AUTOSAR XML (schema 4-2-2)
package /STELLANTIS/EPT/ASWCs
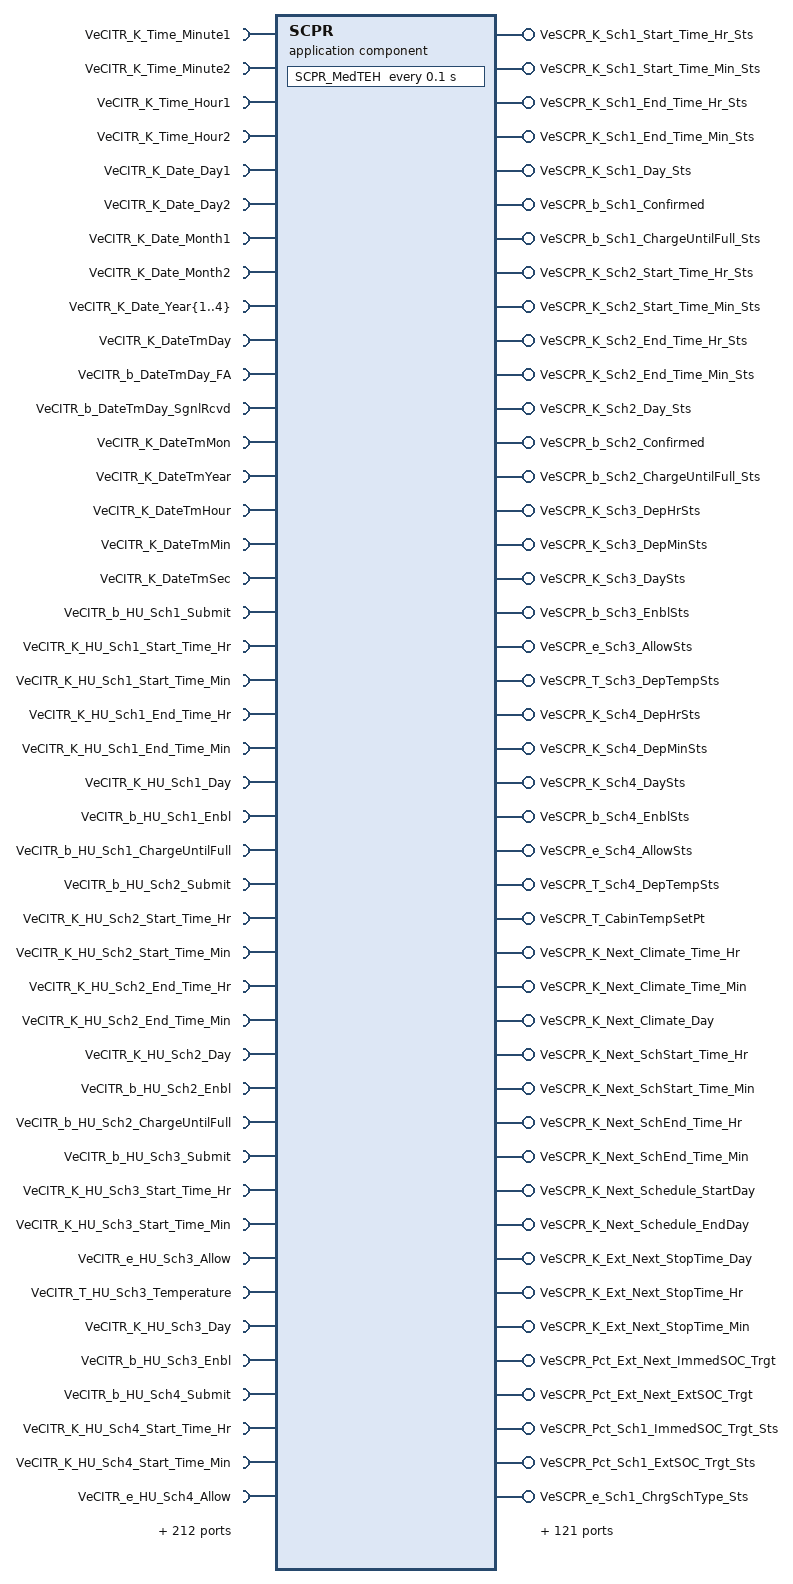
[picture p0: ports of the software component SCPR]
  application sw component type SCPR
    172 x require port:
      VeCITR_K_Time_Minute1: variation-point={short-label=vpVeCITR_K_Time_Minute1, sw-syscond=1}, nonqueued-receiver-com-spec{data-element=Value, init-value=0}, required-interface=VeCITR_K_Time_Minute1
      VeCITR_K_Time_Minute2: variation-point={short-label=vpVeCITR_K_Time_Minute2, sw-syscond=1}, nonqueued-receiver-com-spec{data-element=Value, init-value=0}, required-interface=VeCITR_K_Time_Minute2
      VeCITR_K_Time_Hour1: variation-point={short-label=vpVeCITR_K_Time_Hour1, sw-syscond=1}, nonqueued-receiver-com-spec{data-element=Value, init-value=0}, required-interface=VeCITR_K_Time_Hour1
      VeCITR_K_Time_Hour2: variation-point={short-label=vpVeCITR_K_Time_Hour2, sw-syscond=1}, nonqueued-receiver-com-spec{data-element=Value, init-value=0}, required-interface=VeCITR_K_Time_Hour2
      VeCITR_K_Date_Day1: variation-point={short-label=vpVeCITR_K_Date_Day1, sw-syscond=1}, nonqueued-receiver-com-spec{data-element=Value, init-value=0}, required-interface=VeCITR_K_Date_Day1
      VeCITR_K_Date_Day2: variation-point={short-label=vpVeCITR_K_Date_Day2, sw-syscond=1}, nonqueued-receiver-com-spec{data-element=Value, init-value=0}, required-interface=VeCITR_K_Date_Day2
      VeCITR_K_Date_Month1: variation-point={short-label=vpVeCITR_K_Date_Month1, sw-syscond=1}, nonqueued-receiver-com-spec{data-element=Value, init-value=0}, required-interface=VeCITR_K_Date_Month1
      VeCITR_K_Date_Month2: variation-point={short-label=vpVeCITR_K_Date_Month2, sw-syscond=1}, nonqueued-receiver-com-spec{data-element=Value, init-value=0}, required-interface=VeCITR_K_Date_Month2
      VeCITR_K_Date_Year{1..4}: variation-point={short-label=vpVeCITR_K_Date_Year{1..4}, sw-syscond=1}, nonqueued-receiver-com-spec{data-element=Value, init-value=0}, required-interface=VeCITR_K_Date_Year{1..4}
      VeCITR_K_DateTmDay: variation-point={short-label=vpVeCITR_K_DateTmDay, sw-syscond=1}, nonqueued-receiver-com-spec{data-element=Value, init-value=0}, required-interface=VeCITR_K_DateTmDay
      VeCITR_b_DateTmDay_FA: variation-point={short-label=vpVeCITR_b_DateTmDay_FA, sw-syscond=1}, nonqueued-receiver-com-spec{data-element=Value, init-value=0}, required-interface=VeCITR_b_DateTmDay_FA
      VeCITR_b_DateTmDay_SgnlRcvd: variation-point={short-label=vpVeCITR_b_DateTmDay_SgnlRcvd, sw-syscond=1}, nonqueued-receiver-com-spec{data-element=Value, init-value=0}, required-interface=VeCITR_b_DateTmDay_SgnlRcvd
      VeCITR_K_DateTmMon: variation-point={short-label=vpVeCITR_K_DateTmMon, sw-syscond=1}, nonqueued-receiver-com-spec{data-element=Value, init-value=0}, required-interface=VeCITR_K_DateTmMon
      VeCITR_K_DateTmYear: variation-point={short-label=vpVeCITR_K_DateTmYear, sw-syscond=1}, nonqueued-receiver-com-spec{data-element=Value, init-value=0}, required-interface=VeCITR_K_DateTmYear
      VeCITR_K_DateTmHour: variation-point={short-label=vpVeCITR_K_DateTmHour, sw-syscond=1}, nonqueued-receiver-com-spec{data-element=Value, init-value=0}, required-interface=VeCITR_K_DateTmHour
      VeCITR_K_DateTmMin: variation-point={short-label=vpVeCITR_K_DateTmMin, sw-syscond=1}, nonqueued-receiver-com-spec{data-element=Value, init-value=0}, required-interface=VeCITR_K_DateTmMin
      VeCITR_K_DateTmSec: variation-point={short-label=vpVeCITR_K_DateTmSec, sw-syscond=1}, nonqueued-receiver-com-spec{data-element=Value, init-value=0}, required-interface=VeCITR_K_DateTmSec
      VeCITR_b_HU_Sch1_Submit: variation-point={short-label=vpVeCITR_b_HU_Sch1_Submit, sw-syscond=1}, nonqueued-receiver-com-spec{data-element=Value, init-value=0}, required-interface=VeCITR_b_HU_Sch1_Submit
      VeCITR_K_HU_Sch1_Start_Time_Hr: variation-point={short-label=vpVeCITR_K_HU_Sch1_Start_Time_Hr, sw-syscond=1}, nonqueued-receiver-com-spec{data-element=Value, init-value=0}, required-interface=VeCITR_K_HU_Sch1_Start_Time_Hr
      VeCITR_K_HU_Sch1_Start_Time_Min: variation-point={short-label=vpVeCITR_K_HU_Sch1_Start_Time_Min, sw-syscond=1}, nonqueued-receiver-com-spec{data-element=Value, init-value=0}, required-interface=VeCITR_K_HU_Sch1_Start_Time_Min
      VeCITR_K_HU_Sch1_End_Time_Hr: variation-point={short-label=vpVeCITR_K_HU_Sch1_End_Time_Hr, sw-syscond=1}, nonqueued-receiver-com-spec{data-element=Value, init-value=0}, required-interface=VeCITR_K_HU_Sch1_End_Time_Hr
      VeCITR_K_HU_Sch1_End_Time_Min: variation-point={short-label=vpVeCITR_K_HU_Sch1_End_Time_Min, sw-syscond=1}, nonqueued-receiver-com-spec{data-element=Value, init-value=0}, required-interface=VeCITR_K_HU_Sch1_End_Time_Min
      VeCITR_K_HU_Sch1_Day: variation-point={short-label=vpVeCITR_K_HU_Sch1_Day, sw-syscond=1}, nonqueued-receiver-com-spec{data-element=Value, init-value=0}, required-interface=VeCITR_K_HU_Sch1_Day
      VeCITR_b_HU_Sch1_Enbl: variation-point={short-label=vpVeCITR_b_HU_Sch1_Enbl, sw-syscond=1}, nonqueued-receiver-com-spec{data-element=Value, init-value=0}, required-interface=VeCITR_b_HU_Sch1_Enbl
      VeCITR_b_HU_Sch1_ChargeUntilFull: variation-point={short-label=vpVeCITR_b_HU_Sch1_ChargeUntilFull, sw-syscond=1}, nonqueued-receiver-com-spec{data-element=Value, init-value=0}, required-interface=VeCITR_b_HU_Sch1_ChargeUntilFull
      VeCITR_b_HU_Sch2_Submit: variation-point={short-label=vpVeCITR_b_HU_Sch2_Submit, sw-syscond=1}, nonqueued-receiver-com-spec{data-element=Value, init-value=0}, required-interface=VeCITR_b_HU_Sch2_Submit
      VeCITR_K_HU_Sch2_Start_Time_Hr: variation-point={short-label=vpVeCITR_K_HU_Sch2_Start_Time_Hr, sw-syscond=1}, nonqueued-receiver-com-spec{data-element=Value, init-value=0}, required-interface=VeCITR_K_HU_Sch2_Start_Time_Hr
      VeCITR_K_HU_Sch2_Start_Time_Min: variation-point={short-label=vpVeCITR_K_HU_Sch2_Start_Time_Min, sw-syscond=1}, nonqueued-receiver-com-spec{data-element=Value, init-value=0}, required-interface=VeCITR_K_HU_Sch2_Start_Time_Min
      VeCITR_K_HU_Sch2_End_Time_Hr: variation-point={short-label=vpVeCITR_K_HU_Sch2_End_Time_Hr, sw-syscond=1}, nonqueued-receiver-com-spec{data-element=Value, init-value=0}, required-interface=VeCITR_K_HU_Sch2_End_Time_Hr
      VeCITR_K_HU_Sch2_End_Time_Min: variation-point={short-label=vpVeCITR_K_HU_Sch2_End_Time_Min, sw-syscond=1}, nonqueued-receiver-com-spec{data-element=Value, init-value=0}, required-interface=VeCITR_K_HU_Sch2_End_Time_Min
      VeCITR_K_HU_Sch2_Day: variation-point={short-label=vpVeCITR_K_HU_Sch2_Day, sw-syscond=1}, nonqueued-receiver-com-spec{data-element=Value, init-value=0}, required-interface=VeCITR_K_HU_Sch2_Day
      VeCITR_b_HU_Sch2_Enbl: variation-point={short-label=vpVeCITR_b_HU_Sch2_Enbl, sw-syscond=1}, nonqueued-receiver-com-spec{data-element=Value, init-value=0}, required-interface=VeCITR_b_HU_Sch2_Enbl
      VeCITR_b_HU_Sch2_ChargeUntilFull: variation-point={short-label=vpVeCITR_b_HU_Sch2_ChargeUntilFull, sw-syscond=1}, nonqueued-receiver-com-spec{data-element=Value, init-value=0}, required-interface=VeCITR_b_HU_Sch2_ChargeUntilFull
      VeCITR_b_HU_Sch3_Submit: variation-point={short-label=vpVeCITR_b_HU_Sch3_Submit, sw-syscond=1}, nonqueued-receiver-com-spec{data-element=Value, init-value=0}, required-interface=VeCITR_b_HU_Sch3_Submit
      VeCITR_K_HU_Sch3_Start_Time_Hr: variation-point={short-label=vpVeCITR_K_HU_Sch3_Start_Time_Hr, sw-syscond=1}, nonqueued-receiver-com-spec{data-element=Value, init-value=0}, required-interface=VeCITR_K_HU_Sch3_Start_Time_Hr
      VeCITR_K_HU_Sch3_Start_Time_Min: variation-point={short-label=vpVeCITR_K_HU_Sch3_Start_Time_Min, sw-syscond=1}, nonqueued-receiver-com-spec{data-element=Value, init-value=0}, required-interface=VeCITR_K_HU_Sch3_Start_Time_Min
      VeCITR_e_HU_Sch3_Allow: variation-point={short-label=vpVeCITR_e_HU_Sch3_Allow, sw-syscond=1}, nonqueued-receiver-com-spec{data-element=Value, init-value=CeCITR_e_AnyTime}, required-interface=VeCITR_e_HU_Sch3_Allow
      VeCITR_T_HU_Sch3_Temperature: variation-point={short-label=vpVeCITR_T_HU_Sch3_Temperature, sw-syscond=1}, nonqueued-receiver-com-spec{data-element=Value, init-value=0}, required-interface=VeCITR_T_HU_Sch3_Temperature
      VeCITR_K_HU_Sch3_Day: variation-point={short-label=vpVeCITR_K_HU_Sch3_Day, sw-syscond=1}, nonqueued-receiver-com-spec{data-element=Value, init-value=0}, required-interface=VeCITR_K_HU_Sch3_Day
      VeCITR_b_HU_Sch3_Enbl: variation-point={short-label=vpVeCITR_b_HU_Sch3_Enbl, sw-syscond=1}, nonqueued-receiver-com-spec{data-element=Value, init-value=0}, required-interface=VeCITR_b_HU_Sch3_Enbl
      VeCITR_b_HU_Sch4_Submit: variation-point={short-label=vpVeCITR_b_HU_Sch4_Submit, sw-syscond=1}, nonqueued-receiver-com-spec{data-element=Value, init-value=0}, required-interface=VeCITR_b_HU_Sch4_Submit
      VeCITR_K_HU_Sch4_Start_Time_Hr: variation-point={short-label=vpVeCITR_K_HU_Sch4_Start_Time_Hr, sw-syscond=1}, nonqueued-receiver-com-spec{data-element=Value, init-value=0}, required-interface=VeCITR_K_HU_Sch4_Start_Time_Hr
      VeCITR_K_HU_Sch4_Start_Time_Min: variation-point={short-label=vpVeCITR_K_HU_Sch4_Start_Time_Min, sw-syscond=1}, nonqueued-receiver-com-spec{data-element=Value, init-value=0}, required-interface=VeCITR_K_HU_Sch4_Start_Time_Min
      VeCITR_e_HU_Sch4_Allow: variation-point={short-label=vpVeCITR_e_HU_Sch4_Allow, sw-syscond=1}, nonqueued-receiver-com-spec{data-element=Value, init-value=CeCITR_e_AnyTime}, required-interface=VeCITR_e_HU_Sch4_Allow
      VeCITR_T_HU_Sch4_Temperature: variation-point={short-label=vpVeCITR_T_HU_Sch4_Temperature, sw-syscond=1}, nonqueued-receiver-com-spec{data-element=Value, init-value=0}, required-interface=VeCITR_T_HU_Sch4_Temperature
      VeCITR_K_HU_Sch4_Day: variation-point={short-label=vpVeCITR_K_HU_Sch4_Day, sw-syscond=1}, nonqueued-receiver-com-spec{data-element=Value, init-value=0}, required-interface=VeCITR_K_HU_Sch4_Day
      VeCITR_b_HU_Sch4_Enbl: variation-point={short-label=vpVeCITR_b_HU_Sch4_Enbl, sw-syscond=1}, nonqueued-receiver-com-spec{data-element=Value, init-value=0}, required-interface=VeCITR_b_HU_Sch4_Enbl
      VeCITR_b_Date_Day1_FA: variation-point={short-label=vpVeCITR_b_Date_Day1_FA, sw-syscond=1}, nonqueued-receiver-com-spec{data-element=Value, init-value=0}, required-interface=VeCITR_b_Date_Day1_FA
      VeCITR_b_Date_Day1_SgnlRcvd: variation-point={short-label=vpVeCITR_b_Date_Day1_SgnlRcvd, sw-syscond=1}, nonqueued-receiver-com-spec{data-element=Value, init-value=0}, required-interface=VeCITR_b_Date_Day1_SgnlRcvd
      VeCITR_b_HU_Sch1_Day_FA: variation-point={short-label=vpVeCITR_b_HU_Sch1_Day_FA, sw-syscond=1}, nonqueued-receiver-com-spec{data-element=Value, init-value=0}, required-interface=VeCITR_b_HU_Sch1_Day_FA
      VeCITR_b_HU_Sch1_Day_SgnlRcvd: variation-point={short-label=vpVeCITR_b_HU_Sch1_Day_SgnlRcvd, sw-syscond=1}, nonqueued-receiver-com-spec{data-element=Value, init-value=0}, required-interface=VeCITR_b_HU_Sch1_Day_SgnlRcvd
      VeCITR_b_TBM_Sch1_Day_FA: variation-point={short-label=vpVeCITR_b_TBM_Sch1_Day_FA, sw-syscond=1}, nonqueued-receiver-com-spec{data-element=Value, init-value=0}, required-interface=VeCITR_b_TBM_Sch1_Day_FA
      VeCITR_b_TBM_Sch1_Day_SgnlRcvd: variation-point={short-label=vpVeCITR_b_TBM_Sch1_Day_SgnlRcvd, sw-syscond=1}, nonqueued-receiver-com-spec{data-element=Value, init-value=0}, required-interface=VeCITR_b_TBM_Sch1_Day_SgnlRcvd
      VeCITR_b_HU_Sch2_Day_FA: variation-point={short-label=vpVeCITR_b_HU_Sch2_Day_FA, sw-syscond=1}, nonqueued-receiver-com-spec{data-element=Value, init-value=0}, required-interface=VeCITR_b_HU_Sch2_Day_FA
      VeCITR_b_HU_Sch2_Day_SgnlRcvd: variation-point={short-label=vpVeCITR_b_HU_Sch2_Day_SgnlRcvd, sw-syscond=1}, nonqueued-receiver-com-spec{data-element=Value, init-value=0}, required-interface=VeCITR_b_HU_Sch2_Day_SgnlRcvd
      VeCITR_b_TBM_Sch2_Day_FA: variation-point={short-label=vpVeCITR_b_TBM_Sch2_Day_FA, sw-syscond=1}, nonqueued-receiver-com-spec{data-element=Value, init-value=0}, required-interface=VeCITR_b_TBM_Sch2_Day_FA
      VeCITR_b_TBM_Sch2_Day_SgnlRcvd: variation-point={short-label=vpVeCITR_b_TBM_Sch2_Day_SgnlRcvd, sw-syscond=1}, nonqueued-receiver-com-spec{data-element=Value, init-value=0}, required-interface=VeCITR_b_TBM_Sch2_Day_SgnlRcvd
      VeCITR_b_HU_Sch3_Day_FA: variation-point={short-label=vpVeCITR_b_HU_Sch3_Day_FA, sw-syscond=1}, nonqueued-receiver-com-spec{data-element=Value, init-value=0}, required-interface=VeCITR_b_HU_Sch3_Day_FA
      VeCITR_b_HU_Sch3_Day_SgnlRcvd: variation-point={short-label=vpVeCITR_b_HU_Sch3_Day_SgnlRcvd, sw-syscond=1}, nonqueued-receiver-com-spec{data-element=Value, init-value=0}, required-interface=VeCITR_b_HU_Sch3_Day_SgnlRcvd
      VeCITR_b_TBM_Sch3_Day_FA: variation-point={short-label=vpVeCITR_b_TBM_Sch3_Day_FA, sw-syscond=1}, nonqueued-receiver-com-spec{data-element=Value, init-value=0}, required-interface=VeCITR_b_TBM_Sch3_Day_FA
      VeCITR_b_TBM_Sch3_Day_SgnlRcvd: variation-point={short-label=vpVeCITR_b_TBM_Sch3_Day_SgnlRcvd, sw-syscond=1}, nonqueued-receiver-com-spec{data-element=Value, init-value=0}, required-interface=VeCITR_b_TBM_Sch3_Day_SgnlRcvd
      VeCITR_b_HU_Sch4_Day_FA: variation-point={short-label=vpVeCITR_b_HU_Sch4_Day_FA, sw-syscond=1}, nonqueued-receiver-com-spec{data-element=Value, init-value=0}, required-interface=VeCITR_b_HU_Sch4_Day_FA
      VeCITR_b_HU_Sch4_Day_SgnlRcvd: variation-point={short-label=vpVeCITR_b_HU_Sch4_Day_SgnlRcvd, sw-syscond=1}, nonqueued-receiver-com-spec{data-element=Value, init-value=0}, required-interface=VeCITR_b_HU_Sch4_Day_SgnlRcvd
      VeCITR_b_TBM_Sch4_Day_FA: variation-point={short-label=vpVeCITR_b_TBM_Sch4_Day_FA, sw-syscond=1}, nonqueued-receiver-com-spec{data-element=Value, init-value=0}, required-interface=VeCITR_b_TBM_Sch4_Day_FA
      VeCITR_b_TBM_Sch4_Day_SgnlRcvd: variation-point={short-label=vpVeCITR_b_TBM_Sch4_Day_SgnlRcvd, sw-syscond=1}, nonqueued-receiver-com-spec{data-element=Value, init-value=0}, required-interface=VeCITR_b_TBM_Sch4_Day_SgnlRcvd
      VeCITR_b_HU_Sch1_Start_Time_HrFA: variation-point={short-label=vpVeCITR_b_HU_Sch1_Start_Time_HrFA, sw-syscond=1}, nonqueued-receiver-com-spec{data-element=Value, init-value=0}, required-interface=VeCITR_b_HU_Sch1_Start_Time_HrFA
      VeCITR_b_HU_Sch1_Start_Time_MinFA: variation-point={short-label=vpVeCITR_b_HU_Sch1_Start_Time_MinFA, sw-syscond=1}, nonqueued-receiver-com-spec{data-element=Value, init-value=0}, required-interface=VeCITR_b_HU_Sch1_Start_Time_MinFA
      VeCITR_b_HU_Sch1_End_Time_HrFA: variation-point={short-label=vpVeCITR_b_HU_Sch1_End_Time_HrFA, sw-syscond=1}, nonqueued-receiver-com-spec{data-element=Value, init-value=0}, required-interface=VeCITR_b_HU_Sch1_End_Time_HrFA
      VeCITR_b_HU_Sch1_End_Time_MinFA: variation-point={short-label=vpVeCITR_b_HU_Sch1_End_Time_MinFA, sw-syscond=1}, nonqueued-receiver-com-spec{data-element=Value, init-value=0}, required-interface=VeCITR_b_HU_Sch1_End_Time_MinFA
      VeCITR_b_HU_Sch2_Start_Time_HrFA: variation-point={short-label=vpVeCITR_b_HU_Sch2_Start_Time_HrFA, sw-syscond=1}, nonqueued-receiver-com-spec{data-element=Value, init-value=0}, required-interface=VeCITR_b_HU_Sch2_Start_Time_HrFA
      VeCITR_b_HU_Sch2_Start_Time_MinFA: variation-point={short-label=vpVeCITR_b_HU_Sch2_Start_Time_MinFA, sw-syscond=1}, nonqueued-receiver-com-spec{data-element=Value, init-value=0}, required-interface=VeCITR_b_HU_Sch2_Start_Time_MinFA
      VeCITR_b_HU_Sch2_End_Time_HrFA: variation-point={short-label=vpVeCITR_b_HU_Sch2_End_Time_HrFA, sw-syscond=1}, nonqueued-receiver-com-spec{data-element=Value, init-value=0}, required-interface=VeCITR_b_HU_Sch2_End_Time_HrFA
      VeCITR_b_HU_Sch2_End_Time_MinFA: variation-point={short-label=vpVeCITR_b_HU_Sch2_End_Time_MinFA, sw-syscond=1}, nonqueued-receiver-com-spec{data-element=Value, init-value=0}, required-interface=VeCITR_b_HU_Sch2_End_Time_MinFA
      VeCITR_b_HU_Sch3_Start_Time_HrFA: variation-point={short-label=vpVeCITR_b_HU_Sch3_Start_Time_HrFA, sw-syscond=1}, nonqueued-receiver-com-spec{data-element=Value, init-value=0}, required-interface=VeCITR_b_HU_Sch3_Start_Time_HrFA
      VeCITR_b_HU_Sch3_Start_Time_MinFA: variation-point={short-label=vpVeCITR_b_HU_Sch3_Start_Time_MinFA, sw-syscond=1}, nonqueued-receiver-com-spec{data-element=Value, init-value=0}, required-interface=VeCITR_b_HU_Sch3_Start_Time_MinFA
      VeCITR_b_HU_Sch4_Start_Time_HrFA: variation-point={short-label=vpVeCITR_b_HU_Sch4_Start_Time_HrFA, sw-syscond=1}, nonqueued-receiver-com-spec{data-element=Value, init-value=0}, required-interface=VeCITR_b_HU_Sch4_Start_Time_HrFA
      VeCITR_b_HU_Sch4_Start_Time_MinFA: variation-point={short-label=vpVeCITR_b_HU_Sch4_Start_Time_MinFA, sw-syscond=1}, nonqueued-receiver-com-spec{data-element=Value, init-value=0}, required-interface=VeCITR_b_HU_Sch4_Start_Time_MinFA
      VeOBCR_e_ChargingSystemSts: variation-point={short-label=vpVeOBCR_e_ChargingSystemSts, sw-syscond=1}, nonqueued-receiver-com-spec{data-element=Value, init-value=CeOBCR_e_NotCharging}, required-interface=VeOBCR_e_ChargingSystemSts
      VeOBCR_b_PluggedIn: variation-point={short-label=vpVeOBCR_b_PluggedIn, sw-syscond=1}, nonqueued-receiver-com-spec{data-element=Value, init-value=0}, required-interface=VeOBCR_b_PluggedIn
      VePMDR_e_PMM_PowerMode: variation-point={short-label=vpVePMDR_e_PMM_PowerMode, sw-syscond=1}, nonqueued-receiver-com-spec{data-element=Value, init-value=CePMDR_e_PowerMode_Off}, required-interface=VePMDR_e_PMM_PowerMode
      VeOBCR_b_SmartEvse_Dtctd: variation-point={short-label=vpVeOBCR_b_SmartEvse_Dtctd, sw-syscond=1}, nonqueued-receiver-com-spec{data-element=Value, init-value=0}, required-interface=VeOBCR_b_SmartEvse_Dtctd
      VeBPCR_Pct_HV_BatPackSOC_Arb: variation-point={short-label=vpVeBPCR_Pct_HV_BatPackSOC_Arb, sw-syscond=1}, nonqueued-receiver-com-spec{data-element=Value, init-value=0}, required-interface=VeBPCR_Pct_HV_BatPackSOC_Arb
      VeSSDR_b_HVBatPerWUThermal: variation-point={short-label=vpVeSSDR_b_HVBatPerWUThermal, sw-syscond=1}, nonqueued-receiver-com-spec{data-element=Value, init-value=0}, required-interface=VeSSDR_b_HVBatPerWUThermal
      VeTHMR_b_RdyForShtDwn: variation-point={short-label=vpVeTHMR_b_RdyForShtDwn, sw-syscond=1}, nonqueued-receiver-com-spec{data-element=Value, init-value=0}, required-interface=VeTHMR_b_RdyForShtDwn
      VeOBCR_e_ChargingLevel: variation-point={short-label=vpVeOBCR_e_ChargingLevel, sw-syscond=1}, nonqueued-receiver-com-spec{data-element=Value, init-value=CeOBCR_e_ChargingLvlDefault}, required-interface=VeOBCR_e_ChargingLevel
      VePLTR_b_ChargeReqSgnlRcvd: variation-point={short-label=vpVePLTR_b_ChargeReqSgnlRcvd, sw-syscond=1}, nonqueued-receiver-com-spec{data-element=Value, init-value=0}, required-interface=VePLTR_b_ChargeReqSgnlRcvd
      VePLTR_b_ChargeReq: variation-point={short-label=vpVePLTR_b_ChargeReq, sw-syscond=1}, nonqueued-receiver-com-spec{data-element=Value, init-value=0}, required-interface=VePLTR_b_ChargeReq
      VeCITR_b_ChargeNow: variation-point={short-label=vpVeCITR_b_ChargeNow, sw-syscond=1}, nonqueued-receiver-com-spec{data-element=Value, init-value=0}, required-interface=VeCITR_b_ChargeNow
      VeCITR_b_ChrgPortButton_Sts: variation-point={short-label=vpVeCITR_b_ChrgPortButton_Sts, sw-syscond=1}, nonqueued-receiver-com-spec{data-element=Value, init-value=0}, required-interface=VeCITR_b_ChrgPortButton_Sts
      VeCITR_e_DoorLockLastElSts: variation-point={short-label=vpVeCITR_e_DoorLockLastElSts, sw-syscond=1}, nonqueued-receiver-com-spec{data-element=Value, init-value=CeOBCR_e_LKD}, required-interface=VeCITR_e_DoorLockLastElSts
      VePLTR_t_RTC_CurrentTime: variation-point={short-label=vpVePLTR_t_RTC_CurrentTime, sw-syscond=1}, nonqueued-receiver-com-spec{data-element=Value, init-value=0}, required-interface=VePLTR_t_RTC_CurrentTime
      VeIDCR_I_ChrgCrntAvail: variation-point={short-label=vpVeIDCR_I_ChrgCrntAvail, sw-syscond=1}, nonqueued-receiver-com-spec{data-element=Value, init-value=0}, required-interface=VeIDCR_I_ChrgCrntAvail
      VeBPCR_q_FullAmpHrCap: variation-point={short-label=vpVeBPCR_q_FullAmpHrCap, sw-syscond=1}, nonqueued-receiver-com-spec{data-element=Value, init-value=0}, required-interface=VeBPCR_q_FullAmpHrCap
      VeCITR_e_RRM_VP_Level: variation-point={short-label=vpVeCITR_e_RRM_VP_Level, sw-syscond=1}, nonqueued-receiver-com-spec{data-element=Value, init-value=CeCITR_e_RRM_VP_Absent}, required-interface=VeCITR_e_RRM_VP_Level
      VeSSDR_b_HV_PerWU_CabinPre: variation-point={short-label=vpVeSSDR_b_HV_PerWU_CabinPre, sw-syscond=1}, nonqueued-receiver-com-spec{data-element=Value, init-value=0}, required-interface=VeSSDR_b_HV_PerWU_CabinPre
      VeOBCR_b_ChrgSysFault: variation-point={short-label=vpVeOBCR_b_ChrgSysFault, sw-syscond=1}, nonqueued-receiver-com-spec{data-element=Value, init-value=0}, required-interface=VeOBCR_b_ChrgSysFault
      VeOBCR_e_ChargeType: variation-point={short-label=vpVeOBCR_e_ChargeType, sw-syscond=1}, nonqueued-receiver-com-spec{data-element=Value, init-value=CeOBCR_e_AC}, required-interface=VeOBCR_e_ChargeType
      VeSSDR_b_CabPrecDny_BattCond: variation-point={short-label=vpVeSSDR_b_CabPrecDny_BattCond, sw-syscond=1}, nonqueued-receiver-com-spec{data-element=Value, init-value=0}, required-interface=VeSSDR_b_CabPrecDny_BattCond
      VeOBCR_I_MaxAllowedCurr: variation-point={short-label=vpVeOBCR_I_MaxAllowedCurr, sw-syscond=1}, nonqueued-receiver-com-spec{data-element=Value, init-value=0}, required-interface=VeOBCR_I_MaxAllowedCurr
      VeCITR_b_TBM_ChargeNow: variation-point={short-label=vpVeCITR_b_TBM_ChargeNow, sw-syscond=1}, nonqueued-receiver-com-spec{data-element=Value, init-value=0}, required-interface=VeCITR_b_TBM_ChargeNow
      VeCITR_b_TBM_Sch1_Submit: variation-point={short-label=vpVeCITR_b_TBM_Sch1_Submit, sw-syscond=1}, nonqueued-receiver-com-spec{data-element=Value, init-value=0}, required-interface=VeCITR_b_TBM_Sch1_Submit
      VeCITR_K_TBM_Sch1_Start_Time_Hr: variation-point={short-label=vpVeCITR_K_TBM_Sch1_Start_Time_Hr, sw-syscond=1}, nonqueued-receiver-com-spec{data-element=Value, init-value=0}, required-interface=VeCITR_K_TBM_Sch1_Start_Time_Hr
      VeCITR_K_TBM_Sch1_Start_Time_Min: variation-point={short-label=vpVeCITR_K_TBM_Sch1_Start_Time_Min, sw-syscond=1}, nonqueued-receiver-com-spec{data-element=Value, init-value=0}, required-interface=VeCITR_K_TBM_Sch1_Start_Time_Min
      VeCITR_K_TBM_Sch1_End_Time_Hr: variation-point={short-label=vpVeCITR_K_TBM_Sch1_End_Time_Hr, sw-syscond=1}, nonqueued-receiver-com-spec{data-element=Value, init-value=0}, required-interface=VeCITR_K_TBM_Sch1_End_Time_Hr
      VeCITR_K_TBM_Sch1_End_Time_Min: variation-point={short-label=vpVeCITR_K_TBM_Sch1_End_Time_Min, sw-syscond=1}, nonqueued-receiver-com-spec{data-element=Value, init-value=0}, required-interface=VeCITR_K_TBM_Sch1_End_Time_Min
      VeCITR_K_TBM_Sch1_Day: variation-point={short-label=vpVeCITR_K_TBM_Sch1_Day, sw-syscond=1}, nonqueued-receiver-com-spec{data-element=Value, init-value=0}, required-interface=VeCITR_K_TBM_Sch1_Day
      VeCITR_b_TBM_Sch1_Enbl: variation-point={short-label=vpVeCITR_b_TBM_Sch1_Enbl, sw-syscond=1}, nonqueued-receiver-com-spec{data-element=Value, init-value=0}, required-interface=VeCITR_b_TBM_Sch1_Enbl
      VeCITR_b_TBM_Sch1_ChargeUntilFull: variation-point={short-label=vpVeCITR_b_TBM_Sch1_ChargeUntilFull, sw-syscond=1}, nonqueued-receiver-com-spec{data-element=Value, init-value=0}, required-interface=VeCITR_b_TBM_Sch1_ChargeUntilFull
      VeCITR_b_TBM_Sch2_Submit: variation-point={short-label=vpVeCITR_b_TBM_Sch2_Submit, sw-syscond=1}, nonqueued-receiver-com-spec{data-element=Value, init-value=0}, required-interface=VeCITR_b_TBM_Sch2_Submit
      VeCITR_K_TBM_Sch2_Start_Time_Hr: variation-point={short-label=vpVeCITR_K_TBM_Sch2_Start_Time_Hr, sw-syscond=1}, nonqueued-receiver-com-spec{data-element=Value, init-value=0}, required-interface=VeCITR_K_TBM_Sch2_Start_Time_Hr
      VeCITR_K_TBM_Sch2_Start_Time_Min: variation-point={short-label=vpVeCITR_K_TBM_Sch2_Start_Time_Min, sw-syscond=1}, nonqueued-receiver-com-spec{data-element=Value, init-value=0}, required-interface=VeCITR_K_TBM_Sch2_Start_Time_Min
      VeCITR_K_TBM_Sch2_End_Time_Hr: variation-point={short-label=vpVeCITR_K_TBM_Sch2_End_Time_Hr, sw-syscond=1}, nonqueued-receiver-com-spec{data-element=Value, init-value=0}, required-interface=VeCITR_K_TBM_Sch2_End_Time_Hr
      VeCITR_K_TBM_Sch2_End_Time_Min: variation-point={short-label=vpVeCITR_K_TBM_Sch2_End_Time_Min, sw-syscond=1}, nonqueued-receiver-com-spec{data-element=Value, init-value=0}, required-interface=VeCITR_K_TBM_Sch2_End_Time_Min
      VeCITR_K_TBM_Sch2_Day: variation-point={short-label=vpVeCITR_K_TBM_Sch2_Day, sw-syscond=1}, nonqueued-receiver-com-spec{data-element=Value, init-value=0}, required-interface=VeCITR_K_TBM_Sch2_Day
      VeCITR_b_TBM_Sch2_Enbl: variation-point={short-label=vpVeCITR_b_TBM_Sch2_Enbl, sw-syscond=1}, nonqueued-receiver-com-spec{data-element=Value, init-value=0}, required-interface=VeCITR_b_TBM_Sch2_Enbl
      VeCITR_b_TBM_Sch2_ChargeUntilFull: variation-point={short-label=vpVeCITR_b_TBM_Sch2_ChargeUntilFull, sw-syscond=1}, nonqueued-receiver-com-spec{data-element=Value, init-value=0}, required-interface=VeCITR_b_TBM_Sch2_ChargeUntilFull
      VeCITR_b_TBM_Sch3_Submit: variation-point={short-label=vpVeCITR_b_TBM_Sch3_Submit, sw-syscond=1}, nonqueued-receiver-com-spec{data-element=Value, init-value=0}, required-interface=VeCITR_b_TBM_Sch3_Submit
      VeCITR_K_TBM_Sch3_Start_Time_Hr: variation-point={short-label=vpVeCITR_K_TBM_Sch3_Start_Time_Hr, sw-syscond=1}, nonqueued-receiver-com-spec{data-element=Value, init-value=0}, required-interface=VeCITR_K_TBM_Sch3_Start_Time_Hr
      VeCITR_K_TBM_Sch3_Start_Time_Min: variation-point={short-label=vpVeCITR_K_TBM_Sch3_Start_Time_Min, sw-syscond=1}, nonqueued-receiver-com-spec{data-element=Value, init-value=0}, required-interface=VeCITR_K_TBM_Sch3_Start_Time_Min
      VeCITR_K_TBM_Sch3_Day: variation-point={short-label=vpVeCITR_K_TBM_Sch3_Day, sw-syscond=1}, nonqueued-receiver-com-spec{data-element=Value, init-value=0}, required-interface=VeCITR_K_TBM_Sch3_Day
      VeCITR_b_TBM_Sch3_Enbl: variation-point={short-label=vpVeCITR_b_TBM_Sch3_Enbl, sw-syscond=1}, nonqueued-receiver-com-spec{data-element=Value, init-value=0}, required-interface=VeCITR_b_TBM_Sch3_Enbl
      VeCITR_e_TBM_Sch3_Allow: variation-point={short-label=vpVeCITR_e_TBM_Sch3_Allow, sw-syscond=1}, nonqueued-receiver-com-spec{data-element=Value, init-value=CeCITR_e_AnyTime}, required-interface=VeCITR_e_TBM_Sch3_Allow
      VeCITR_b_TBM_Sch3_AllowFA: variation-point={short-label=vpVeCITR_b_TBM_Sch3_AllowFA, sw-syscond=1}, nonqueued-receiver-com-spec{data-element=Value, init-value=0}, required-interface=VeCITR_b_TBM_Sch3_AllowFA
      VeCITR_T_TBM_Sch3_Temperature: variation-point={short-label=vpVeCITR_T_TBM_Sch3_Temperature, sw-syscond=1}, nonqueued-receiver-com-spec{data-element=Value, init-value=0}, required-interface=VeCITR_T_TBM_Sch3_Temperature
      VeCITR_b_TBM_Sch3_TemperatureFA: variation-point={short-label=vpVeCITR_b_TBM_Sch3_TemperatureFA, sw-syscond=1}, nonqueued-receiver-com-spec{data-element=Value, init-value=0}, required-interface=VeCITR_b_TBM_Sch3_TemperatureFA
      VeCITR_b_TBM_Sch4_Submit: variation-point={short-label=vpVeCITR_b_TBM_Sch4_Submit, sw-syscond=1}, nonqueued-receiver-com-spec{data-element=Value, init-value=0}, required-interface=VeCITR_b_TBM_Sch4_Submit
      VeCITR_K_TBM_Sch4_Start_Time_Min: variation-point={short-label=vpVeCITR_K_TBM_Sch4_Start_Time_Min, sw-syscond=1}, nonqueued-receiver-com-spec{data-element=Value, init-value=0}, required-interface=VeCITR_K_TBM_Sch4_Start_Time_Min
      VeCITR_K_TBM_Sch4_Start_Time_Hr: variation-point={short-label=vpVeCITR_K_TBM_Sch4_Start_Time_Hr, sw-syscond=1}, nonqueued-receiver-com-spec{data-element=Value, init-value=0}, required-interface=VeCITR_K_TBM_Sch4_Start_Time_Hr
      VeCITR_K_TBM_Sch4_Day: variation-point={short-label=vpVeCITR_K_TBM_Sch4_Day, sw-syscond=1}, nonqueued-receiver-com-spec{data-element=Value, init-value=0}, required-interface=VeCITR_K_TBM_Sch4_Day
      VeCITR_b_TBM_Sch4_Enbl: variation-point={short-label=vpVeCITR_b_TBM_Sch4_Enbl, sw-syscond=1}, nonqueued-receiver-com-spec{data-element=Value, init-value=0}, required-interface=VeCITR_b_TBM_Sch4_Enbl
      VeCITR_e_TBM_Sch4_Allow: variation-point={short-label=vpVeCITR_e_TBM_Sch4_Allow, sw-syscond=1}, nonqueued-receiver-com-spec{data-element=Value, init-value=CeCITR_e_AnyTime}, required-interface=VeCITR_e_TBM_Sch4_Allow
      VeCITR_b_TBM_Sch4_AllowFA: variation-point={short-label=vpVeCITR_b_TBM_Sch4_AllowFA, sw-syscond=1}, nonqueued-receiver-com-spec{data-element=Value, init-value=0}, required-interface=VeCITR_b_TBM_Sch4_AllowFA
      VeCITR_T_TBM_Sch4_Temperature: variation-point={short-label=vpVeCITR_T_TBM_Sch4_Temperature, sw-syscond=1}, nonqueued-receiver-com-spec{data-element=Value, init-value=0}, required-interface=VeCITR_T_TBM_Sch4_Temperature
      VeCITR_b_TBM_Sch4_TemperatureFA: variation-point={short-label=vpVeCITR_b_TBM_Sch4_TemperatureFA, sw-syscond=1}, nonqueued-receiver-com-spec{data-element=Value, init-value=0}, required-interface=VeCITR_b_TBM_Sch4_TemperatureFA
      VeCITR_b_HU_Sch3_TemperatureFA: variation-point={short-label=vpVeCITR_b_HU_Sch3_TemperatureFA, sw-syscond=1}, nonqueued-receiver-com-spec{data-element=Value, init-value=0}, required-interface=VeCITR_b_HU_Sch3_TemperatureFA
      VeCITR_b_HU_Sch3_AllowFA: variation-point={short-label=vpVeCITR_b_HU_Sch3_AllowFA, sw-syscond=1}, nonqueued-receiver-com-spec{data-element=Value, init-value=0}, required-interface=VeCITR_b_HU_Sch3_AllowFA
      VeCITR_b_HU_Sch4_TemperatureFA: variation-point={short-label=vpVeCITR_b_HU_Sch4_TemperatureFA, sw-syscond=1}, nonqueued-receiver-com-spec{data-element=Value, init-value=0}, required-interface=VeCITR_b_HU_Sch4_TemperatureFA
      VeCITR_b_HU_Sch4_AllowFA: variation-point={short-label=vpVeCITR_b_HU_Sch4_AllowFA, sw-syscond=1}, nonqueued-receiver-com-spec{data-element=Value, init-value=0}, required-interface=VeCITR_b_HU_Sch4_AllowFA
      VeOBCR_I_ChrgCurrEstSOC: variation-point={short-label=vpVeOBCR_I_ChrgCurrEstSOC, sw-syscond=1}, nonqueued-receiver-com-spec{data-element=Value, init-value=0}, required-interface=VeOBCR_I_ChrgCurrEstSOC
      VePLTR_e_ProxyHybridType: variation-point={short-label=vpVePLTR_e_ProxyHybridType, sw-syscond=1}, nonqueued-receiver-com-spec{data-element=Value, init-value=CePLTR_e_NotApplicable}, required-interface=VePLTR_e_ProxyHybridType
      VeOBCR_e_ChrgSysStat_SF: variation-point={short-label=vpVeOBCR_e_ChrgSysStat_SF, sw-syscond=1}, nonqueued-receiver-com-spec{data-element=Value, init-value=CeOBCR_e_PowerUp}, required-interface=VeOBCR_e_ChrgSysStat_SF
      VeCITR_e_FOTA_Install_Type: variation-point={short-label=vpVeCITR_e_FOTA_Install_Type, sw-syscond=1}, nonqueued-receiver-com-spec{data-element=Value, init-value=CeCITR_e_NoFOTA}, required-interface=VeCITR_e_FOTA_Install_Type
      VeCITR_e_FOTA_Install_Status: variation-point={short-label=vpVeCITR_e_FOTA_Install_Status, sw-syscond=1}, nonqueued-receiver-com-spec{data-element=Value, init-value=CeCITR_e_Installation_Default}, required-interface=VeCITR_e_FOTA_Install_Status
      VeCITR_b_FOTA_Install_Type_FA: variation-point={short-label=vpVeCITR_b_FOTA_Install_Type_FA, sw-syscond=1}, nonqueued-receiver-com-spec{data-element=Value, init-value=0}, required-interface=VeCITR_b_FOTA_Install_Type_FA
      VeHPMR_e_HybSysSt: variation-point={short-label=vpVeHPMR_e_HybSysSt, sw-syscond=1}, nonqueued-receiver-com-spec{data-element=Value, init-value=CeHPMR_e_POWERUP}, required-interface=VeHPMR_e_HybSysSt
      VeCITR_Pct_TBM_ImmChrgTarget1: variation-point={short-label=vpVeCITR_Pct_TBM_ImmChrgTarget1, sw-syscond=1}, nonqueued-receiver-com-spec{data-element=Value, init-value=0}, required-interface=VeCITR_Pct_TBM_ImmChrgTarget1
      VeCITR_Pct_TBM_ExtChrgTarget1: variation-point={short-label=vpVeCITR_Pct_TBM_ExtChrgTarget1, sw-syscond=1}, nonqueued-receiver-com-spec{data-element=Value, init-value=0}, required-interface=VeCITR_Pct_TBM_ExtChrgTarget1
      VeCITR_Pct_HU_ImmChrgTarget1: variation-point={short-label=vpVeCITR_Pct_HU_ImmChrgTarget1, sw-syscond=1}, nonqueued-receiver-com-spec{data-element=Value, init-value=0}, required-interface=VeCITR_Pct_HU_ImmChrgTarget1
      VeCITR_Pct_HU_ExtChrgTarget1: variation-point={short-label=vpVeCITR_Pct_HU_ExtChrgTarget1, sw-syscond=1}, nonqueued-receiver-com-spec{data-element=Value, init-value=0}, required-interface=VeCITR_Pct_HU_ExtChrgTarget1
      VeCITR_e_TBM_ChrgSchedType1: variation-point={short-label=vpVeCITR_e_TBM_ChrgSchedType1, sw-syscond=1}, nonqueued-receiver-com-spec{data-element=Value, init-value=CeCITR_e_No_Selection}, required-interface=VeCITR_e_TBM_ChrgSchedType1
      VeCITR_e_HU_ChrgSchedType1: variation-point={short-label=vpVeCITR_e_HU_ChrgSchedType1, sw-syscond=1}, nonqueued-receiver-com-spec{data-element=Value, init-value=CeCITR_e_No_Selection}, required-interface=VeCITR_e_HU_ChrgSchedType1
      VeCITR_Pct_TBM_ImmChrgTarget2: variation-point={short-label=vpVeCITR_Pct_TBM_ImmChrgTarget2, sw-syscond=1}, nonqueued-receiver-com-spec{data-element=Value, init-value=0}, required-interface=VeCITR_Pct_TBM_ImmChrgTarget2
      VeCITR_Pct_TBM_ExtChrgTarget2: variation-point={short-label=vpVeCITR_Pct_TBM_ExtChrgTarget2, sw-syscond=1}, nonqueued-receiver-com-spec{data-element=Value, init-value=0}, required-interface=VeCITR_Pct_TBM_ExtChrgTarget2
      VeCITR_Pct_HU_ImmChrgTarget2: variation-point={short-label=vpVeCITR_Pct_HU_ImmChrgTarget2, sw-syscond=1}, nonqueued-receiver-com-spec{data-element=Value, init-value=0}, required-interface=VeCITR_Pct_HU_ImmChrgTarget2
      VeCITR_Pct_HU_ExtChrgTarget2: variation-point={short-label=vpVeCITR_Pct_HU_ExtChrgTarget2, sw-syscond=1}, nonqueued-receiver-com-spec{data-element=Value, init-value=0}, required-interface=VeCITR_Pct_HU_ExtChrgTarget2
      VeCITR_e_TBM_ChrgSchedType2: variation-point={short-label=vpVeCITR_e_TBM_ChrgSchedType2, sw-syscond=1}, nonqueued-receiver-com-spec{data-element=Value, init-value=CeCITR_e_No_Selection}, required-interface=VeCITR_e_TBM_ChrgSchedType2
      VeCITR_e_HU_ChrgSchedType2: variation-point={short-label=vpVeCITR_e_HU_ChrgSchedType2, sw-syscond=1}, nonqueued-receiver-com-spec{data-element=Value, init-value=CeCITR_e_No_Selection}, required-interface=VeCITR_e_HU_ChrgSchedType2
      VeCITR_e_CoopCh_ChrgCmd: variation-point={short-label=vpVeCITR_e_CoopCh_ChrgCmd, sw-syscond=1}, nonqueued-receiver-com-spec{data-element=Value, init-value=CeCITR_e_DEFAULT}, required-interface=VeCITR_e_CoopCh_ChrgCmd
      VeCITR_b_CoopCh_VehLocation: variation-point={short-label=vpVeCITR_b_CoopCh_VehLocation, sw-syscond=1}, nonqueued-receiver-com-spec{data-element=Value, init-value=0}, required-interface=VeCITR_b_CoopCh_VehLocation
      VeHMIR_Pct_HVBatSOC_HCP: variation-point={short-label=vpVeHMIR_Pct_HVBatSOC_HCP, sw-syscond=1}, nonqueued-receiver-com-spec{data-element=Value, init-value=0}, required-interface=VeHMIR_Pct_HVBatSOC_HCP
      VeCITR_b_TBMStopChrg: variation-point={short-label=vpVeCITR_b_TBMStopChrg, sw-syscond=1}, nonqueued-receiver-com-spec{data-element=Value, init-value=0}, required-interface=VeCITR_b_TBMStopChrg
      VeTPCR_b_RacePrepAmbCheck: variation-point={short-label=vpVeTPCR_b_RacePrepAmbCheck, sw-syscond=1}, nonqueued-receiver-com-spec{data-element=Value, init-value=0}, required-interface=VeTPCR_b_RacePrepAmbCheck
      VeTPCR_b_RacePrepEVSysStatus: variation-point={short-label=vpVeTPCR_b_RacePrepEVSysStatus, sw-syscond=1}, nonqueued-receiver-com-spec{data-element=Value, init-value=0}, required-interface=VeTPCR_b_RacePrepEVSysStatus
      VeTIMR_e_RacePrep: variation-point={short-label=vpVeTIMR_e_RacePrep, sw-syscond=1}, nonqueued-receiver-com-spec{data-element=Value, init-value=CeTIMR_e_RacePrep_Off}, required-interface=VeTIMR_e_RacePrep
      VeDMAB_y_StatusByte_IgnKeyOffTmrPerfTooFast: variation-point={short-label=vpVeDMAB_y_StatusByte_IgnKeyOffTmrPerfTooFast, sw-syscond=1}, nonqueued-receiver-com-spec{data-element=Value, init-value=0}, required-interface=VeDMAB_y_StatusByte_IgnKeyOffTmrPerfTooFast
      VeDMAB_y_StatusByte_LosCommBECM_A: variation-point={short-label=vpVeDMAB_y_StatusByte_LosCommBECM_A, sw-syscond=1}, nonqueued-receiver-com-spec{data-element=Value, init-value=0}, required-interface=VeDMAB_y_StatusByte_LosCommBECM_A
      VeDMAB_y_StatusByte_LostCommBCM: variation-point={short-label=vpVeDMAB_y_StatusByte_LostCommBCM, sw-syscond=1}, nonqueued-receiver-com-spec{data-element=Value, init-value=0}, required-interface=VeDMAB_y_StatusByte_LostCommBCM
      VeDMAB_y_StatusByte_LostCommRadio: variation-point={short-label=vpVeDMAB_y_StatusByte_LostCommRadio, sw-syscond=1}, nonqueued-receiver-com-spec{data-element=Value, init-value=0}, required-interface=VeDMAB_y_StatusByte_LostCommRadio
      VeDMAB_y_StatusByte_LostCommTelematicCM: variation-point={short-label=vpVeDMAB_y_StatusByte_LostCommTelematicCM, sw-syscond=1}, nonqueued-receiver-com-spec{data-element=Value, init-value=0}, required-interface=VeDMAB_y_StatusByte_LostCommTelematicCM
    78 x provide port:
      VeSCPR_K_Sch1_Start_Time_Hr_Sts: nonqueued-sender-com-spec{data-element=Value, init-value=0}, provided-interface=VeSCPR_K_Sch1_Start_Time_Hr_Sts
      VeSCPR_K_Sch1_Start_Time_Min_Sts: nonqueued-sender-com-spec{data-element=Value, init-value=0}, provided-interface=VeSCPR_K_Sch1_Start_Time_Min_Sts
      VeSCPR_K_Sch1_End_Time_Hr_Sts: nonqueued-sender-com-spec{data-element=Value, init-value=0}, provided-interface=VeSCPR_K_Sch1_End_Time_Hr_Sts
      VeSCPR_K_Sch1_End_Time_Min_Sts: nonqueued-sender-com-spec{data-element=Value, init-value=0}, provided-interface=VeSCPR_K_Sch1_End_Time_Min_Sts
      VeSCPR_K_Sch1_Day_Sts: nonqueued-sender-com-spec{data-element=Value, init-value=0}, provided-interface=VeSCPR_K_Sch1_Day_Sts
      VeSCPR_b_Sch1_Confirmed: nonqueued-sender-com-spec{data-element=Value, init-value=0}, provided-interface=VeSCPR_b_Sch1_Confirmed
      VeSCPR_b_Sch1_ChargeUntilFull_Sts: nonqueued-sender-com-spec{data-element=Value, init-value=0}, provided-interface=VeSCPR_b_Sch1_ChargeUntilFull_Sts
      VeSCPR_K_Sch2_Start_Time_Hr_Sts: nonqueued-sender-com-spec{data-element=Value, init-value=0}, provided-interface=VeSCPR_K_Sch2_Start_Time_Hr_Sts
      VeSCPR_K_Sch2_Start_Time_Min_Sts: nonqueued-sender-com-spec{data-element=Value, init-value=0}, provided-interface=VeSCPR_K_Sch2_Start_Time_Min_Sts
      VeSCPR_K_Sch2_End_Time_Hr_Sts: nonqueued-sender-com-spec{data-element=Value, init-value=0}, provided-interface=VeSCPR_K_Sch2_End_Time_Hr_Sts
      VeSCPR_K_Sch2_End_Time_Min_Sts: nonqueued-sender-com-spec{data-element=Value, init-value=0}, provided-interface=VeSCPR_K_Sch2_End_Time_Min_Sts
      VeSCPR_K_Sch2_Day_Sts: nonqueued-sender-com-spec{data-element=Value, init-value=0}, provided-interface=VeSCPR_K_Sch2_Day_Sts
      VeSCPR_b_Sch2_Confirmed: nonqueued-sender-com-spec{data-element=Value, init-value=0}, provided-interface=VeSCPR_b_Sch2_Confirmed
      VeSCPR_b_Sch2_ChargeUntilFull_Sts: nonqueued-sender-com-spec{data-element=Value, init-value=0}, provided-interface=VeSCPR_b_Sch2_ChargeUntilFull_Sts
      VeSCPR_K_Sch3_DepHrSts: nonqueued-sender-com-spec{data-element=Value, init-value=0}, provided-interface=VeSCPR_K_Sch3_DepHrSts
      VeSCPR_K_Sch3_DepMinSts: nonqueued-sender-com-spec{data-element=Value, init-value=0}, provided-interface=VeSCPR_K_Sch3_DepMinSts
      VeSCPR_K_Sch3_DaySts: nonqueued-sender-com-spec{data-element=Value, init-value=0}, provided-interface=VeSCPR_K_Sch3_DaySts
      VeSCPR_b_Sch3_EnblSts: nonqueued-sender-com-spec{data-element=Value, init-value=0}, provided-interface=VeSCPR_b_Sch3_EnblSts
      VeSCPR_e_Sch3_AllowSts: nonqueued-sender-com-spec{data-element=Value, init-value=CeCITR_e_AnyTime}, provided-interface=VeSCPR_e_Sch3_AllowSts
      VeSCPR_T_Sch3_DepTempSts: nonqueued-sender-com-spec{data-element=Value, init-value=0}, provided-interface=VeSCPR_T_Sch3_DepTempSts
      VeSCPR_K_Sch4_DepHrSts: nonqueued-sender-com-spec{data-element=Value, init-value=0}, provided-interface=VeSCPR_K_Sch4_DepHrSts
      VeSCPR_K_Sch4_DepMinSts: nonqueued-sender-com-spec{data-element=Value, init-value=0}, provided-interface=VeSCPR_K_Sch4_DepMinSts
      VeSCPR_K_Sch4_DaySts: nonqueued-sender-com-spec{data-element=Value, init-value=0}, provided-interface=VeSCPR_K_Sch4_DaySts
      VeSCPR_b_Sch4_EnblSts: nonqueued-sender-com-spec{data-element=Value, init-value=0}, provided-interface=VeSCPR_b_Sch4_EnblSts
      VeSCPR_e_Sch4_AllowSts: nonqueued-sender-com-spec{data-element=Value, init-value=CeCITR_e_AnyTime}, provided-interface=VeSCPR_e_Sch4_AllowSts
      VeSCPR_T_Sch4_DepTempSts: nonqueued-sender-com-spec{data-element=Value, init-value=0}, provided-interface=VeSCPR_T_Sch4_DepTempSts
      VeSCPR_T_CabinTempSetPt: nonqueued-sender-com-spec{data-element=Value, init-value=0}, provided-interface=VeSCPR_T_CabinTempSetPt
      VeSCPR_K_Next_Climate_Time_Hr: nonqueued-sender-com-spec{data-element=Value, init-value=0}, provided-interface=VeSCPR_K_Next_Climate_Time_Hr
      VeSCPR_K_Next_Climate_Time_Min: nonqueued-sender-com-spec{data-element=Value, init-value=0}, provided-interface=VeSCPR_K_Next_Climate_Time_Min
      VeSCPR_K_Next_Climate_Day: nonqueued-sender-com-spec{data-element=Value, init-value=0}, provided-interface=VeSCPR_K_Next_Climate_Day
      VeSCPR_K_Next_SchStart_Time_Hr: nonqueued-sender-com-spec{data-element=Value, init-value=0}, provided-interface=VeSCPR_K_Next_SchStart_Time_Hr
      VeSCPR_K_Next_SchStart_Time_Min: nonqueued-sender-com-spec{data-element=Value, init-value=0}, provided-interface=VeSCPR_K_Next_SchStart_Time_Min
      VeSCPR_K_Next_SchEnd_Time_Hr: nonqueued-sender-com-spec{data-element=Value, init-value=0}, provided-interface=VeSCPR_K_Next_SchEnd_Time_Hr
      VeSCPR_K_Next_SchEnd_Time_Min: nonqueued-sender-com-spec{data-element=Value, init-value=0}, provided-interface=VeSCPR_K_Next_SchEnd_Time_Min
      VeSCPR_K_Next_Schedule_StartDay: nonqueued-sender-com-spec{data-element=Value, init-value=0}, provided-interface=VeSCPR_K_Next_Schedule_StartDay
      VeSCPR_K_Next_Schedule_EndDay: nonqueued-sender-com-spec{data-element=Value, init-value=0}, provided-interface=VeSCPR_K_Next_Schedule_EndDay
      VeSCPR_K_Ext_Next_StopTime_Day: nonqueued-sender-com-spec{data-element=Value, init-value=0}, provided-interface=VeSCPR_K_Ext_Next_StopTime_Day
      VeSCPR_K_Ext_Next_StopTime_Hr: nonqueued-sender-com-spec{data-element=Value, init-value=0}, provided-interface=VeSCPR_K_Ext_Next_StopTime_Hr
      VeSCPR_K_Ext_Next_StopTime_Min: nonqueued-sender-com-spec{data-element=Value, init-value=0}, provided-interface=VeSCPR_K_Ext_Next_StopTime_Min
      VeSCPR_Pct_Ext_Next_ImmedSOC_Trgt: nonqueued-sender-com-spec{data-element=Value, init-value=0}, provided-interface=VeSCPR_Pct_Ext_Next_ImmedSOC_Trgt
      VeSCPR_Pct_Ext_Next_ExtSOC_Trgt: nonqueued-sender-com-spec{data-element=Value, init-value=0}, provided-interface=VeSCPR_Pct_Ext_Next_ExtSOC_Trgt
      VeSCPR_Pct_Sch1_ImmedSOC_Trgt_Sts: nonqueued-sender-com-spec{data-element=Value, init-value=0}, provided-interface=VeSCPR_Pct_Sch1_ImmedSOC_Trgt_Sts
      VeSCPR_Pct_Sch1_ExtSOC_Trgt_Sts: nonqueued-sender-com-spec{data-element=Value, init-value=0}, provided-interface=VeSCPR_Pct_Sch1_ExtSOC_Trgt_Sts
      VeSCPR_e_Sch1_ChrgSchType_Sts: nonqueued-sender-com-spec{data-element=Value, init-value=CeCITR_e_No_Selection}, provided-interface=VeSCPR_e_Sch1_ChrgSchType_Sts
      VeSCPR_Pct_Sch2_ImmedSOC_Trgt_Sts: nonqueued-sender-com-spec{data-element=Value, init-value=0}, provided-interface=VeSCPR_Pct_Sch2_ImmedSOC_Trgt_Sts
      VeSCPR_Pct_Sch2_ExtSOC_Trgt_Sts: nonqueued-sender-com-spec{data-element=Value, init-value=0}, provided-interface=VeSCPR_Pct_Sch2_ExtSOC_Trgt_Sts
      VeSCPR_e_Sch2_ChrgSchType_Sts: nonqueued-sender-com-spec{data-element=Value, init-value=CeCITR_e_No_Selection}, provided-interface=VeSCPR_e_Sch2_ChrgSchType_Sts
      VeSCPR_e_CoopChrgStatus: nonqueued-sender-com-spec{data-element=Value, init-value=CeSCPR_e_DefaultSts}, provided-interface=VeSCPR_e_CoopChrgStatus
      VeSCPR_e_Next_ChrgSchType: nonqueued-sender-com-spec{data-element=Value, init-value=CeSCPR_e_No_Selection}, provided-interface=VeSCPR_e_Next_ChrgSchType
      VeSCPR_t_TimeToDeparture: nonqueued-sender-com-spec{data-element=Value, init-value=0}, provided-interface=VeSCPR_t_TimeToDeparture
      VeSCPR_e_SchCP_Allow: nonqueued-sender-com-spec{data-element=Value, init-value=CeCITR_e_AnyTime}, provided-interface=VeSCPR_e_SchCP_Allow
      VeSCPR_t_SchChrg_WUTime: nonqueued-sender-com-spec{data-element=Value, init-value=0}, provided-interface=VeSCPR_t_SchChrg_WUTime
      VeSCPR_b_ChargeReq: nonqueued-sender-com-spec{data-element=Value, init-value=0}, provided-interface=VeSCPR_b_ChargeReq
      VeSCPR_e_CPIM_Icon1_Cmd: nonqueued-sender-com-spec{data-element=Value, init-value=CeCITR_e_CPIM_Icon_OFF}, provided-interface=VeSCPR_e_CPIM_Icon1_Cmd
      VeSCPR_e_CPIM_Icon2_Cmd: nonqueued-sender-com-spec{data-element=Value, init-value=CeCITR_e_CPIM_Icon_OFF}, provided-interface=VeSCPR_e_CPIM_Icon2_Cmd
      VeSCPR_Pct_Est_SOC: nonqueued-sender-com-spec{data-element=Value, init-value=0}, provided-interface=VeSCPR_Pct_Est_SOC
      VeSCPR_b_NoChrgSchEnbl: nonqueued-sender-com-spec{data-element=Value, init-value=0}, provided-interface=VeSCPR_b_NoChrgSchEnbl
      VeSCPR_b_ButtonActive_Door: nonqueued-sender-com-spec{data-element=Value, init-value=0}, provided-interface=VeSCPR_b_ButtonActive_Door
      VeSCPR_b_Sch1_Batt_CabinPriority_Sts: nonqueued-sender-com-spec{data-element=Value, init-value=0}, provided-interface=VeSCPR_b_Sch1_Batt_CabinPriority_Sts
      VeSCPR_b_Sch1_Do_Not_Repeat_Sts: nonqueued-sender-com-spec{data-element=Value, init-value=0}, provided-interface=VeSCPR_b_Sch1_Do_Not_Repeat_Sts
      VeSCPR_e_Sch1_Type_Sts: nonqueued-sender-com-spec{data-element=Value, init-value=CeCITR_e_SchType_NoSelection}, provided-interface=VeSCPR_e_Sch1_Type_Sts
      VeSCPR_b_Sch2_Batt_CabinPriority_Sts: nonqueued-sender-com-spec{data-element=Value, init-value=0}, provided-interface=VeSCPR_b_Sch2_Batt_CabinPriority_Sts
      VeSCPR_b_Sch2_Do_Not_Repeat_Sts: nonqueued-sender-com-spec{data-element=Value, init-value=0}, provided-interface=VeSCPR_b_Sch2_Do_Not_Repeat_Sts
      VeSCPR_e_Sch2_Type_Sts: nonqueued-sender-com-spec{data-element=Value, init-value=CeCITR_e_SchType_NoSelection}, provided-interface=VeSCPR_e_Sch2_Type_Sts
      VeSCPR_b_Sch3_Batt_CabinPriority_Sts: nonqueued-sender-com-spec{data-element=Value, init-value=0}, provided-interface=VeSCPR_b_Sch3_Batt_CabinPriority_Sts
      VeSCPR_b_Sch3_ChargeUntilFull_Sts: nonqueued-sender-com-spec{data-element=Value, init-value=0}, provided-interface=VeSCPR_b_Sch3_ChargeUntilFull_Sts
      VeSCPR_b_Sch3_Do_Not_Repeat_Sts: nonqueued-sender-com-spec{data-element=Value, init-value=0}, provided-interface=VeSCPR_b_Sch3_Do_Not_Repeat_Sts
      VeSCPR_K_Sch3_End_Time_Hr_Sts: nonqueued-sender-com-spec{data-element=Value, init-value=0}, provided-interface=VeSCPR_K_Sch3_End_Time_Hr_Sts
      VeSCPR_K_Sch3_End_Time_Min_Sts: nonqueued-sender-com-spec{data-element=Value, init-value=0}, provided-interface=VeSCPR_K_Sch3_End_Time_Min_Sts
      VeSCPR_b_Sch3_Confirmed: nonqueued-sender-com-spec{data-element=Value, init-value=0}, provided-interface=VeSCPR_b_Sch3_Confirmed
      VeSCPR_K_Sch3_Day_Sts: nonqueued-sender-com-spec{data-element=Value, init-value=0}, provided-interface=VeSCPR_K_Sch3_Day_Sts
      VeSCPR_e_Sch3_Type_Sts: nonqueued-sender-com-spec{data-element=Value, init-value=CeCITR_e_SchType_NoSelection}, provided-interface=VeSCPR_e_Sch3_Type_Sts
      VeSCPR_K_Sch3_Start_Time_Hr_Sts: nonqueued-sender-com-spec{data-element=Value, init-value=0}, provided-interface=VeSCPR_K_Sch3_Start_Time_Hr_Sts
      VeSCPR_K_Sch3_Start_Time_Min_Sts: nonqueued-sender-com-spec{data-element=Value, init-value=0}, provided-interface=VeSCPR_K_Sch3_Start_Time_Min_Sts
      VeSCPR_b_BattCabinPriority: nonqueued-sender-com-spec{data-element=Value, init-value=0}, provided-interface=VeSCPR_b_BattCabinPriority
      VeSCPR_b_SchChrg_OktoCharge: nonqueued-sender-com-spec{data-element=Value, init-value=0}, provided-interface=VeSCPR_b_SchChrg_OktoCharge
      VeSCPR_e_InitStatus: nonqueued-sender-com-spec{data-element=Value, init-value=CeSCPR_e_InitDefault}, provided-interface=VeSCPR_e_InitStatus
      VeSCPR_b_FOTASchCnflct: nonqueued-sender-com-spec{data-element=Value, init-value=0}, provided-interface=VeSCPR_b_FOTASchCnflct
    87 x require port:
      FeSCPR_y_Sch1CH_Day_Rx: variation-point={short-label=vpFeSCPR_y_Sch1CH_Day_Rx, sw-syscond=1}, nv-require-com-spec{init-value=0, variable=FeSCPR_y_Sch1CH_Day}, required-interface=FeSCPR_y_Sch1CH_Day
      FeSCPR_b_Sch1CP_DNR_Rx: variation-point={short-label=vpFeSCPR_b_Sch1CP_DNR_Rx, sw-syscond=1}, nv-require-com-spec{init-value=0, variable=FeSCPR_b_Sch1CP_DNR}, required-interface=FeSCPR_b_Sch1CP_DNR
      FeSCPR_y_Sch1CP_Day_Rx: variation-point={short-label=vpFeSCPR_y_Sch1CP_Day_Rx, sw-syscond=1}, nv-require-com-spec{init-value=0, variable=FeSCPR_y_Sch1CP_Day}, required-interface=FeSCPR_y_Sch1CP_Day
      FeSCPR_y_Sch2CH_Day_Rx: variation-point={short-label=vpFeSCPR_y_Sch2CH_Day_Rx, sw-syscond=1}, nv-require-com-spec{init-value=0, variable=FeSCPR_y_Sch2CH_Day}, required-interface=FeSCPR_y_Sch2CH_Day
      FeSCPR_b_Sch2CH_Enbl_Rx: variation-point={short-label=vpFeSCPR_b_Sch2CH_Enbl_Rx, sw-syscond=1}, nv-require-com-spec{init-value=0, variable=FeSCPR_b_Sch2CH_Enbl}, required-interface=FeSCPR_b_Sch2CH_Enbl
      FeSCPR_b_Sch2CH_ChrgUntFl_Rx: variation-point={short-label=vpFeSCPR_b_Sch2CH_ChrgUntFl_Rx, sw-syscond=1}, nv-require-com-spec{init-value=0, variable=FeSCPR_b_Sch2CH_ChrgUntFl}, required-interface=FeSCPR_b_Sch2CH_ChrgUntFl
      FeSCPR_b_Sch2CH_DNR_Rx: variation-point={short-label=vpFeSCPR_b_Sch2CH_DNR_Rx, sw-syscond=1}, nv-require-com-spec{init-value=0, variable=FeSCPR_b_Sch2CH_DNR}, required-interface=FeSCPR_b_Sch2CH_DNR
      FeSCPR_e_Sch2CH_StrtHr_Rx: variation-point={short-label=vpFeSCPR_e_Sch2CH_StrtHr_Rx, sw-syscond=1}, nv-require-com-spec{init-value=0, variable=FeSCPR_e_Sch2CH_StrtHr}, required-interface=FeSCPR_e_Sch2CH_StrtHr
      FeSCPR_e_Sch2CH_StrtMin_Rx: variation-point={short-label=vpFeSCPR_e_Sch2CH_StrtMin_Rx, sw-syscond=1}, nv-require-com-spec{init-value=0, variable=FeSCPR_e_Sch2CH_StrtMin}, required-interface=FeSCPR_e_Sch2CH_StrtMin
      FeSCPR_e_Sch2CH_EndHr_Rx: variation-point={short-label=vpFeSCPR_e_Sch2CH_EndHr_Rx, sw-syscond=1}, nv-require-com-spec{init-value=0, variable=FeSCPR_e_Sch2CH_EndHr}, required-interface=FeSCPR_e_Sch2CH_EndHr
      FeSCPR_e_Sch2CH_EndMin_Rx: variation-point={short-label=vpFeSCPR_e_Sch2CH_EndMin_Rx, sw-syscond=1}, nv-require-com-spec{init-value=0, variable=FeSCPR_e_Sch2CH_EndMin}, required-interface=FeSCPR_e_Sch2CH_EndMin
      FeSCPR_b_Sch1CH_Enbl_Rx: variation-point={short-label=vpFeSCPR_b_Sch1CH_Enbl_Rx, sw-syscond=1}, nv-require-com-spec{init-value=0, variable=FeSCPR_b_Sch1CH_Enbl}, required-interface=FeSCPR_b_Sch1CH_Enbl
      FeSCPR_b_Sch2CP_Enbl_Rx: variation-point={short-label=vpFeSCPR_b_Sch2CP_Enbl_Rx, sw-syscond=1}, nv-require-com-spec{init-value=0, variable=FeSCPR_b_Sch2CP_Enbl}, required-interface=FeSCPR_b_Sch2CP_Enbl
      FeSCPR_T_Sch2CP_DepTemp_Rx: variation-point={short-label=vpFeSCPR_T_Sch2CP_DepTemp_Rx, sw-syscond=1}, nv-require-com-spec{init-value=-8888888, variable=FeSCPR_T_Sch2CP_DepTemp}, required-interface=FeSCPR_T_Sch2CP_DepTemp
      FeSCPR_e_Sch2CP_Allow_Rx: variation-point={short-label=vpFeSCPR_e_Sch2CP_Allow_Rx, sw-syscond=1}, nv-require-com-spec{init-value=CeCITR_e_AnyTime, variable=FeSCPR_e_Sch2CP_Allow}, required-interface=FeSCPR_e_Sch2CP_Allow
      FeSCPR_e_Sch2CP_DepHr_Rx: variation-point={short-label=vpFeSCPR_e_Sch2CP_DepHr_Rx, sw-syscond=1}, nv-require-com-spec{init-value=0, variable=FeSCPR_e_Sch2CP_DepHr}, required-interface=FeSCPR_e_Sch2CP_DepHr
      FeSCPR_e_Sch2CP_DepMin_Rx: variation-point={short-label=vpFeSCPR_e_Sch2CP_DepMin_Rx, sw-syscond=1}, nv-require-com-spec{init-value=0, variable=FeSCPR_e_Sch2CP_DepMin}, required-interface=FeSCPR_e_Sch2CP_DepMin
      FeSCPR_b_Sch2CP_DNR_Rx: variation-point={short-label=vpFeSCPR_b_Sch2CP_DNR_Rx, sw-syscond=1}, nv-require-com-spec{init-value=0, variable=FeSCPR_b_Sch2CP_DNR}, required-interface=FeSCPR_b_Sch2CP_DNR
      FeSCPR_y_Sch2CP_Day_Rx: variation-point={short-label=vpFeSCPR_y_Sch2CP_Day_Rx, sw-syscond=1}, nv-require-com-spec{init-value=0, variable=FeSCPR_y_Sch2CP_Day}, required-interface=FeSCPR_y_Sch2CP_Day
      FeSCPR_e_Sch1CH_StrtHr_Rx: variation-point={short-label=vpFeSCPR_e_Sch1CH_StrtHr_Rx, sw-syscond=1}, nv-require-com-spec{init-value=0, variable=FeSCPR_e_Sch1CH_StrtHr}, required-interface=FeSCPR_e_Sch1CH_StrtHr
      FeSCPR_e_Sch1CH_StrtMin_Rx: variation-point={short-label=vpFeSCPR_e_Sch1CH_StrtMin_Rx, sw-syscond=1}, nv-require-com-spec{init-value=0, variable=FeSCPR_e_Sch1CH_StrtMin}, required-interface=FeSCPR_e_Sch1CH_StrtMin
      FeSCPR_e_Sch1CH_EndHr_Rx: variation-point={short-label=vpFeSCPR_e_Sch1CH_EndHr_Rx, sw-syscond=1}, nv-require-com-spec{init-value=0, variable=FeSCPR_e_Sch1CH_EndHr}, required-interface=FeSCPR_e_Sch1CH_EndHr
      FeSCPR_b_Sch1CH_ChrgUntFl_Rx: variation-point={short-label=vpFeSCPR_b_Sch1CH_ChrgUntFl_Rx, sw-syscond=1}, nv-require-com-spec{init-value=0, variable=FeSCPR_b_Sch1CH_ChrgUntFl}, required-interface=FeSCPR_b_Sch1CH_ChrgUntFl
      FeSCPR_e_Sch1CH_EndMin_Rx: variation-point={short-label=vpFeSCPR_e_Sch1CH_EndMin_Rx, sw-syscond=1}, nv-require-com-spec{init-value=0, variable=FeSCPR_e_Sch1CH_EndMin}, required-interface=FeSCPR_e_Sch1CH_EndMin
      NeSCPR_e_NxtSchCP_StrtMin_Rx: variation-point={short-label=vpNeSCPR_e_NxtSchCP_StrtMin_Rx, sw-syscond=1}, nv-require-com-spec{init-value=0, variable=NeSCPR_e_NxtSchCP_StrtMin}, required-interface=NeSCPR_e_NxtSchCP_StrtMin
      NeSCPR_k_CabinTempSetPoint_Rx: variation-point={short-label=vpNeSCPR_k_CabinTempSetPoint_Rx, sw-syscond=1}, nv-require-com-spec{init-value=0, variable=NeSCPR_k_CabinTempSetPoint}, required-interface=NeSCPR_k_CabinTempSetPoint
      NeSCPR_e_NxtSchCP_Day_Rx: variation-point={short-label=vpNeSCPR_e_NxtSchCP_Day_Rx, sw-syscond=1}, nv-require-com-spec{init-value=0, variable=NeSCPR_e_NxtSchCP_Day}, required-interface=NeSCPR_e_NxtSchCP_Day
      NeSCPR_e_NxtSchCP_StrtHr_Rx: variation-point={short-label=vpNeSCPR_e_NxtSchCP_StrtHr_Rx, sw-syscond=1}, nv-require-com-spec{init-value=0, variable=NeSCPR_e_NxtSchCP_StrtHr}, required-interface=NeSCPR_e_NxtSchCP_StrtHr
      NeSCPR_e_NxtSchCH_StrtHr_Rx: variation-point={short-label=vpNeSCPR_e_NxtSchCH_StrtHr_Rx, sw-syscond=1}, nv-require-com-spec{init-value=0, variable=NeSCPR_e_NxtSchCH_StrtHr}, required-interface=NeSCPR_e_NxtSchCH_StrtHr
      NeSCPR_e_NxtSchCH_StrtMin_Rx: variation-point={short-label=vpNeSCPR_e_NxtSchCH_StrtMin_Rx, sw-syscond=1}, nv-require-com-spec{init-value=0, variable=NeSCPR_e_NxtSchCH_StrtMin}, required-interface=NeSCPR_e_NxtSchCH_StrtMin
      NeSCPR_e_NxtSchCH_StrtDay_Rx: variation-point={short-label=vpNeSCPR_e_NxtSchCH_StrtDay_Rx, sw-syscond=1}, nv-require-com-spec{init-value=0, variable=NeSCPR_e_NxtSchCH_StrtDay}, required-interface=NeSCPR_e_NxtSchCH_StrtDay
      NeSCPR_e_NxtSchCH_EndHr_Rx: variation-point={short-label=vpNeSCPR_e_NxtSchCH_EndHr_Rx, sw-syscond=1}, nv-require-com-spec{init-value=0, variable=NeSCPR_e_NxtSchCH_EndHr}, required-interface=NeSCPR_e_NxtSchCH_EndHr
      NeSCPR_e_NxtSchCH_EndMin_Rx: variation-point={short-label=vpNeSCPR_e_NxtSchCH_EndMin_Rx, sw-syscond=1}, nv-require-com-spec{init-value=0, variable=NeSCPR_e_NxtSchCH_EndMin}, required-interface=NeSCPR_e_NxtSchCH_EndMin
      FeSCPR_b_Sch1CH_DNR_Rx: variation-point={short-label=vpFeSCPR_b_Sch1CH_DNR_Rx, sw-syscond=1}, nv-require-com-spec{init-value=0, variable=FeSCPR_b_Sch1CH_DNR}, required-interface=FeSCPR_b_Sch1CH_DNR
      NeSCPR_e_NxtSchCH_EndDay_Rx: variation-point={short-label=vpNeSCPR_e_NxtSchCH_EndDay_Rx, sw-syscond=1}, nv-require-com-spec{init-value=0, variable=NeSCPR_e_NxtSchCH_EndDay}, required-interface=NeSCPR_e_NxtSchCH_EndDay
      FeSCPR_b_Sch1CP_Enbl_Rx: variation-point={short-label=vpFeSCPR_b_Sch1CP_Enbl_Rx, sw-syscond=1}, nv-require-com-spec{init-value=0, variable=FeSCPR_b_Sch1CP_Enbl}, required-interface=FeSCPR_b_Sch1CP_Enbl
      FeSCPR_T_Sch1CP_DepTemp_Rx: variation-point={short-label=vpFeSCPR_T_Sch1CP_DepTemp_Rx, sw-syscond=1}, nv-require-com-spec{init-value=-8888888, variable=FeSCPR_T_Sch1CP_DepTemp}, required-interface=FeSCPR_T_Sch1CP_DepTemp
      FeSCPR_e_Sch1CP_Allow_Rx: variation-point={short-label=vpFeSCPR_e_Sch1CP_Allow_Rx, sw-syscond=1}, nv-require-com-spec{init-value=CeCITR_e_AnyTime, variable=FeSCPR_e_Sch1CP_Allow}, required-interface=FeSCPR_e_Sch1CP_Allow
      FeSCPR_e_Sch1CP_DepHr_Rx: variation-point={short-label=vpFeSCPR_e_Sch1CP_DepHr_Rx, sw-syscond=1}, nv-require-com-spec{init-value=0, variable=FeSCPR_e_Sch1CP_DepHr}, required-interface=FeSCPR_e_Sch1CP_DepHr
      FeSCPR_e_Sch1CP_DepMin_Rx: variation-point={short-label=vpFeSCPR_e_Sch1CP_DepMin_Rx, sw-syscond=1}, nv-require-com-spec{init-value=0, variable=FeSCPR_e_Sch1CP_DepMin}, required-interface=FeSCPR_e_Sch1CP_DepMin
      FeSCPR_b_CancelActFOTA_Rx: variation-point={short-label=vpFeSCPR_b_CancelActFOTA_Rx, sw-syscond=1}, nv-require-com-spec{init-value=0, variable=FeSCPR_b_CancelActFOTA}, required-interface=FeSCPR_b_CancelActFOTA
      FeSCPR_b_ChrgNowLatch_Rx: variation-point={short-label=vpFeSCPR_b_ChrgNowLatch_Rx, sw-syscond=1}, nv-require-com-spec{init-value=0, variable=FeSCPR_b_ChrgNowLatch}, required-interface=FeSCPR_b_ChrgNowLatch
      FeSCPR_b_FOTA_Conflict_Rx: variation-point={short-label=vpFeSCPR_b_FOTA_Conflict_Rx, sw-syscond=1}, nv-require-com-spec{init-value=0, variable=FeSCPR_b_FOTA_Conflict}, required-interface=FeSCPR_b_FOTA_Conflict
      FeSCPR_e_FOTA_Install_Type_Rx: variation-point={short-label=vpFeSCPR_e_FOTA_Install_Type_Rx, sw-syscond=1}, nv-require-com-spec{init-value=CeCITR_e_NoFOTA, variable=FeSCPR_e_FOTA_Install_Type}, required-interface=FeSCPR_e_FOTA_Install_Type
      FeSCPR_g_ChrgNowMaxTimetoPlugin_Rx: variation-point={short-label=vpFeSCPR_g_ChrgNowMaxTimetoPlugin_Rx, sw-syscond=1}, nv-require-com-spec{init-value=0, variable=FeSCPR_g_ChrgNowMaxTimetoPlugin}, required-interface=FeSCPR_g_ChrgNowMaxTimetoPlugin
      NeSCPR_Pct_SOCArb_Rx: variation-point={short-label=vpNeSCPR_Pct_SOCArb_Rx, sw-syscond=1}, nv-require-com-spec{init-value=0, variable=NeSCPR_Pct_SOCArb}, required-interface=NeSCPR_Pct_SOCArb
      NeSCPR_b_AllowCancel_Rx: variation-point={short-label=vpNeSCPR_b_AllowCancel_Rx, sw-syscond=1}, nv-require-com-spec{init-value=0, variable=NeSCPR_b_AllowCancel}, required-interface=NeSCPR_b_AllowCancel
      NeSCPR_b_CancSchedIsUF_Rx: variation-point={short-label=vpNeSCPR_b_CancSchedIsUF_Rx, sw-syscond=1}, nv-require-com-spec{init-value=0, variable=NeSCPR_b_CancSchedIsUF}, required-interface=NeSCPR_b_CancSchedIsUF
      NeSCPR_b_CancWindow_Rx: variation-point={short-label=vpNeSCPR_b_CancWindow_Rx, sw-syscond=1}, nv-require-com-spec{init-value=0, variable=NeSCPR_b_CancWindow}, required-interface=NeSCPR_b_CancWindow
      NeSCPR_b_ChrgComplete_Rx: variation-point={short-label=vpNeSCPR_b_ChrgComplete_Rx, sw-syscond=1}, nv-require-com-spec{init-value=0, variable=NeSCPR_b_ChrgComplete}, required-interface=NeSCPR_b_ChrgComplete
      NeSCPR_b_PluginLatchOverride_Rx: variation-point={short-label=vpNeSCPR_b_PluginLatchOverride_Rx, sw-syscond=1}, nv-require-com-spec{init-value=0, variable=NeSCPR_b_PluginLatchOverride}, required-interface=NeSCPR_b_PluginLatchOverride
      NeSCPR_b_RadioRqLstVldStt_Rx: variation-point={short-label=vpNeSCPR_b_RadioRqLstVldStt_Rx, sw-syscond=1}, nv-require-com-spec{init-value=0, variable=NeSCPR_b_RadioRqLstVldStt}, required-interface=NeSCPR_b_RadioRqLstVldStt
      NeSCPR_b_StopChrg_Rx: variation-point={short-label=vpNeSCPR_b_StopChrg_Rx, sw-syscond=1}, nv-require-com-spec{init-value=0, variable=NeSCPR_b_StopChrg}, required-interface=NeSCPR_b_StopChrg
      NeSCPR_b_xMinUF_Rx: variation-point={short-label=vpNeSCPR_b_xMinUF_Rx, sw-syscond=1}, nv-require-com-spec{init-value=0, variable=NeSCPR_b_xMinUF}, required-interface=NeSCPR_b_xMinUF
      NeSCPR_b_xMinUFCancel_Rx: variation-point={short-label=vpNeSCPR_b_xMinUFCancel_Rx, sw-syscond=1}, nv-require-com-spec{init-value=0, variable=NeSCPR_b_xMinUFCancel}, required-interface=NeSCPR_b_xMinUFCancel
      NeSCPR_e_CancStartIdxHold_Rx: variation-point={short-label=vpNeSCPR_e_CancStartIdxHold_Rx, sw-syscond=1}, nv-require-com-spec{init-value=0, variable=NeSCPR_e_CancStartIdxHold}, required-interface=NeSCPR_e_CancStartIdxHold
      NeSCPR_e_CancelStartIndx_Rx: variation-point={short-label=vpNeSCPR_e_CancelStartIndx_Rx, sw-syscond=1}, nv-require-com-spec{init-value=0, variable=NeSCPR_e_CancelStartIndx}, required-interface=NeSCPR_e_CancelStartIndx
      NeSCPR_e_EndIndexCanc_Rx: variation-point={short-label=vpNeSCPR_e_EndIndexCanc_Rx, sw-syscond=1}, nv-require-com-spec{init-value=0, variable=NeSCPR_e_EndIndexCanc}, required-interface=NeSCPR_e_EndIndexCanc
      NeSCPR_e_LastNowIndex_Rx: variation-point={short-label=vpNeSCPR_e_LastNowIndex_Rx, sw-syscond=1}, nv-require-com-spec{init-value=0, variable=NeSCPR_e_LastNowIndex}, required-interface=NeSCPR_e_LastNowIndex
      NeSCPR_g_DoNotRepeatValSch1_Rx: variation-point={short-label=vpNeSCPR_g_DoNotRepeatValSch1_Rx, sw-syscond=1}, nv-require-com-spec{init-value=0, variable=NeSCPR_g_DoNotRepeatValSch1}, required-interface=NeSCPR_g_DoNotRepeatValSch1
      NeSCPR_g_DoNotRepeatValSch2_Rx: variation-point={short-label=vpNeSCPR_g_DoNotRepeatValSch2_Rx, sw-syscond=1}, nv-require-com-spec{init-value=0, variable=NeSCPR_g_DoNotRepeatValSch2}, required-interface=NeSCPR_g_DoNotRepeatValSch2
      NeSCPR_g_Sch1CP_DNRvalue_Rx: variation-point={short-label=vpNeSCPR_g_Sch1CP_DNRvalue_Rx, sw-syscond=1}, nv-require-com-spec{init-value=0, variable=NeSCPR_g_Sch1CP_DNRvalue}, required-interface=NeSCPR_g_Sch1CP_DNRvalue
      NeSCPR_g_Sch2CP_DNRvalue_Rx: variation-point={short-label=vpNeSCPR_g_Sch2CP_DNRvalue_Rx, sw-syscond=1}, nv-require-com-spec{init-value=0, variable=NeSCPR_g_Sch2CP_DNRvalue}, required-interface=NeSCPR_g_Sch2CP_DNRvalue
      NeSCPR_k_CancGlEndTrack_Rx: variation-point={short-label=vpNeSCPR_k_CancGlEndTrack_Rx, sw-syscond=1}, nv-require-com-spec{init-value=0, variable=NeSCPR_k_CancGlEndTrack}, required-interface=NeSCPR_k_CancGlEndTrack
      NeSCPR_k_CancGlStartTrack_Rx: variation-point={short-label=vpNeSCPR_k_CancGlStartTrack_Rx, sw-syscond=1}, nv-require-com-spec{init-value=0, variable=NeSCPR_k_CancGlStartTrack}, required-interface=NeSCPR_k_CancGlStartTrack
      NeSCPR_k_CancOverlapTrack_Rx: variation-point={short-label=vpNeSCPR_k_CancOverlapTrack_Rx, sw-syscond=1}, nv-require-com-spec{init-value=0, variable=NeSCPR_k_CancOverlapTrack}, required-interface=NeSCPR_k_CancOverlapTrack
      NeSCPR_k_LastRTC_Rx: variation-point={short-label=vpNeSCPR_k_LastRTC_Rx, sw-syscond=1}, nv-require-com-spec{init-value=0, variable=NeSCPR_k_LastRTC}, required-interface=NeSCPR_k_LastRTC
      NeSCPR_k_LastSecond_Rx: variation-point={short-label=vpNeSCPR_k_LastSecond_Rx, sw-syscond=1}, nv-require-com-spec{init-value=0, variable=NeSCPR_k_LastSecond}, required-interface=NeSCPR_k_LastSecond
      NeSCPR_e_Sch1CoCH_StopHr_Rx: variation-point={short-label=vpNeSCPR_e_Sch1CoCH_StopHr_Rx, sw-syscond=1}, nv-require-com-spec{init-value=0, variable=NeSCPR_e_Sch1CoCH_StopHr}, required-interface=NeSCPR_e_Sch1CoCH_StopHr
      NeSCPR_e_Sch1CoCH_StopMin_Rx: variation-point={short-label=vpNeSCPR_e_Sch1CoCH_StopMin_Rx, sw-syscond=1}, nv-require-com-spec{init-value=0, variable=NeSCPR_e_Sch1CoCH_StopMin}, required-interface=NeSCPR_e_Sch1CoCH_StopMin
      NeSCPR_y_Sch1CoCH_Day_Rx: variation-point={short-label=vpNeSCPR_y_Sch1CoCH_Day_Rx, sw-syscond=1}, nv-require-com-spec{init-value=0, variable=NeSCPR_y_Sch1CoCH_Day}, required-interface=NeSCPR_y_Sch1CoCH_Day
      NeSCPR_b_Sch1CoCH_Enbl_Rx: variation-point={short-label=vpNeSCPR_b_Sch1CoCH_Enbl_Rx, sw-syscond=1}, nv-require-com-spec{init-value=0, variable=NeSCPR_b_Sch1CoCH_Enbl}, required-interface=NeSCPR_b_Sch1CoCH_Enbl
      NeSCPR_Pct_Sch1CoCH_ImmSOCtrgt_Rx: variation-point={short-label=vpNeSCPR_Pct_Sch1CoCH_ImmSOCtrgt_Rx, sw-syscond=1}, nv-require-com-spec{init-value=0, variable=NeSCPR_Pct_Sch1CoCH_ImmSOCtrgt}, required-interface=NeSCPR_Pct_Sch1CoCH_ImmSOCtrgt
      NeSCPR_Pct_Sch1CoCH_ExtSOCtrgt_Rx: variation-point={short-label=vpNeSCPR_Pct_Sch1CoCH_ExtSOCtrgt_Rx, sw-syscond=1}, nv-require-com-spec{init-value=0, variable=NeSCPR_Pct_Sch1CoCH_ExtSOCtrgt}, required-interface=NeSCPR_Pct_Sch1CoCH_ExtSOCtrgt
      NeSCPR_e_Sch1CH_SchType_Rx: variation-point={short-label=vpNeSCPR_e_Sch1CH_SchType_Rx, sw-syscond=1}, nv-require-com-spec{init-value=CeCITR_e_No_Selection, variable=NeSCPR_e_Sch1CH_SchType}, required-interface=NeSCPR_e_Sch1CH_SchType
      NeSCPR_e_Sch2CoCH_StopHr_Rx: variation-point={short-label=vpNeSCPR_e_Sch2CoCH_StopHr_Rx, sw-syscond=1}, nv-require-com-spec{init-value=0, variable=NeSCPR_e_Sch2CoCH_StopHr}, required-interface=NeSCPR_e_Sch2CoCH_StopHr
      NeSCPR_e_Sch2CoCH_StopMin_Rx: variation-point={short-label=vpNeSCPR_e_Sch2CoCH_StopMin_Rx, sw-syscond=1}, nv-require-com-spec{init-value=0, variable=NeSCPR_e_Sch2CoCH_StopMin}, required-interface=NeSCPR_e_Sch2CoCH_StopMin
      NeSCPR_y_Sch2CoCH_Day_Rx: variation-point={short-label=vpNeSCPR_y_Sch2CoCH_Day_Rx, sw-syscond=1}, nv-require-com-spec{init-value=0, variable=NeSCPR_y_Sch2CoCH_Day}, required-interface=NeSCPR_y_Sch2CoCH_Day
      NeSCPR_b_Sch2CoCH_Enbl_Rx: variation-point={short-label=vpNeSCPR_b_Sch2CoCH_Enbl_Rx, sw-syscond=1}, nv-require-com-spec{init-value=0, variable=NeSCPR_b_Sch2CoCH_Enbl}, required-interface=NeSCPR_b_Sch2CoCH_Enbl
      NeSCPR_Pct_Sch2CoCH_ImmSOCtrgt_Rx: variation-point={short-label=vpNeSCPR_Pct_Sch2CoCH_ImmSOCtrgt_Rx, sw-syscond=1}, nv-require-com-spec{init-value=0, variable=NeSCPR_Pct_Sch2CoCH_ImmSOCtrgt}, required-interface=NeSCPR_Pct_Sch2CoCH_ImmSOCtrgt
      NeSCPR_Pct_Sch2CoCH_ExtSOCtrgt_Rx: variation-point={short-label=vpNeSCPR_Pct_Sch2CoCH_ExtSOCtrgt_Rx, sw-syscond=1}, nv-require-com-spec{init-value=0, variable=NeSCPR_Pct_Sch2CoCH_ExtSOCtrgt}, required-interface=NeSCPR_Pct_Sch2CoCH_ExtSOCtrgt
      NeSCPR_e_Sch2CH_SchType_Rx: variation-point={short-label=vpNeSCPR_e_Sch2CH_SchType_Rx, sw-syscond=1}, nv-require-com-spec{init-value=CeCITR_e_No_Selection, variable=NeSCPR_e_Sch2CH_SchType}, required-interface=NeSCPR_e_Sch2CH_SchType
      NeSCPR_b_CoCh_VehLocation_Rx: variation-point={short-label=vpNeSCPR_b_CoCh_VehLocation_Rx, sw-syscond=1}, nv-require-com-spec{init-value=0, variable=NeSCPR_b_CoCh_VehLocation}, required-interface=NeSCPR_b_CoCh_VehLocation
      NeSCPR_b_CoCH_Sch1_DNR_Rx: variation-point={short-label=vpNeSCPR_b_CoCH_Sch1_DNR_Rx, sw-syscond=1}, nv-require-com-spec{init-value=0, variable=NeSCPR_b_CoCH_Sch1_DNR}, required-interface=NeSCPR_b_CoCH_Sch1_DNR
      NeSCPR_b_CoCH_Sch2_DNR_Rx: variation-point={short-label=vpNeSCPR_b_CoCH_Sch2_DNR_Rx, sw-syscond=1}, nv-require-com-spec{init-value=0, variable=NeSCPR_b_CoCH_Sch2_DNR}, required-interface=NeSCPR_b_CoCH_Sch2_DNR
      NeSCPR_g_Sch1CoCH_DNRvalue_Rx: variation-point={short-label=vpNeSCPR_g_Sch1CoCH_DNRvalue_Rx, sw-syscond=1}, nv-require-com-spec{init-value=0, variable=NeSCPR_g_Sch1CoCH_DNRvalue}, required-interface=NeSCPR_g_Sch1CoCH_DNRvalue
      NeSCPR_g_Sch2CoCH_DNRvalue_Rx: variation-point={short-label=vpNeSCPR_g_Sch2CoCH_DNRvalue_Rx, sw-syscond=1}, nv-require-com-spec{init-value=0, variable=NeSCPR_g_Sch2CoCH_DNRvalue}, required-interface=NeSCPR_g_Sch2CoCH_DNRvalue
    87 x provide port:
      FeSCPR_y_Sch1CH_Day: variation-point={short-label=vpFeSCPR_y_Sch1CH_Day, sw-syscond=1}, nv-provide-com-spec{ram-block-init-value=0, variable=FeSCPR_y_Sch1CH_Day}, provided-interface=FeSCPR_y_Sch1CH_Day
      FeSCPR_b_Sch1CP_DNR: variation-point={short-label=vpFeSCPR_b_Sch1CP_DNR, sw-syscond=1}, nv-provide-com-spec{ram-block-init-value=0, variable=FeSCPR_b_Sch1CP_DNR}, provided-interface=FeSCPR_b_Sch1CP_DNR
      FeSCPR_y_Sch1CP_Day: variation-point={short-label=vpFeSCPR_y_Sch1CP_Day, sw-syscond=1}, nv-provide-com-spec{ram-block-init-value=0, variable=FeSCPR_y_Sch1CP_Day}, provided-interface=FeSCPR_y_Sch1CP_Day
      FeSCPR_y_Sch2CH_Day: variation-point={short-label=vpFeSCPR_y_Sch2CH_Day, sw-syscond=1}, nv-provide-com-spec{ram-block-init-value=0, variable=FeSCPR_y_Sch2CH_Day}, provided-interface=FeSCPR_y_Sch2CH_Day
      FeSCPR_b_Sch2CH_Enbl: variation-point={short-label=vpFeSCPR_b_Sch2CH_Enbl, sw-syscond=1}, nv-provide-com-spec{ram-block-init-value=0, variable=FeSCPR_b_Sch2CH_Enbl}, provided-interface=FeSCPR_b_Sch2CH_Enbl
      FeSCPR_b_Sch2CH_ChrgUntFl: variation-point={short-label=vpFeSCPR_b_Sch2CH_ChrgUntFl, sw-syscond=1}, nv-provide-com-spec{ram-block-init-value=0, variable=FeSCPR_b_Sch2CH_ChrgUntFl}, provided-interface=FeSCPR_b_Sch2CH_ChrgUntFl
      FeSCPR_b_Sch2CH_DNR: variation-point={short-label=vpFeSCPR_b_Sch2CH_DNR, sw-syscond=1}, nv-provide-com-spec{ram-block-init-value=0, variable=FeSCPR_b_Sch2CH_DNR}, provided-interface=FeSCPR_b_Sch2CH_DNR
      FeSCPR_e_Sch2CH_StrtHr: variation-point={short-label=vpFeSCPR_e_Sch2CH_StrtHr, sw-syscond=1}, nv-provide-com-spec{ram-block-init-value=0, variable=FeSCPR_e_Sch2CH_StrtHr}, provided-interface=FeSCPR_e_Sch2CH_StrtHr
      FeSCPR_e_Sch2CH_StrtMin: variation-point={short-label=vpFeSCPR_e_Sch2CH_StrtMin, sw-syscond=1}, nv-provide-com-spec{ram-block-init-value=0, variable=FeSCPR_e_Sch2CH_StrtMin}, provided-interface=FeSCPR_e_Sch2CH_StrtMin
      FeSCPR_e_Sch2CH_EndHr: variation-point={short-label=vpFeSCPR_e_Sch2CH_EndHr, sw-syscond=1}, nv-provide-com-spec{ram-block-init-value=0, variable=FeSCPR_e_Sch2CH_EndHr}, provided-interface=FeSCPR_e_Sch2CH_EndHr
      FeSCPR_e_Sch2CH_EndMin: variation-point={short-label=vpFeSCPR_e_Sch2CH_EndMin, sw-syscond=1}, nv-provide-com-spec{ram-block-init-value=0, variable=FeSCPR_e_Sch2CH_EndMin}, provided-interface=FeSCPR_e_Sch2CH_EndMin
      FeSCPR_b_Sch1CH_Enbl: variation-point={short-label=vpFeSCPR_b_Sch1CH_Enbl, sw-syscond=1}, nv-provide-com-spec{ram-block-init-value=0, variable=FeSCPR_b_Sch1CH_Enbl}, provided-interface=FeSCPR_b_Sch1CH_Enbl
      FeSCPR_b_Sch2CP_Enbl: variation-point={short-label=vpFeSCPR_b_Sch2CP_Enbl, sw-syscond=1}, nv-provide-com-spec{ram-block-init-value=0, variable=FeSCPR_b_Sch2CP_Enbl}, provided-interface=FeSCPR_b_Sch2CP_Enbl
      FeSCPR_T_Sch2CP_DepTemp: variation-point={short-label=vpFeSCPR_T_Sch2CP_DepTemp, sw-syscond=1}, nv-provide-com-spec{ram-block-init-value=-8888888, variable=FeSCPR_T_Sch2CP_DepTemp}, provided-interface=FeSCPR_T_Sch2CP_DepTemp
      FeSCPR_e_Sch2CP_Allow: variation-point={short-label=vpFeSCPR_e_Sch2CP_Allow, sw-syscond=1}, nv-provide-com-spec{ram-block-init-value=CeCITR_e_AnyTime, variable=FeSCPR_e_Sch2CP_Allow}, provided-interface=FeSCPR_e_Sch2CP_Allow
      FeSCPR_e_Sch2CP_DepHr: variation-point={short-label=vpFeSCPR_e_Sch2CP_DepHr, sw-syscond=1}, nv-provide-com-spec{ram-block-init-value=0, variable=FeSCPR_e_Sch2CP_DepHr}, provided-interface=FeSCPR_e_Sch2CP_DepHr
      FeSCPR_e_Sch2CP_DepMin: variation-point={short-label=vpFeSCPR_e_Sch2CP_DepMin, sw-syscond=1}, nv-provide-com-spec{ram-block-init-value=0, variable=FeSCPR_e_Sch2CP_DepMin}, provided-interface=FeSCPR_e_Sch2CP_DepMin
      FeSCPR_b_Sch2CP_DNR: variation-point={short-label=vpFeSCPR_b_Sch2CP_DNR, sw-syscond=1}, nv-provide-com-spec{ram-block-init-value=0, variable=FeSCPR_b_Sch2CP_DNR}, provided-interface=FeSCPR_b_Sch2CP_DNR
      FeSCPR_y_Sch2CP_Day: variation-point={short-label=vpFeSCPR_y_Sch2CP_Day, sw-syscond=1}, nv-provide-com-spec{ram-block-init-value=0, variable=FeSCPR_y_Sch2CP_Day}, provided-interface=FeSCPR_y_Sch2CP_Day
      FeSCPR_e_Sch1CH_StrtHr: variation-point={short-label=vpFeSCPR_e_Sch1CH_StrtHr, sw-syscond=1}, nv-provide-com-spec{ram-block-init-value=0, variable=FeSCPR_e_Sch1CH_StrtHr}, provided-interface=FeSCPR_e_Sch1CH_StrtHr
      FeSCPR_e_Sch1CH_StrtMin: variation-point={short-label=vpFeSCPR_e_Sch1CH_StrtMin, sw-syscond=1}, nv-provide-com-spec{ram-block-init-value=0, variable=FeSCPR_e_Sch1CH_StrtMin}, provided-interface=FeSCPR_e_Sch1CH_StrtMin
      FeSCPR_e_Sch1CH_EndHr: variation-point={short-label=vpFeSCPR_e_Sch1CH_EndHr, sw-syscond=1}, nv-provide-com-spec{ram-block-init-value=0, variable=FeSCPR_e_Sch1CH_EndHr}, provided-interface=FeSCPR_e_Sch1CH_EndHr
      FeSCPR_b_Sch1CH_ChrgUntFl: variation-point={short-label=vpFeSCPR_b_Sch1CH_ChrgUntFl, sw-syscond=1}, nv-provide-com-spec{ram-block-init-value=0, variable=FeSCPR_b_Sch1CH_ChrgUntFl}, provided-interface=FeSCPR_b_Sch1CH_ChrgUntFl
      FeSCPR_e_Sch1CH_EndMin: variation-point={short-label=vpFeSCPR_e_Sch1CH_EndMin, sw-syscond=1}, nv-provide-com-spec{ram-block-init-value=0, variable=FeSCPR_e_Sch1CH_EndMin}, provided-interface=FeSCPR_e_Sch1CH_EndMin
      NeSCPR_e_NxtSchCP_StrtMin: variation-point={short-label=vpNeSCPR_e_NxtSchCP_StrtMin, sw-syscond=1}, nv-provide-com-spec{ram-block-init-value=0, variable=NeSCPR_e_NxtSchCP_StrtMin}, provided-interface=NeSCPR_e_NxtSchCP_StrtMin
      NeSCPR_k_CabinTempSetPoint: variation-point={short-label=vpNeSCPR_k_CabinTempSetPoint, sw-syscond=1}, nv-provide-com-spec{ram-block-init-value=0, variable=NeSCPR_k_CabinTempSetPoint}, provided-interface=NeSCPR_k_CabinTempSetPoint
      NeSCPR_e_NxtSchCP_Day: variation-point={short-label=vpNeSCPR_e_NxtSchCP_Day, sw-syscond=1}, nv-provide-com-spec{ram-block-init-value=0, variable=NeSCPR_e_NxtSchCP_Day}, provided-interface=NeSCPR_e_NxtSchCP_Day
      NeSCPR_e_NxtSchCP_StrtHr: variation-point={short-label=vpNeSCPR_e_NxtSchCP_StrtHr, sw-syscond=1}, nv-provide-com-spec{ram-block-init-value=0, variable=NeSCPR_e_NxtSchCP_StrtHr}, provided-interface=NeSCPR_e_NxtSchCP_StrtHr
      NeSCPR_e_NxtSchCH_StrtHr: variation-point={short-label=vpNeSCPR_e_NxtSchCH_StrtHr, sw-syscond=1}, nv-provide-com-spec{ram-block-init-value=0, variable=NeSCPR_e_NxtSchCH_StrtHr}, provided-interface=NeSCPR_e_NxtSchCH_StrtHr
      NeSCPR_e_NxtSchCH_StrtMin: variation-point={short-label=vpNeSCPR_e_NxtSchCH_StrtMin, sw-syscond=1}, nv-provide-com-spec{ram-block-init-value=0, variable=NeSCPR_e_NxtSchCH_StrtMin}, provided-interface=NeSCPR_e_NxtSchCH_StrtMin
      NeSCPR_e_NxtSchCH_StrtDay: variation-point={short-label=vpNeSCPR_e_NxtSchCH_StrtDay, sw-syscond=1}, nv-provide-com-spec{ram-block-init-value=0, variable=NeSCPR_e_NxtSchCH_StrtDay}, provided-interface=NeSCPR_e_NxtSchCH_StrtDay
      NeSCPR_e_NxtSchCH_EndHr: variation-point={short-label=vpNeSCPR_e_NxtSchCH_EndHr, sw-syscond=1}, nv-provide-com-spec{ram-block-init-value=0, variable=NeSCPR_e_NxtSchCH_EndHr}, provided-interface=NeSCPR_e_NxtSchCH_EndHr
      NeSCPR_e_NxtSchCH_EndMin: variation-point={short-label=vpNeSCPR_e_NxtSchCH_EndMin, sw-syscond=1}, nv-provide-com-spec{ram-block-init-value=0, variable=NeSCPR_e_NxtSchCH_EndMin}, provided-interface=NeSCPR_e_NxtSchCH_EndMin
      FeSCPR_b_Sch1CH_DNR: variation-point={short-label=vpFeSCPR_b_Sch1CH_DNR, sw-syscond=1}, nv-provide-com-spec{ram-block-init-value=0, variable=FeSCPR_b_Sch1CH_DNR}, provided-interface=FeSCPR_b_Sch1CH_DNR
      NeSCPR_e_NxtSchCH_EndDay: variation-point={short-label=vpNeSCPR_e_NxtSchCH_EndDay, sw-syscond=1}, nv-provide-com-spec{ram-block-init-value=0, variable=NeSCPR_e_NxtSchCH_EndDay}, provided-interface=NeSCPR_e_NxtSchCH_EndDay
      FeSCPR_b_Sch1CP_Enbl: variation-point={short-label=vpFeSCPR_b_Sch1CP_Enbl, sw-syscond=1}, nv-provide-com-spec{ram-block-init-value=0, variable=FeSCPR_b_Sch1CP_Enbl}, provided-interface=FeSCPR_b_Sch1CP_Enbl
      FeSCPR_T_Sch1CP_DepTemp: variation-point={short-label=vpFeSCPR_T_Sch1CP_DepTemp, sw-syscond=1}, nv-provide-com-spec{ram-block-init-value=-8888888, variable=FeSCPR_T_Sch1CP_DepTemp}, provided-interface=FeSCPR_T_Sch1CP_DepTemp
      FeSCPR_e_Sch1CP_Allow: variation-point={short-label=vpFeSCPR_e_Sch1CP_Allow, sw-syscond=1}, nv-provide-com-spec{ram-block-init-value=CeCITR_e_AnyTime, variable=FeSCPR_e_Sch1CP_Allow}, provided-interface=FeSCPR_e_Sch1CP_Allow
      FeSCPR_e_Sch1CP_DepHr: variation-point={short-label=vpFeSCPR_e_Sch1CP_DepHr, sw-syscond=1}, nv-provide-com-spec{ram-block-init-value=0, variable=FeSCPR_e_Sch1CP_DepHr}, provided-interface=FeSCPR_e_Sch1CP_DepHr
      FeSCPR_e_Sch1CP_DepMin: variation-point={short-label=vpFeSCPR_e_Sch1CP_DepMin, sw-syscond=1}, nv-provide-com-spec{ram-block-init-value=0, variable=FeSCPR_e_Sch1CP_DepMin}, provided-interface=FeSCPR_e_Sch1CP_DepMin
      FeSCPR_b_CancelActFOTA: variation-point={short-label=vpFeSCPR_b_CancelActFOTA, sw-syscond=1}, nv-provide-com-spec{ram-block-init-value=0, variable=FeSCPR_b_CancelActFOTA}, provided-interface=FeSCPR_b_CancelActFOTA
      FeSCPR_b_ChrgNowLatch: variation-point={short-label=vpFeSCPR_b_ChrgNowLatch, sw-syscond=1}, nv-provide-com-spec{ram-block-init-value=0, variable=FeSCPR_b_ChrgNowLatch}, provided-interface=FeSCPR_b_ChrgNowLatch
      FeSCPR_b_FOTA_Conflict: variation-point={short-label=vpFeSCPR_b_FOTA_Conflict, sw-syscond=1}, nv-provide-com-spec{ram-block-init-value=0, variable=FeSCPR_b_FOTA_Conflict}, provided-interface=FeSCPR_b_FOTA_Conflict
      FeSCPR_e_FOTA_Install_Type: variation-point={short-label=vpFeSCPR_e_FOTA_Install_Type, sw-syscond=1}, nv-provide-com-spec{ram-block-init-value=CeCITR_e_NoFOTA, variable=FeSCPR_e_FOTA_Install_Type}, provided-interface=FeSCPR_e_FOTA_Install_Type
      FeSCPR_g_ChrgNowMaxTimetoPlugin: variation-point={short-label=vpFeSCPR_g_ChrgNowMaxTimetoPlugin, sw-syscond=1}, nv-provide-com-spec{ram-block-init-value=0, variable=FeSCPR_g_ChrgNowMaxTimetoPlugin}, provided-interface=FeSCPR_g_ChrgNowMaxTimetoPlugin
      NeSCPR_Pct_SOCArb: variation-point={short-label=vpNeSCPR_Pct_SOCArb, sw-syscond=1}, nv-provide-com-spec{ram-block-init-value=0, variable=NeSCPR_Pct_SOCArb}, provided-interface=NeSCPR_Pct_SOCArb
      NeSCPR_b_AllowCancel: variation-point={short-label=vpNeSCPR_b_AllowCancel, sw-syscond=1}, nv-provide-com-spec{ram-block-init-value=0, variable=NeSCPR_b_AllowCancel}, provided-interface=NeSCPR_b_AllowCancel
      NeSCPR_b_CancSchedIsUF: variation-point={short-label=vpNeSCPR_b_CancSchedIsUF, sw-syscond=1}, nv-provide-com-spec{ram-block-init-value=0, variable=NeSCPR_b_CancSchedIsUF}, provided-interface=NeSCPR_b_CancSchedIsUF
      NeSCPR_b_CancWindow: variation-point={short-label=vpNeSCPR_b_CancWindow, sw-syscond=1}, nv-provide-com-spec{ram-block-init-value=0, variable=NeSCPR_b_CancWindow}, provided-interface=NeSCPR_b_CancWindow
      NeSCPR_b_ChrgComplete: variation-point={short-label=vpNeSCPR_b_ChrgComplete, sw-syscond=1}, nv-provide-com-spec{ram-block-init-value=0, variable=NeSCPR_b_ChrgComplete}, provided-interface=NeSCPR_b_ChrgComplete
      NeSCPR_b_PluginLatchOverride: variation-point={short-label=vpNeSCPR_b_PluginLatchOverride, sw-syscond=1}, nv-provide-com-spec{ram-block-init-value=0, variable=NeSCPR_b_PluginLatchOverride}, provided-interface=NeSCPR_b_PluginLatchOverride
      NeSCPR_b_RadioRqLstVldStt: variation-point={short-label=vpNeSCPR_b_RadioRqLstVldStt, sw-syscond=1}, nv-provide-com-spec{ram-block-init-value=0, variable=NeSCPR_b_RadioRqLstVldStt}, provided-interface=NeSCPR_b_RadioRqLstVldStt
      NeSCPR_b_StopChrg: variation-point={short-label=vpNeSCPR_b_StopChrg, sw-syscond=1}, nv-provide-com-spec{ram-block-init-value=0, variable=NeSCPR_b_StopChrg}, provided-interface=NeSCPR_b_StopChrg
      NeSCPR_b_xMinUF: variation-point={short-label=vpNeSCPR_b_xMinUF, sw-syscond=1}, nv-provide-com-spec{ram-block-init-value=0, variable=NeSCPR_b_xMinUF}, provided-interface=NeSCPR_b_xMinUF
      NeSCPR_b_xMinUFCancel: variation-point={short-label=vpNeSCPR_b_xMinUFCancel, sw-syscond=1}, nv-provide-com-spec{ram-block-init-value=0, variable=NeSCPR_b_xMinUFCancel}, provided-interface=NeSCPR_b_xMinUFCancel
      NeSCPR_e_CancStartIdxHold: variation-point={short-label=vpNeSCPR_e_CancStartIdxHold, sw-syscond=1}, nv-provide-com-spec{ram-block-init-value=0, variable=NeSCPR_e_CancStartIdxHold}, provided-interface=NeSCPR_e_CancStartIdxHold
      NeSCPR_e_CancelStartIndx: variation-point={short-label=vpNeSCPR_e_CancelStartIndx, sw-syscond=1}, nv-provide-com-spec{ram-block-init-value=0, variable=NeSCPR_e_CancelStartIndx}, provided-interface=NeSCPR_e_CancelStartIndx
      NeSCPR_e_EndIndexCanc: variation-point={short-label=vpNeSCPR_e_EndIndexCanc, sw-syscond=1}, nv-provide-com-spec{ram-block-init-value=0, variable=NeSCPR_e_EndIndexCanc}, provided-interface=NeSCPR_e_EndIndexCanc
      NeSCPR_e_LastNowIndex: variation-point={short-label=vpNeSCPR_e_LastNowIndex, sw-syscond=1}, nv-provide-com-spec{ram-block-init-value=0, variable=NeSCPR_e_LastNowIndex}, provided-interface=NeSCPR_e_LastNowIndex
      NeSCPR_g_DoNotRepeatValSch1: variation-point={short-label=vpNeSCPR_g_DoNotRepeatValSch1, sw-syscond=1}, nv-provide-com-spec{ram-block-init-value=0, variable=NeSCPR_g_DoNotRepeatValSch1}, provided-interface=NeSCPR_g_DoNotRepeatValSch1
      NeSCPR_g_DoNotRepeatValSch2: variation-point={short-label=vpNeSCPR_g_DoNotRepeatValSch2, sw-syscond=1}, nv-provide-com-spec{ram-block-init-value=0, variable=NeSCPR_g_DoNotRepeatValSch2}, provided-interface=NeSCPR_g_DoNotRepeatValSch2
      NeSCPR_g_Sch1CP_DNRvalue: variation-point={short-label=vpNeSCPR_g_Sch1CP_DNRvalue, sw-syscond=1}, nv-provide-com-spec{ram-block-init-value=0, variable=NeSCPR_g_Sch1CP_DNRvalue}, provided-interface=NeSCPR_g_Sch1CP_DNRvalue
      NeSCPR_g_Sch2CP_DNRvalue: variation-point={short-label=vpNeSCPR_g_Sch2CP_DNRvalue, sw-syscond=1}, nv-provide-com-spec{ram-block-init-value=0, variable=NeSCPR_g_Sch2CP_DNRvalue}, provided-interface=NeSCPR_g_Sch2CP_DNRvalue
      NeSCPR_k_CancGlEndTrack: variation-point={short-label=vpNeSCPR_k_CancGlEndTrack, sw-syscond=1}, nv-provide-com-spec{ram-block-init-value=0, variable=NeSCPR_k_CancGlEndTrack}, provided-interface=NeSCPR_k_CancGlEndTrack
      NeSCPR_k_CancGlStartTrack: variation-point={short-label=vpNeSCPR_k_CancGlStartTrack, sw-syscond=1}, nv-provide-com-spec{ram-block-init-value=0, variable=NeSCPR_k_CancGlStartTrack}, provided-interface=NeSCPR_k_CancGlStartTrack
      NeSCPR_k_CancOverlapTrack: variation-point={short-label=vpNeSCPR_k_CancOverlapTrack, sw-syscond=1}, nv-provide-com-spec{ram-block-init-value=0, variable=NeSCPR_k_CancOverlapTrack}, provided-interface=NeSCPR_k_CancOverlapTrack
      NeSCPR_k_LastRTC: variation-point={short-label=vpNeSCPR_k_LastRTC, sw-syscond=1}, nv-provide-com-spec{ram-block-init-value=0, variable=NeSCPR_k_LastRTC}, provided-interface=NeSCPR_k_LastRTC
      NeSCPR_k_LastSecond: variation-point={short-label=vpNeSCPR_k_LastSecond, sw-syscond=1}, nv-provide-com-spec{ram-block-init-value=0, variable=NeSCPR_k_LastSecond}, provided-interface=NeSCPR_k_LastSecond
      NeSCPR_e_Sch1CoCH_StopHr: variation-point={short-label=vpNeSCPR_e_Sch1CoCH_StopHr, sw-syscond=1}, nv-provide-com-spec{ram-block-init-value=0, variable=NeSCPR_e_Sch1CoCH_StopHr}, provided-interface=NeSCPR_e_Sch1CoCH_StopHr
      NeSCPR_e_Sch1CoCH_StopMin: variation-point={short-label=vpNeSCPR_e_Sch1CoCH_StopMin, sw-syscond=1}, nv-provide-com-spec{ram-block-init-value=0, variable=NeSCPR_e_Sch1CoCH_StopMin}, provided-interface=NeSCPR_e_Sch1CoCH_StopMin
      NeSCPR_y_Sch1CoCH_Day: variation-point={short-label=vpNeSCPR_y_Sch1CoCH_Day, sw-syscond=1}, nv-provide-com-spec{ram-block-init-value=0, variable=NeSCPR_y_Sch1CoCH_Day}, provided-interface=NeSCPR_y_Sch1CoCH_Day
      NeSCPR_b_Sch1CoCH_Enbl: variation-point={short-label=vpNeSCPR_b_Sch1CoCH_Enbl, sw-syscond=1}, nv-provide-com-spec{ram-block-init-value=0, variable=NeSCPR_b_Sch1CoCH_Enbl}, provided-interface=NeSCPR_b_Sch1CoCH_Enbl
      NeSCPR_Pct_Sch1CoCH_ImmSOCtrgt: variation-point={short-label=vpNeSCPR_Pct_Sch1CoCH_ImmSOCtrgt, sw-syscond=1}, nv-provide-com-spec{ram-block-init-value=0, variable=NeSCPR_Pct_Sch1CoCH_ImmSOCtrgt}, provided-interface=NeSCPR_Pct_Sch1CoCH_ImmSOCtrgt
      NeSCPR_Pct_Sch1CoCH_ExtSOCtrgt: variation-point={short-label=vpNeSCPR_Pct_Sch1CoCH_ExtSOCtrgt, sw-syscond=1}, nv-provide-com-spec{ram-block-init-value=0, variable=NeSCPR_Pct_Sch1CoCH_ExtSOCtrgt}, provided-interface=NeSCPR_Pct_Sch1CoCH_ExtSOCtrgt
      NeSCPR_e_Sch1CH_SchType: variation-point={short-label=vpNeSCPR_e_Sch1CH_SchType, sw-syscond=1}, nv-provide-com-spec{ram-block-init-value=CeCITR_e_No_Selection, variable=NeSCPR_e_Sch1CH_SchType}, provided-interface=NeSCPR_e_Sch1CH_SchType
      NeSCPR_e_Sch2CoCH_StopHr: variation-point={short-label=vpNeSCPR_e_Sch2CoCH_StopHr, sw-syscond=1}, nv-provide-com-spec{ram-block-init-value=0, variable=NeSCPR_e_Sch2CoCH_StopHr}, provided-interface=NeSCPR_e_Sch2CoCH_StopHr
      NeSCPR_e_Sch2CoCH_StopMin: variation-point={short-label=vpNeSCPR_e_Sch2CoCH_StopMin, sw-syscond=1}, nv-provide-com-spec{ram-block-init-value=0, variable=NeSCPR_e_Sch2CoCH_StopMin}, provided-interface=NeSCPR_e_Sch2CoCH_StopMin
      NeSCPR_y_Sch2CoCH_Day: variation-point={short-label=vpNeSCPR_y_Sch2CoCH_Day, sw-syscond=1}, nv-provide-com-spec{ram-block-init-value=0, variable=NeSCPR_y_Sch2CoCH_Day}, provided-interface=NeSCPR_y_Sch2CoCH_Day
      NeSCPR_b_Sch2CoCH_Enbl: variation-point={short-label=vpNeSCPR_b_Sch2CoCH_Enbl, sw-syscond=1}, nv-provide-com-spec{ram-block-init-value=0, variable=NeSCPR_b_Sch2CoCH_Enbl}, provided-interface=NeSCPR_b_Sch2CoCH_Enbl
      NeSCPR_Pct_Sch2CoCH_ImmSOCtrgt: variation-point={short-label=vpNeSCPR_Pct_Sch2CoCH_ImmSOCtrgt, sw-syscond=1}, nv-provide-com-spec{ram-block-init-value=0, variable=NeSCPR_Pct_Sch2CoCH_ImmSOCtrgt}, provided-interface=NeSCPR_Pct_Sch2CoCH_ImmSOCtrgt
      NeSCPR_Pct_Sch2CoCH_ExtSOCtrgt: variation-point={short-label=vpNeSCPR_Pct_Sch2CoCH_ExtSOCtrgt, sw-syscond=1}, nv-provide-com-spec{ram-block-init-value=0, variable=NeSCPR_Pct_Sch2CoCH_ExtSOCtrgt}, provided-interface=NeSCPR_Pct_Sch2CoCH_ExtSOCtrgt
      NeSCPR_e_Sch2CH_SchType: variation-point={short-label=vpNeSCPR_e_Sch2CH_SchType, sw-syscond=1}, nv-provide-com-spec{ram-block-init-value=CeCITR_e_No_Selection, variable=NeSCPR_e_Sch2CH_SchType}, provided-interface=NeSCPR_e_Sch2CH_SchType
      NeSCPR_b_CoCh_VehLocation: variation-point={short-label=vpNeSCPR_b_CoCh_VehLocation, sw-syscond=1}, nv-provide-com-spec{ram-block-init-value=0, variable=NeSCPR_b_CoCh_VehLocation}, provided-interface=NeSCPR_b_CoCh_VehLocation
      NeSCPR_b_CoCH_Sch1_DNR: variation-point={short-label=vpNeSCPR_b_CoCH_Sch1_DNR, sw-syscond=1}, nv-provide-com-spec{ram-block-init-value=0, variable=NeSCPR_b_CoCH_Sch1_DNR}, provided-interface=NeSCPR_b_CoCH_Sch1_DNR
      NeSCPR_b_CoCH_Sch2_DNR: variation-point={short-label=vpNeSCPR_b_CoCH_Sch2_DNR, sw-syscond=1}, nv-provide-com-spec{ram-block-init-value=0, variable=NeSCPR_b_CoCH_Sch2_DNR}, provided-interface=NeSCPR_b_CoCH_Sch2_DNR
      NeSCPR_g_Sch1CoCH_DNRvalue: variation-point={short-label=vpNeSCPR_g_Sch1CoCH_DNRvalue, sw-syscond=1}, nv-provide-com-spec{ram-block-init-value=0, variable=NeSCPR_g_Sch1CoCH_DNRvalue}, provided-interface=NeSCPR_g_Sch1CoCH_DNRvalue
      NeSCPR_g_Sch2CoCH_DNRvalue: variation-point={short-label=vpNeSCPR_g_Sch2CoCH_DNRvalue, sw-syscond=1}, nv-provide-com-spec{ram-block-init-value=0, variable=NeSCPR_g_Sch2CoCH_DNRvalue}, provided-interface=NeSCPR_g_Sch2CoCH_DNRvalue
    behavior IB_SCPR: data-type-mapping=msADTtoIDTMapping, handle-termination-and-restart=NO-SUPPORT, included-data-type-set=data-type=[TeSCPR_e_DayOfWeek, TeSCPR_e_Intent]
      timing event Event_MedTEH: start-on-event=SCPR_MedTEH, period=0.1
      init event Event_SCPR_ac_Init: start-on-event=SCPR_ac_Init
      init event Event_PwrOff: start-on-event=SCPR_PwrOff
      init event Event_PwrOn: start-on-event=SCPR_PwrOn
      4 x runnable:
        SCPR_ac_Init
          data-send-points:
            13 x access:
              OUT_VeSCPR_e_Sch3_AllowSts_Value: accessed-variable=VeSCPR_e_Sch3_AllowSts.Value
              OUT_VeSCPR_e_Sch4_AllowSts_Value: accessed-variable=VeSCPR_e_Sch4_AllowSts.Value
              OUT_VeSCPR_e_Sch1_ChrgSchType_Sts_Value: accessed-variable=VeSCPR_e_Sch1_ChrgSchType_Sts.Value
              OUT_VeSCPR_e_Sch2_ChrgSchType_Sts_Value: accessed-variable=VeSCPR_e_Sch2_ChrgSchType_Sts.Value
              OUT_VeSCPR_e_CoopChrgStatus_Value: accessed-variable=VeSCPR_e_CoopChrgStatus.Value
              OUT_VeSCPR_e_Next_ChrgSchType_Value: accessed-variable=VeSCPR_e_Next_ChrgSchType.Value
              OUT_VeSCPR_e_SchCP_Allow_Value: accessed-variable=VeSCPR_e_SchCP_Allow.Value
              OUT_VeSCPR_e_CPIM_Icon1_Cmd_Value: accessed-variable=VeSCPR_e_CPIM_Icon1_Cmd.Value
              OUT_VeSCPR_e_CPIM_Icon2_Cmd_Value: accessed-variable=VeSCPR_e_CPIM_Icon2_Cmd.Value
              OUT_VeSCPR_e_Sch{1..3}_Type_Sts_Value: accessed-variable=VeSCPR_e_Sch{1..3}_Type_Sts.Value
              OUT_VeSCPR_e_InitStatus_Value: accessed-variable=VeSCPR_e_InitStatus.Value
        SCPR_MedTEH: variation-point={short-label=vpSCPR_MedTEH, sw-syscond=1}
          data-receive-point-by-arguments:
            159 x access:
              IN_VeBPCR_Pct_HV_BatPackSOC_Arb_Value: accessed-variable=VeBPCR_Pct_HV_BatPackSOC_Arb.Value, variation-point={short-label=vpIN_VeBPCR_Pct_HV_BatPackSOC_Arb_Value, sw-syscond=1}
              IN_VeBPCR_q_FullAmpHrCap_Value: accessed-variable=VeBPCR_q_FullAmpHrCap.Value, variation-point={short-label=vpIN_VeBPCR_q_FullAmpHrCap_Value, sw-syscond=1}
              IN_VeCITR_K_DateTmDay_Value: accessed-variable=VeCITR_K_DateTmDay.Value, variation-point={short-label=vpIN_VeCITR_K_DateTmDay_Value, sw-syscond=1}
              IN_VeCITR_K_DateTmHour_Value: accessed-variable=VeCITR_K_DateTmHour.Value, variation-point={short-label=vpIN_VeCITR_K_DateTmHour_Value, sw-syscond=1}
              IN_VeCITR_K_DateTmMin_Value: accessed-variable=VeCITR_K_DateTmMin.Value, variation-point={short-label=vpIN_VeCITR_K_DateTmMin_Value, sw-syscond=1}
              IN_VeCITR_K_DateTmMon_Value: accessed-variable=VeCITR_K_DateTmMon.Value, variation-point={short-label=vpIN_VeCITR_K_DateTmMon_Value, sw-syscond=1}
              IN_VeCITR_K_DateTmSec_Value: accessed-variable=VeCITR_K_DateTmSec.Value, variation-point={short-label=vpIN_VeCITR_K_DateTmSec_Value, sw-syscond=1}
              IN_VeCITR_K_DateTmYear_Value: accessed-variable=VeCITR_K_DateTmYear.Value, variation-point={short-label=vpIN_VeCITR_K_DateTmYear_Value, sw-syscond=1}
              IN_VeCITR_K_Date_Day1_Value: accessed-variable=VeCITR_K_Date_Day1.Value, variation-point={short-label=vpIN_VeCITR_K_Date_Day1_Value, sw-syscond=1}
              IN_VeCITR_K_Date_Day2_Value: accessed-variable=VeCITR_K_Date_Day2.Value, variation-point={short-label=vpIN_VeCITR_K_Date_Day2_Value, sw-syscond=1}
              IN_VeCITR_K_Date_Month1_Value: accessed-variable=VeCITR_K_Date_Month1.Value, variation-point={short-label=vpIN_VeCITR_K_Date_Month1_Value, sw-syscond=1}
              IN_VeCITR_K_Date_Month2_Value: accessed-variable=VeCITR_K_Date_Month2.Value, variation-point={short-label=vpIN_VeCITR_K_Date_Month2_Value, sw-syscond=1}
              IN_VeCITR_K_Date_Year{1..4}_Value: accessed-variable=VeCITR_K_Date_Year{1..4}.Value, variation-point={short-label=vpIN_VeCITR_K_Date_Year{1..4}_Value, sw-syscond=1}
              IN_VeCITR_K_HU_Sch1_Day_Value: accessed-variable=VeCITR_K_HU_Sch1_Day.Value, variation-point={short-label=vpIN_VeCITR_K_HU_Sch1_Day_Value, sw-syscond=1}
              IN_VeCITR_K_HU_Sch1_End_Time_Hr_Value: accessed-variable=VeCITR_K_HU_Sch1_End_Time_Hr.Value, variation-point={short-label=vpIN_VeCITR_K_HU_Sch1_End_Time_Hr_Value, sw-syscond=1}
              IN_VeCITR_K_HU_Sch1_End_Time_Min_Value: accessed-variable=VeCITR_K_HU_Sch1_End_Time_Min.Value, variation-point={short-label=vpIN_VeCITR_K_HU_Sch1_End_Time_Min_Value, sw-syscond=1}
              IN_VeCITR_K_HU_Sch1_Start_Time_Hr_Value: accessed-variable=VeCITR_K_HU_Sch1_Start_Time_Hr.Value, variation-point={short-label=vpIN_VeCITR_K_HU_Sch1_Start_Time_Hr_Value, sw-syscond=1}
              IN_VeCITR_K_HU_Sch1_Start_Time_Min_Value: accessed-variable=VeCITR_K_HU_Sch1_Start_Time_Min.Value, variation-point={short-label=vpIN_VeCITR_K_HU_Sch1_Start_Time_Min_Value, sw-syscond=1}
              IN_VeCITR_K_HU_Sch2_Day_Value: accessed-variable=VeCITR_K_HU_Sch2_Day.Value, variation-point={short-label=vpIN_VeCITR_K_HU_Sch2_Day_Value, sw-syscond=1}
              IN_VeCITR_K_HU_Sch2_End_Time_Hr_Value: accessed-variable=VeCITR_K_HU_Sch2_End_Time_Hr.Value, variation-point={short-label=vpIN_VeCITR_K_HU_Sch2_End_Time_Hr_Value, sw-syscond=1}
              IN_VeCITR_K_HU_Sch2_End_Time_Min_Value: accessed-variable=VeCITR_K_HU_Sch2_End_Time_Min.Value, variation-point={short-label=vpIN_VeCITR_K_HU_Sch2_End_Time_Min_Value, sw-syscond=1}
              IN_VeCITR_K_HU_Sch2_Start_Time_Hr_Value: accessed-variable=VeCITR_K_HU_Sch2_Start_Time_Hr.Value, variation-point={short-label=vpIN_VeCITR_K_HU_Sch2_Start_Time_Hr_Value, sw-syscond=1}
              IN_VeCITR_K_HU_Sch2_Start_Time_Min_Value: accessed-variable=VeCITR_K_HU_Sch2_Start_Time_Min.Value, variation-point={short-label=vpIN_VeCITR_K_HU_Sch2_Start_Time_Min_Value, sw-syscond=1}
              IN_VeCITR_K_HU_Sch3_Day_Value: accessed-variable=VeCITR_K_HU_Sch3_Day.Value, variation-point={short-label=vpIN_VeCITR_K_HU_Sch3_Day_Value, sw-syscond=1}
              IN_VeCITR_K_HU_Sch3_Start_Time_Hr_Value: accessed-variable=VeCITR_K_HU_Sch3_Start_Time_Hr.Value, variation-point={short-label=vpIN_VeCITR_K_HU_Sch3_Start_Time_Hr_Value, sw-syscond=1}
              IN_VeCITR_K_HU_Sch3_Start_Time_Min_Value: accessed-variable=VeCITR_K_HU_Sch3_Start_Time_Min.Value, variation-point={short-label=vpIN_VeCITR_K_HU_Sch3_Start_Time_Min_Value, sw-syscond=1}
              IN_VeCITR_K_HU_Sch4_Day_Value: accessed-variable=VeCITR_K_HU_Sch4_Day.Value, variation-point={short-label=vpIN_VeCITR_K_HU_Sch4_Day_Value, sw-syscond=1}
              IN_VeCITR_K_HU_Sch4_Start_Time_Hr_Value: accessed-variable=VeCITR_K_HU_Sch4_Start_Time_Hr.Value, variation-point={short-label=vpIN_VeCITR_K_HU_Sch4_Start_Time_Hr_Value, sw-syscond=1}
              IN_VeCITR_K_HU_Sch4_Start_Time_Min_Value: accessed-variable=VeCITR_K_HU_Sch4_Start_Time_Min.Value, variation-point={short-label=vpIN_VeCITR_K_HU_Sch4_Start_Time_Min_Value, sw-syscond=1}
              IN_VeCITR_K_TBM_Sch1_Day_Value: accessed-variable=VeCITR_K_TBM_Sch1_Day.Value, variation-point={short-label=vpIN_VeCITR_K_TBM_Sch1_Day_Value, sw-syscond=1}
              IN_VeCITR_K_TBM_Sch1_End_Time_Hr_Value: accessed-variable=VeCITR_K_TBM_Sch1_End_Time_Hr.Value, variation-point={short-label=vpIN_VeCITR_K_TBM_Sch1_End_Time_Hr_Value, sw-syscond=1}
              IN_VeCITR_K_TBM_Sch1_End_Time_Min_Value: accessed-variable=VeCITR_K_TBM_Sch1_End_Time_Min.Value, variation-point={short-label=vpIN_VeCITR_K_TBM_Sch1_End_Time_Min_Value, sw-syscond=1}
              IN_VeCITR_K_TBM_Sch1_Start_Time_Hr_Value: accessed-variable=VeCITR_K_TBM_Sch1_Start_Time_Hr.Value, variation-point={short-label=vpIN_VeCITR_K_TBM_Sch1_Start_Time_Hr_Value, sw-syscond=1}
              IN_VeCITR_K_TBM_Sch1_Start_Time_Min_Value: accessed-variable=VeCITR_K_TBM_Sch1_Start_Time_Min.Value, variation-point={short-label=vpIN_VeCITR_K_TBM_Sch1_Start_Time_Min_Value, sw-syscond=1}
              IN_VeCITR_K_TBM_Sch2_Day_Value: accessed-variable=VeCITR_K_TBM_Sch2_Day.Value, variation-point={short-label=vpIN_VeCITR_K_TBM_Sch2_Day_Value, sw-syscond=1}
              IN_VeCITR_K_TBM_Sch2_End_Time_Hr_Value: accessed-variable=VeCITR_K_TBM_Sch2_End_Time_Hr.Value, variation-point={short-label=vpIN_VeCITR_K_TBM_Sch2_End_Time_Hr_Value, sw-syscond=1}
              IN_VeCITR_K_TBM_Sch2_End_Time_Min_Value: accessed-variable=VeCITR_K_TBM_Sch2_End_Time_Min.Value, variation-point={short-label=vpIN_VeCITR_K_TBM_Sch2_End_Time_Min_Value, sw-syscond=1}
              IN_VeCITR_K_TBM_Sch2_Start_Time_Hr_Value: accessed-variable=VeCITR_K_TBM_Sch2_Start_Time_Hr.Value, variation-point={short-label=vpIN_VeCITR_K_TBM_Sch2_Start_Time_Hr_Value, sw-syscond=1}
              IN_VeCITR_K_TBM_Sch2_Start_Time_Min_Value: accessed-variable=VeCITR_K_TBM_Sch2_Start_Time_Min.Value, variation-point={short-label=vpIN_VeCITR_K_TBM_Sch2_Start_Time_Min_Value, sw-syscond=1}
              IN_VeCITR_K_TBM_Sch3_Day_Value: accessed-variable=VeCITR_K_TBM_Sch3_Day.Value, variation-point={short-label=vpIN_VeCITR_K_TBM_Sch3_Day_Value, sw-syscond=1}
              IN_VeCITR_K_TBM_Sch3_Start_Time_Hr_Value: accessed-variable=VeCITR_K_TBM_Sch3_Start_Time_Hr.Value, variation-point={short-label=vpIN_VeCITR_K_TBM_Sch3_Start_Time_Hr_Value, sw-syscond=1}
              IN_VeCITR_K_TBM_Sch3_Start_Time_Min_Value: accessed-variable=VeCITR_K_TBM_Sch3_Start_Time_Min.Value, variation-point={short-label=vpIN_VeCITR_K_TBM_Sch3_Start_Time_Min_Value, sw-syscond=1}
              IN_VeCITR_K_TBM_Sch4_Day_Value: accessed-variable=VeCITR_K_TBM_Sch4_Day.Value, variation-point={short-label=vpIN_VeCITR_K_TBM_Sch4_Day_Value, sw-syscond=1}
              IN_VeCITR_K_TBM_Sch4_Start_Time_Hr_Value: accessed-variable=VeCITR_K_TBM_Sch4_Start_Time_Hr.Value, variation-point={short-label=vpIN_VeCITR_K_TBM_Sch4_Start_Time_Hr_Value, sw-syscond=1}
              IN_VeCITR_K_TBM_Sch4_Start_Time_Min_Value: accessed-variable=VeCITR_K_TBM_Sch4_Start_Time_Min.Value, variation-point={short-label=vpIN_VeCITR_K_TBM_Sch4_Start_Time_Min_Value, sw-syscond=1}
              IN_VeCITR_K_Time_Hour1_Value: accessed-variable=VeCITR_K_Time_Hour1.Value, variation-point={short-label=vpIN_VeCITR_K_Time_Hour1_Value, sw-syscond=1}
              IN_VeCITR_K_Time_Hour2_Value: accessed-variable=VeCITR_K_Time_Hour2.Value, variation-point={short-label=vpIN_VeCITR_K_Time_Hour2_Value, sw-syscond=1}
              IN_VeCITR_K_Time_Minute1_Value: accessed-variable=VeCITR_K_Time_Minute1.Value, variation-point={short-label=vpIN_VeCITR_K_Time_Minute1_Value, sw-syscond=1}
              IN_VeCITR_K_Time_Minute2_Value: accessed-variable=VeCITR_K_Time_Minute2.Value, variation-point={short-label=vpIN_VeCITR_K_Time_Minute2_Value, sw-syscond=1}
              IN_VeCITR_Pct_HU_ExtChrgTarget1_Value: accessed-variable=VeCITR_Pct_HU_ExtChrgTarget1.Value, variation-point={short-label=vpIN_VeCITR_Pct_HU_ExtChrgTarget1_Value, sw-syscond=1}
              IN_VeCITR_Pct_HU_ExtChrgTarget2_Value: accessed-variable=VeCITR_Pct_HU_ExtChrgTarget2.Value, variation-point={short-label=vpIN_VeCITR_Pct_HU_ExtChrgTarget2_Value, sw-syscond=1}
              IN_VeCITR_Pct_HU_ImmChrgTarget1_Value: accessed-variable=VeCITR_Pct_HU_ImmChrgTarget1.Value, variation-point={short-label=vpIN_VeCITR_Pct_HU_ImmChrgTarget1_Value, sw-syscond=1}
              IN_VeCITR_Pct_HU_ImmChrgTarget2_Value: accessed-variable=VeCITR_Pct_HU_ImmChrgTarget2.Value, variation-point={short-label=vpIN_VeCITR_Pct_HU_ImmChrgTarget2_Value, sw-syscond=1}
              IN_VeCITR_Pct_TBM_ExtChrgTarget1_Value: accessed-variable=VeCITR_Pct_TBM_ExtChrgTarget1.Value, variation-point={short-label=vpIN_VeCITR_Pct_TBM_ExtChrgTarget1_Value, sw-syscond=1}
              IN_VeCITR_Pct_TBM_ExtChrgTarget2_Value: accessed-variable=VeCITR_Pct_TBM_ExtChrgTarget2.Value, variation-point={short-label=vpIN_VeCITR_Pct_TBM_ExtChrgTarget2_Value, sw-syscond=1}
              IN_VeCITR_Pct_TBM_ImmChrgTarget1_Value: accessed-variable=VeCITR_Pct_TBM_ImmChrgTarget1.Value, variation-point={short-label=vpIN_VeCITR_Pct_TBM_ImmChrgTarget1_Value, sw-syscond=1}
              IN_VeCITR_Pct_TBM_ImmChrgTarget2_Value: accessed-variable=VeCITR_Pct_TBM_ImmChrgTarget2.Value, variation-point={short-label=vpIN_VeCITR_Pct_TBM_ImmChrgTarget2_Value, sw-syscond=1}
              IN_VeCITR_T_HU_Sch3_Temperature_Value: accessed-variable=VeCITR_T_HU_Sch3_Temperature.Value, variation-point={short-label=vpIN_VeCITR_T_HU_Sch3_Temperature_Value, sw-syscond=1}
              IN_VeCITR_T_HU_Sch4_Temperature_Value: accessed-variable=VeCITR_T_HU_Sch4_Temperature.Value, variation-point={short-label=vpIN_VeCITR_T_HU_Sch4_Temperature_Value, sw-syscond=1}
              IN_VeCITR_T_TBM_Sch3_Temperature_Value: accessed-variable=VeCITR_T_TBM_Sch3_Temperature.Value, variation-point={short-label=vpIN_VeCITR_T_TBM_Sch3_Temperature_Value, sw-syscond=1}
              IN_VeCITR_T_TBM_Sch4_Temperature_Value: accessed-variable=VeCITR_T_TBM_Sch4_Temperature.Value, variation-point={short-label=vpIN_VeCITR_T_TBM_Sch4_Temperature_Value, sw-syscond=1}
              IN_VeCITR_b_ChargeNow_Value: accessed-variable=VeCITR_b_ChargeNow.Value, variation-point={short-label=vpIN_VeCITR_b_ChargeNow_Value, sw-syscond=1}
              IN_VeCITR_b_ChrgPortButton_Sts_Value: accessed-variable=VeCITR_b_ChrgPortButton_Sts.Value, variation-point={short-label=vpIN_VeCITR_b_ChrgPortButton_Sts_Value, sw-syscond=1}
              IN_VeCITR_b_CoopCh_VehLocation_Value: accessed-variable=VeCITR_b_CoopCh_VehLocation.Value, variation-point={short-label=vpIN_VeCITR_b_CoopCh_VehLocation_Value, sw-syscond=1}
              IN_VeCITR_b_DateTmDay_FA_Value: accessed-variable=VeCITR_b_DateTmDay_FA.Value, variation-point={short-label=vpIN_VeCITR_b_DateTmDay_FA_Value, sw-syscond=1}
              IN_VeCITR_b_DateTmDay_SgnlRcvd_Value: accessed-variable=VeCITR_b_DateTmDay_SgnlRcvd.Value, variation-point={short-label=vpIN_VeCITR_b_DateTmDay_SgnlRcvd_Value, sw-syscond=1}
              IN_VeCITR_b_Date_Day1_FA_Value: accessed-variable=VeCITR_b_Date_Day1_FA.Value, variation-point={short-label=vpIN_VeCITR_b_Date_Day1_FA_Value, sw-syscond=1}
              IN_VeCITR_b_Date_Day1_SgnlRcvd_Value: accessed-variable=VeCITR_b_Date_Day1_SgnlRcvd.Value, variation-point={short-label=vpIN_VeCITR_b_Date_Day1_SgnlRcvd_Value, sw-syscond=1}
              IN_VeCITR_b_HU_Sch1_ChargeUntilFull_Value: accessed-variable=VeCITR_b_HU_Sch1_ChargeUntilFull.Value, variation-point={short-label=vpIN_VeCITR_b_HU_Sch1_ChargeUntilFull_Value, sw-syscond=1}
              IN_VeCITR_b_HU_Sch1_Day_FA_Value: accessed-variable=VeCITR_b_HU_Sch1_Day_FA.Value, variation-point={short-label=vpIN_VeCITR_b_HU_Sch1_Day_FA_Value, sw-syscond=1}
              IN_VeCITR_b_HU_Sch1_Enbl_Value: accessed-variable=VeCITR_b_HU_Sch1_Enbl.Value, variation-point={short-label=vpIN_VeCITR_b_HU_Sch1_Enbl_Value, sw-syscond=1}
              IN_VeCITR_b_HU_Sch1_End_Time_HrFA_Value: accessed-variable=VeCITR_b_HU_Sch1_End_Time_HrFA.Value, variation-point={short-label=vpIN_VeCITR_b_HU_Sch1_End_Time_HrFA_Value, sw-syscond=1}
              IN_VeCITR_b_HU_Sch1_End_Time_MinFA_Value: accessed-variable=VeCITR_b_HU_Sch1_End_Time_MinFA.Value, variation-point={short-label=vpIN_VeCITR_b_HU_Sch1_End_Time_MinFA_Value, sw-syscond=1}
              IN_VeCITR_b_HU_Sch1_Start_Time_HrFA_Value: accessed-variable=VeCITR_b_HU_Sch1_Start_Time_HrFA.Value, variation-point={short-label=vpIN_VeCITR_b_HU_Sch1_Start_Time_HrFA_Value, sw-syscond=1}
              IN_VeCITR_b_HU_Sch1_Start_Time_MinFA_Value: accessed-variable=VeCITR_b_HU_Sch1_Start_Time_MinFA.Value, variation-point={short-label=vpIN_VeCITR_b_HU_Sch1_Start_Time_MinFA_Value, sw-syscond=1}
              IN_VeCITR_b_HU_Sch1_Submit_Value: accessed-variable=VeCITR_b_HU_Sch1_Submit.Value, variation-point={short-label=vpIN_VeCITR_b_HU_Sch1_Submit_Value, sw-syscond=1}
              IN_VeCITR_b_HU_Sch2_ChargeUntilFull_Value: accessed-variable=VeCITR_b_HU_Sch2_ChargeUntilFull.Value, variation-point={short-label=vpIN_VeCITR_b_HU_Sch2_ChargeUntilFull_Value, sw-syscond=1}
              IN_VeCITR_b_HU_Sch2_Day_FA_Value: accessed-variable=VeCITR_b_HU_Sch2_Day_FA.Value, variation-point={short-label=vpIN_VeCITR_b_HU_Sch2_Day_FA_Value, sw-syscond=1}
              IN_VeCITR_b_HU_Sch2_Enbl_Value: accessed-variable=VeCITR_b_HU_Sch2_Enbl.Value, variation-point={short-label=vpIN_VeCITR_b_HU_Sch2_Enbl_Value, sw-syscond=1}
              IN_VeCITR_b_HU_Sch2_End_Time_HrFA_Value: accessed-variable=VeCITR_b_HU_Sch2_End_Time_HrFA.Value, variation-point={short-label=vpIN_VeCITR_b_HU_Sch2_End_Time_HrFA_Value, sw-syscond=1}
              IN_VeCITR_b_HU_Sch2_End_Time_MinFA_Value: accessed-variable=VeCITR_b_HU_Sch2_End_Time_MinFA.Value, variation-point={short-label=vpIN_VeCITR_b_HU_Sch2_End_Time_MinFA_Value, sw-syscond=1}
              IN_VeCITR_b_HU_Sch2_Start_Time_HrFA_Value: accessed-variable=VeCITR_b_HU_Sch2_Start_Time_HrFA.Value, variation-point={short-label=vpIN_VeCITR_b_HU_Sch2_Start_Time_HrFA_Value, sw-syscond=1}
              IN_VeCITR_b_HU_Sch2_Start_Time_MinFA_Value: accessed-variable=VeCITR_b_HU_Sch2_Start_Time_MinFA.Value, variation-point={short-label=vpIN_VeCITR_b_HU_Sch2_Start_Time_MinFA_Value, sw-syscond=1}
              IN_VeCITR_b_HU_Sch2_Submit_Value: accessed-variable=VeCITR_b_HU_Sch2_Submit.Value, variation-point={short-label=vpIN_VeCITR_b_HU_Sch2_Submit_Value, sw-syscond=1}
              IN_VeCITR_b_HU_Sch3_AllowFA_Value: accessed-variable=VeCITR_b_HU_Sch3_AllowFA.Value, variation-point={short-label=vpIN_VeCITR_b_HU_Sch3_AllowFA_Value, sw-syscond=1}
              IN_VeCITR_b_HU_Sch3_Day_FA_Value: accessed-variable=VeCITR_b_HU_Sch3_Day_FA.Value, variation-point={short-label=vpIN_VeCITR_b_HU_Sch3_Day_FA_Value, sw-syscond=1}
              IN_VeCITR_b_HU_Sch3_Enbl_Value: accessed-variable=VeCITR_b_HU_Sch3_Enbl.Value, variation-point={short-label=vpIN_VeCITR_b_HU_Sch3_Enbl_Value, sw-syscond=1}
              IN_VeCITR_b_HU_Sch3_Start_Time_HrFA_Value: accessed-variable=VeCITR_b_HU_Sch3_Start_Time_HrFA.Value, variation-point={short-label=vpIN_VeCITR_b_HU_Sch3_Start_Time_HrFA_Value, sw-syscond=1}
              IN_VeCITR_b_HU_Sch3_Start_Time_MinFA_Value: accessed-variable=VeCITR_b_HU_Sch3_Start_Time_MinFA.Value, variation-point={short-label=vpIN_VeCITR_b_HU_Sch3_Start_Time_MinFA_Value, sw-syscond=1}
              IN_VeCITR_b_HU_Sch3_Submit_Value: accessed-variable=VeCITR_b_HU_Sch3_Submit.Value, variation-point={short-label=vpIN_VeCITR_b_HU_Sch3_Submit_Value, sw-syscond=1}
              IN_VeCITR_b_HU_Sch3_TemperatureFA_Value: accessed-variable=VeCITR_b_HU_Sch3_TemperatureFA.Value, variation-point={short-label=vpIN_VeCITR_b_HU_Sch3_TemperatureFA_Value, sw-syscond=1}
              IN_VeCITR_b_HU_Sch4_AllowFA_Value: accessed-variable=VeCITR_b_HU_Sch4_AllowFA.Value, variation-point={short-label=vpIN_VeCITR_b_HU_Sch4_AllowFA_Value, sw-syscond=1}
              IN_VeCITR_b_HU_Sch4_Day_FA_Value: accessed-variable=VeCITR_b_HU_Sch4_Day_FA.Value, variation-point={short-label=vpIN_VeCITR_b_HU_Sch4_Day_FA_Value, sw-syscond=1}
              IN_VeCITR_b_HU_Sch4_Enbl_Value: accessed-variable=VeCITR_b_HU_Sch4_Enbl.Value, variation-point={short-label=vpIN_VeCITR_b_HU_Sch4_Enbl_Value, sw-syscond=1}
              IN_VeCITR_b_HU_Sch4_Start_Time_HrFA_Value: accessed-variable=VeCITR_b_HU_Sch4_Start_Time_HrFA.Value, variation-point={short-label=vpIN_VeCITR_b_HU_Sch4_Start_Time_HrFA_Value, sw-syscond=1}
              IN_VeCITR_b_HU_Sch4_Start_Time_MinFA_Value: accessed-variable=VeCITR_b_HU_Sch4_Start_Time_MinFA.Value, variation-point={short-label=vpIN_VeCITR_b_HU_Sch4_Start_Time_MinFA_Value, sw-syscond=1}
              IN_VeCITR_b_HU_Sch4_Submit_Value: accessed-variable=VeCITR_b_HU_Sch4_Submit.Value, variation-point={short-label=vpIN_VeCITR_b_HU_Sch4_Submit_Value, sw-syscond=1}
              IN_VeCITR_b_HU_Sch4_TemperatureFA_Value: accessed-variable=VeCITR_b_HU_Sch4_TemperatureFA.Value, variation-point={short-label=vpIN_VeCITR_b_HU_Sch4_TemperatureFA_Value, sw-syscond=1}
              IN_VeCITR_b_TBMStopChrg_Value: accessed-variable=VeCITR_b_TBMStopChrg.Value, variation-point={short-label=vpIN_VeCITR_b_TBMStopChrg_Value, sw-syscond=1}
              IN_VeCITR_b_TBM_ChargeNow_Value: accessed-variable=VeCITR_b_TBM_ChargeNow.Value, variation-point={short-label=vpIN_VeCITR_b_TBM_ChargeNow_Value, sw-syscond=1}
              IN_VeCITR_b_TBM_Sch1_ChargeUntilFull_Value: accessed-variable=VeCITR_b_TBM_Sch1_ChargeUntilFull.Value, variation-point={short-label=vpIN_VeCITR_b_TBM_Sch1_ChargeUntilFull_Value, sw-syscond=1}
              IN_VeCITR_b_TBM_Sch1_Enbl_Value: accessed-variable=VeCITR_b_TBM_Sch1_Enbl.Value, variation-point={short-label=vpIN_VeCITR_b_TBM_Sch1_Enbl_Value, sw-syscond=1}
              IN_VeCITR_b_TBM_Sch1_Submit_Value: accessed-variable=VeCITR_b_TBM_Sch1_Submit.Value, variation-point={short-label=vpIN_VeCITR_b_TBM_Sch1_Submit_Value, sw-syscond=1}
              IN_VeCITR_b_TBM_Sch2_ChargeUntilFull_Value: accessed-variable=VeCITR_b_TBM_Sch2_ChargeUntilFull.Value, variation-point={short-label=vpIN_VeCITR_b_TBM_Sch2_ChargeUntilFull_Value, sw-syscond=1}
              IN_VeCITR_b_TBM_Sch2_Enbl_Value: accessed-variable=VeCITR_b_TBM_Sch2_Enbl.Value, variation-point={short-label=vpIN_VeCITR_b_TBM_Sch2_Enbl_Value, sw-syscond=1}
              IN_VeCITR_b_TBM_Sch2_Submit_Value: accessed-variable=VeCITR_b_TBM_Sch2_Submit.Value, variation-point={short-label=vpIN_VeCITR_b_TBM_Sch2_Submit_Value, sw-syscond=1}
              IN_VeCITR_b_TBM_Sch3_AllowFA_Value: accessed-variable=VeCITR_b_TBM_Sch3_AllowFA.Value, variation-point={short-label=vpIN_VeCITR_b_TBM_Sch3_AllowFA_Value, sw-syscond=1}
              IN_VeCITR_b_TBM_Sch3_Enbl_Value: accessed-variable=VeCITR_b_TBM_Sch3_Enbl.Value, variation-point={short-label=vpIN_VeCITR_b_TBM_Sch3_Enbl_Value, sw-syscond=1}
              IN_VeCITR_b_TBM_Sch3_Submit_Value: accessed-variable=VeCITR_b_TBM_Sch3_Submit.Value, variation-point={short-label=vpIN_VeCITR_b_TBM_Sch3_Submit_Value, sw-syscond=1}
              IN_VeCITR_b_TBM_Sch3_TemperatureFA_Value: accessed-variable=VeCITR_b_TBM_Sch3_TemperatureFA.Value, variation-point={short-label=vpIN_VeCITR_b_TBM_Sch3_TemperatureFA_Value, sw-syscond=1}
              IN_VeCITR_b_TBM_Sch4_AllowFA_Value: accessed-variable=VeCITR_b_TBM_Sch4_AllowFA.Value, variation-point={short-label=vpIN_VeCITR_b_TBM_Sch4_AllowFA_Value, sw-syscond=1}
              IN_VeCITR_b_TBM_Sch4_Enbl_Value: accessed-variable=VeCITR_b_TBM_Sch4_Enbl.Value, variation-point={short-label=vpIN_VeCITR_b_TBM_Sch4_Enbl_Value, sw-syscond=1}
              IN_VeCITR_b_TBM_Sch4_Submit_Value: accessed-variable=VeCITR_b_TBM_Sch4_Submit.Value, variation-point={short-label=vpIN_VeCITR_b_TBM_Sch4_Submit_Value, sw-syscond=1}
              IN_VeCITR_b_TBM_Sch4_TemperatureFA_Value: accessed-variable=VeCITR_b_TBM_Sch4_TemperatureFA.Value, variation-point={short-label=vpIN_VeCITR_b_TBM_Sch4_TemperatureFA_Value, sw-syscond=1}
              IN_VeCITR_e_CoopCh_ChrgCmd_Value: accessed-variable=VeCITR_e_CoopCh_ChrgCmd.Value, variation-point={short-label=vpIN_VeCITR_e_CoopCh_ChrgCmd_Value, sw-syscond=1}
              IN_VeCITR_e_DoorLockLastElSts_Value: accessed-variable=VeCITR_e_DoorLockLastElSts.Value, variation-point={short-label=vpIN_VeCITR_e_DoorLockLastElSts_Value, sw-syscond=1}
              IN_VeCITR_e_FOTA_Install_Status_Value: accessed-variable=VeCITR_e_FOTA_Install_Status.Value, variation-point={short-label=vpIN_VeCITR_e_FOTA_Install_Status_Value, sw-syscond=1}
              IN_VeCITR_e_FOTA_Install_Type_Value: accessed-variable=VeCITR_e_FOTA_Install_Type.Value, variation-point={short-label=vpIN_VeCITR_e_FOTA_Install_Type_Value, sw-syscond=1}
              IN_VeCITR_e_HU_ChrgSchedType1_Value: accessed-variable=VeCITR_e_HU_ChrgSchedType1.Value, variation-point={short-label=vpIN_VeCITR_e_HU_ChrgSchedType1_Value, sw-syscond=1}
              IN_VeCITR_e_HU_ChrgSchedType2_Value: accessed-variable=VeCITR_e_HU_ChrgSchedType2.Value, variation-point={short-label=vpIN_VeCITR_e_HU_ChrgSchedType2_Value, sw-syscond=1}
              IN_VeCITR_e_HU_Sch3_Allow_Value: accessed-variable=VeCITR_e_HU_Sch3_Allow.Value, variation-point={short-label=vpIN_VeCITR_e_HU_Sch3_Allow_Value, sw-syscond=1}
              IN_VeCITR_e_HU_Sch4_Allow_Value: accessed-variable=VeCITR_e_HU_Sch4_Allow.Value, variation-point={short-label=vpIN_VeCITR_e_HU_Sch4_Allow_Value, sw-syscond=1}
              IN_VeCITR_e_RRM_VP_Level_Value: accessed-variable=VeCITR_e_RRM_VP_Level.Value, variation-point={short-label=vpIN_VeCITR_e_RRM_VP_Level_Value, sw-syscond=1}
              IN_VeCITR_e_TBM_ChrgSchedType1_Value: accessed-variable=VeCITR_e_TBM_ChrgSchedType1.Value, variation-point={short-label=vpIN_VeCITR_e_TBM_ChrgSchedType1_Value, sw-syscond=1}
              IN_VeCITR_e_TBM_ChrgSchedType2_Value: accessed-variable=VeCITR_e_TBM_ChrgSchedType2.Value, variation-point={short-label=vpIN_VeCITR_e_TBM_ChrgSchedType2_Value, sw-syscond=1}
              IN_VeCITR_e_TBM_Sch3_Allow_Value: accessed-variable=VeCITR_e_TBM_Sch3_Allow.Value, variation-point={short-label=vpIN_VeCITR_e_TBM_Sch3_Allow_Value, sw-syscond=1}
              IN_VeCITR_e_TBM_Sch4_Allow_Value: accessed-variable=VeCITR_e_TBM_Sch4_Allow.Value, variation-point={short-label=vpIN_VeCITR_e_TBM_Sch4_Allow_Value, sw-syscond=1}
              IN_VeDMAB_y_StatusByte_IgnKeyOffTmrPerfTooFast_Value: accessed-variable=VeDMAB_y_StatusByte_IgnKeyOffTmrPerfTooFast.Value, variation-point={short-label=vpIN_VeDMAB_y_StatusByte_IgnKeyOffTmrPerfTooFast_Value, sw-syscond=1}
              IN_VeDMAB_y_StatusByte_LosCommBECM_A_Value: accessed-variable=VeDMAB_y_StatusByte_LosCommBECM_A.Value, variation-point={short-label=vpIN_VeDMAB_y_StatusByte_LosCommBECM_A_Value, sw-syscond=1}
              IN_VeDMAB_y_StatusByte_LostCommBCM_Value: accessed-variable=VeDMAB_y_StatusByte_LostCommBCM.Value, variation-point={short-label=vpIN_VeDMAB_y_StatusByte_LostCommBCM_Value, sw-syscond=1}
              IN_VeDMAB_y_StatusByte_LostCommRadio_Value: accessed-variable=VeDMAB_y_StatusByte_LostCommRadio.Value, variation-point={short-label=vpIN_VeDMAB_y_StatusByte_LostCommRadio_Value, sw-syscond=1}
              IN_VeDMAB_y_StatusByte_LostCommTelematicCM_Value: accessed-variable=VeDMAB_y_StatusByte_LostCommTelematicCM.Value, variation-point={short-label=vpIN_VeDMAB_y_StatusByte_LostCommTelematicCM_Value, sw-syscond=1}
              IN_VeHMIR_Pct_HVBatSOC_HCP_Value: accessed-variable=VeHMIR_Pct_HVBatSOC_HCP.Value, variation-point={short-label=vpIN_VeHMIR_Pct_HVBatSOC_HCP_Value, sw-syscond=1}
              IN_VeHPMR_e_HybSysSt_Value: accessed-variable=VeHPMR_e_HybSysSt.Value, variation-point={short-label=vpIN_VeHPMR_e_HybSysSt_Value, sw-syscond=1}
              IN_VeIDCR_I_ChrgCrntAvail_Value: accessed-variable=VeIDCR_I_ChrgCrntAvail.Value, variation-point={short-label=vpIN_VeIDCR_I_ChrgCrntAvail_Value, sw-syscond=1}
              IN_VeOBCR_I_ChrgCurrEstSOC_Value: accessed-variable=VeOBCR_I_ChrgCurrEstSOC.Value, variation-point={short-label=vpIN_VeOBCR_I_ChrgCurrEstSOC_Value, sw-syscond=1}
              IN_VeOBCR_I_MaxAllowedCurr_Value: accessed-variable=VeOBCR_I_MaxAllowedCurr.Value, variation-point={short-label=vpIN_VeOBCR_I_MaxAllowedCurr_Value, sw-syscond=1}
              IN_VeOBCR_b_ChrgSysFault_Value: accessed-variable=VeOBCR_b_ChrgSysFault.Value, variation-point={short-label=vpIN_VeOBCR_b_ChrgSysFault_Value, sw-syscond=1}
              IN_VeOBCR_b_PluggedIn_Value: accessed-variable=VeOBCR_b_PluggedIn.Value, variation-point={short-label=vpIN_VeOBCR_b_PluggedIn_Value, sw-syscond=1}
              IN_VeOBCR_b_SmartEvse_Dtctd_Value: accessed-variable=VeOBCR_b_SmartEvse_Dtctd.Value, variation-point={short-label=vpIN_VeOBCR_b_SmartEvse_Dtctd_Value, sw-syscond=1}
              IN_VeOBCR_e_ChargeType_Value: accessed-variable=VeOBCR_e_ChargeType.Value, variation-point={short-label=vpIN_VeOBCR_e_ChargeType_Value, sw-syscond=1}
              IN_VeOBCR_e_ChargingLevel_Value: accessed-variable=VeOBCR_e_ChargingLevel.Value, variation-point={short-label=vpIN_VeOBCR_e_ChargingLevel_Value, sw-syscond=1}
              IN_VeOBCR_e_ChargingSystemSts_Value: accessed-variable=VeOBCR_e_ChargingSystemSts.Value, variation-point={short-label=vpIN_VeOBCR_e_ChargingSystemSts_Value, sw-syscond=1}
              IN_VeOBCR_e_ChrgSysStat_SF_Value: accessed-variable=VeOBCR_e_ChrgSysStat_SF.Value, variation-point={short-label=vpIN_VeOBCR_e_ChrgSysStat_SF_Value, sw-syscond=1}
              IN_VePLTR_b_ChargeReq_Value: accessed-variable=VePLTR_b_ChargeReq.Value, variation-point={short-label=vpIN_VePLTR_b_ChargeReq_Value, sw-syscond=1}
              IN_VePLTR_b_ChargeReqSgnlRcvd_Value: accessed-variable=VePLTR_b_ChargeReqSgnlRcvd.Value, variation-point={short-label=vpIN_VePLTR_b_ChargeReqSgnlRcvd_Value, sw-syscond=1}
              IN_VePLTR_e_ProxyHybridType_Value: accessed-variable=VePLTR_e_ProxyHybridType.Value, variation-point={short-label=vpIN_VePLTR_e_ProxyHybridType_Value, sw-syscond=1}
              IN_VePLTR_t_RTC_CurrentTime_Value: accessed-variable=VePLTR_t_RTC_CurrentTime.Value, variation-point={short-label=vpIN_VePLTR_t_RTC_CurrentTime_Value, sw-syscond=1}
              IN_VePMDR_e_PMM_PowerMode_Value: accessed-variable=VePMDR_e_PMM_PowerMode.Value, variation-point={short-label=vpIN_VePMDR_e_PMM_PowerMode_Value, sw-syscond=1}
              IN_VeSSDR_b_CabPrecDny_BattCond_Value: accessed-variable=VeSSDR_b_CabPrecDny_BattCond.Value, variation-point={short-label=vpIN_VeSSDR_b_CabPrecDny_BattCond_Value, sw-syscond=1}
              IN_VeSSDR_b_HVBatPerWUThermal_Value: accessed-variable=VeSSDR_b_HVBatPerWUThermal.Value, variation-point={short-label=vpIN_VeSSDR_b_HVBatPerWUThermal_Value, sw-syscond=1}
              IN_VeSSDR_b_HV_PerWU_CabinPre_Value: accessed-variable=VeSSDR_b_HV_PerWU_CabinPre.Value, variation-point={short-label=vpIN_VeSSDR_b_HV_PerWU_CabinPre_Value, sw-syscond=1}
              IN_VeTHMR_b_RdyForShtDwn_Value: accessed-variable=VeTHMR_b_RdyForShtDwn.Value, variation-point={short-label=vpIN_VeTHMR_b_RdyForShtDwn_Value, sw-syscond=1}
              IN_VeTIMR_e_RacePrep_Value: accessed-variable=VeTIMR_e_RacePrep.Value, variation-point={short-label=vpIN_VeTIMR_e_RacePrep_Value, sw-syscond=1}
              IN_VeTPCR_b_RacePrepAmbCheck_Value: accessed-variable=VeTPCR_b_RacePrepAmbCheck.Value, variation-point={short-label=vpIN_VeTPCR_b_RacePrepAmbCheck_Value, sw-syscond=1}
              IN_VeTPCR_b_RacePrepEVSysStatus_Value: accessed-variable=VeTPCR_b_RacePrepEVSysStatus.Value, variation-point={short-label=vpIN_VeTPCR_b_RacePrepEVSysStatus_Value, sw-syscond=1}
          data-send-points:
            78 x access:
              OUT_VeSCPR_K_Next_Climate_Time_Hr_Value: accessed-variable=VeSCPR_K_Next_Climate_Time_Hr.Value
              OUT_VeSCPR_K_Sch1_Start_Time_Hr_Sts_Value: accessed-variable=VeSCPR_K_Sch1_Start_Time_Hr_Sts.Value
              OUT_VeSCPR_K_Sch1_Start_Time_Min_Sts_Value: accessed-variable=VeSCPR_K_Sch1_Start_Time_Min_Sts.Value
              OUT_VeSCPR_K_Sch1_End_Time_Hr_Sts_Value: accessed-variable=VeSCPR_K_Sch1_End_Time_Hr_Sts.Value
              OUT_VeSCPR_K_Sch1_End_Time_Min_Sts_Value: accessed-variable=VeSCPR_K_Sch1_End_Time_Min_Sts.Value
              OUT_VeSCPR_K_Sch1_Day_Sts_Value: accessed-variable=VeSCPR_K_Sch1_Day_Sts.Value
              OUT_VeSCPR_b_Sch1_Confirmed_Value: accessed-variable=VeSCPR_b_Sch1_Confirmed.Value
              OUT_VeSCPR_b_Sch1_ChargeUntilFull_Sts_Value: accessed-variable=VeSCPR_b_Sch1_ChargeUntilFull_Sts.Value
              OUT_VeSCPR_K_Sch2_Start_Time_Hr_Sts_Value: accessed-variable=VeSCPR_K_Sch2_Start_Time_Hr_Sts.Value
              OUT_VeSCPR_K_Next_Climate_Time_Min_Value: accessed-variable=VeSCPR_K_Next_Climate_Time_Min.Value
              OUT_VeSCPR_K_Sch2_Start_Time_Min_Sts_Value: accessed-variable=VeSCPR_K_Sch2_Start_Time_Min_Sts.Value
              OUT_VeSCPR_K_Sch2_End_Time_Hr_Sts_Value: accessed-variable=VeSCPR_K_Sch2_End_Time_Hr_Sts.Value
              OUT_VeSCPR_K_Sch2_End_Time_Min_Sts_Value: accessed-variable=VeSCPR_K_Sch2_End_Time_Min_Sts.Value
              OUT_VeSCPR_K_Sch2_Day_Sts_Value: accessed-variable=VeSCPR_K_Sch2_Day_Sts.Value
              OUT_VeSCPR_b_Sch2_Confirmed_Value: accessed-variable=VeSCPR_b_Sch2_Confirmed.Value
              OUT_VeSCPR_b_Sch2_ChargeUntilFull_Sts_Value: accessed-variable=VeSCPR_b_Sch2_ChargeUntilFull_Sts.Value
              OUT_VeSCPR_K_Sch3_DepHrSts_Value: accessed-variable=VeSCPR_K_Sch3_DepHrSts.Value
              OUT_VeSCPR_K_Sch3_DepMinSts_Value: accessed-variable=VeSCPR_K_Sch3_DepMinSts.Value
              OUT_VeSCPR_e_Sch3_AllowSts_Value: accessed-variable=VeSCPR_e_Sch3_AllowSts.Value
              OUT_VeSCPR_T_Sch3_DepTempSts_Value: accessed-variable=VeSCPR_T_Sch3_DepTempSts.Value
              OUT_VeSCPR_K_Next_Climate_Day_Value: accessed-variable=VeSCPR_K_Next_Climate_Day.Value
              OUT_VeSCPR_K_Sch3_DaySts_Value: accessed-variable=VeSCPR_K_Sch3_DaySts.Value
              OUT_VeSCPR_b_Sch3_EnblSts_Value: accessed-variable=VeSCPR_b_Sch3_EnblSts.Value
              OUT_VeSCPR_K_Sch4_DepHrSts_Value: accessed-variable=VeSCPR_K_Sch4_DepHrSts.Value
              OUT_VeSCPR_K_Sch4_DepMinSts_Value: accessed-variable=VeSCPR_K_Sch4_DepMinSts.Value
              OUT_VeSCPR_e_Sch4_AllowSts_Value: accessed-variable=VeSCPR_e_Sch4_AllowSts.Value
              OUT_VeSCPR_T_Sch4_DepTempSts_Value: accessed-variable=VeSCPR_T_Sch4_DepTempSts.Value
              OUT_VeSCPR_K_Sch4_DaySts_Value: accessed-variable=VeSCPR_K_Sch4_DaySts.Value
              OUT_VeSCPR_b_Sch4_EnblSts_Value: accessed-variable=VeSCPR_b_Sch4_EnblSts.Value
              OUT_VeSCPR_T_CabinTempSetPt_Value: accessed-variable=VeSCPR_T_CabinTempSetPt.Value
              OUT_VeSCPR_K_Next_SchStart_Time_Hr_Value: accessed-variable=VeSCPR_K_Next_SchStart_Time_Hr.Value
              OUT_VeSCPR_K_Next_SchStart_Time_Min_Value: accessed-variable=VeSCPR_K_Next_SchStart_Time_Min.Value
              OUT_VeSCPR_K_Next_SchEnd_Time_Hr_Value: accessed-variable=VeSCPR_K_Next_SchEnd_Time_Hr.Value
              OUT_VeSCPR_K_Next_SchEnd_Time_Min_Value: accessed-variable=VeSCPR_K_Next_SchEnd_Time_Min.Value
              OUT_VeSCPR_K_Next_Schedule_StartDay_Value: accessed-variable=VeSCPR_K_Next_Schedule_StartDay.Value
              OUT_VeSCPR_K_Next_Schedule_EndDay_Value: accessed-variable=VeSCPR_K_Next_Schedule_EndDay.Value
              OUT_VeSCPR_t_TimeToDeparture_Value: accessed-variable=VeSCPR_t_TimeToDeparture.Value
              OUT_VeSCPR_e_SchCP_Allow_Value: accessed-variable=VeSCPR_e_SchCP_Allow.Value
              OUT_VeSCPR_t_SchChrg_WUTime_Value: accessed-variable=VeSCPR_t_SchChrg_WUTime.Value
              OUT_VeSCPR_b_ChargeReq_Value: accessed-variable=VeSCPR_b_ChargeReq.Value
              OUT_VeSCPR_e_CPIM_Icon1_Cmd_Value: accessed-variable=VeSCPR_e_CPIM_Icon1_Cmd.Value
              OUT_VeSCPR_e_CPIM_Icon2_Cmd_Value: accessed-variable=VeSCPR_e_CPIM_Icon2_Cmd.Value
              OUT_VeSCPR_Pct_Est_SOC_Value: accessed-variable=VeSCPR_Pct_Est_SOC.Value
              OUT_VeSCPR_b_NoChrgSchEnbl_Value: accessed-variable=VeSCPR_b_NoChrgSchEnbl.Value
              OUT_VeSCPR_b_ButtonActive_Door_Value: accessed-variable=VeSCPR_b_ButtonActive_Door.Value
              OUT_VeSCPR_b_Sch1_Batt_CabinPriority_Sts_Value: accessed-variable=VeSCPR_b_Sch1_Batt_CabinPriority_Sts.Value
              OUT_VeSCPR_b_Sch1_Do_Not_Repeat_Sts_Value: accessed-variable=VeSCPR_b_Sch1_Do_Not_Repeat_Sts.Value
              OUT_VeSCPR_e_Sch1_Type_Sts_Value: accessed-variable=VeSCPR_e_Sch1_Type_Sts.Value
              OUT_VeSCPR_b_Sch2_Batt_CabinPriority_Sts_Value: accessed-variable=VeSCPR_b_Sch2_Batt_CabinPriority_Sts.Value
              OUT_VeSCPR_b_Sch2_Do_Not_Repeat_Sts_Value: accessed-variable=VeSCPR_b_Sch2_Do_Not_Repeat_Sts.Value
              OUT_VeSCPR_e_Sch2_Type_Sts_Value: accessed-variable=VeSCPR_e_Sch2_Type_Sts.Value
              OUT_VeSCPR_b_Sch3_Batt_CabinPriority_Sts_Value: accessed-variable=VeSCPR_b_Sch3_Batt_CabinPriority_Sts.Value
              OUT_VeSCPR_b_Sch3_ChargeUntilFull_Sts_Value: accessed-variable=VeSCPR_b_Sch3_ChargeUntilFull_Sts.Value
              OUT_VeSCPR_b_Sch3_Do_Not_Repeat_Sts_Value: accessed-variable=VeSCPR_b_Sch3_Do_Not_Repeat_Sts.Value
              OUT_VeSCPR_K_Sch3_End_Time_Hr_Sts_Value: accessed-variable=VeSCPR_K_Sch3_End_Time_Hr_Sts.Value
              OUT_VeSCPR_K_Sch3_End_Time_Min_Sts_Value: accessed-variable=VeSCPR_K_Sch3_End_Time_Min_Sts.Value
              OUT_VeSCPR_b_Sch3_Confirmed_Value: accessed-variable=VeSCPR_b_Sch3_Confirmed.Value
              OUT_VeSCPR_K_Sch3_Day_Sts_Value: accessed-variable=VeSCPR_K_Sch3_Day_Sts.Value
              OUT_VeSCPR_e_Sch3_Type_Sts_Value: accessed-variable=VeSCPR_e_Sch3_Type_Sts.Value
              OUT_VeSCPR_K_Sch3_Start_Time_Hr_Sts_Value: accessed-variable=VeSCPR_K_Sch3_Start_Time_Hr_Sts.Value
              OUT_VeSCPR_K_Sch3_Start_Time_Min_Sts_Value: accessed-variable=VeSCPR_K_Sch3_Start_Time_Min_Sts.Value
              OUT_VeSCPR_b_BattCabinPriority_Value: accessed-variable=VeSCPR_b_BattCabinPriority.Value
              OUT_VeSCPR_b_SchChrg_OktoCharge_Value: accessed-variable=VeSCPR_b_SchChrg_OktoCharge.Value
              OUT_VeSCPR_e_InitStatus_Value: accessed-variable=VeSCPR_e_InitStatus.Value
              OUT_VeSCPR_b_FOTASchCnflct_Value: accessed-variable=VeSCPR_b_FOTASchCnflct.Value
              OUT_VeSCPR_Pct_Sch1_ImmedSOC_Trgt_Sts_Value: accessed-variable=VeSCPR_Pct_Sch1_ImmedSOC_Trgt_Sts.Value
              OUT_VeSCPR_Pct_Sch1_ExtSOC_Trgt_Sts_Value: accessed-variable=VeSCPR_Pct_Sch1_ExtSOC_Trgt_Sts.Value
              OUT_VeSCPR_e_Sch1_ChrgSchType_Sts_Value: accessed-variable=VeSCPR_e_Sch1_ChrgSchType_Sts.Value
              OUT_VeSCPR_Pct_Sch2_ImmedSOC_Trgt_Sts_Value: accessed-variable=VeSCPR_Pct_Sch2_ImmedSOC_Trgt_Sts.Value
              OUT_VeSCPR_Pct_Sch2_ExtSOC_Trgt_Sts_Value: accessed-variable=VeSCPR_Pct_Sch2_ExtSOC_Trgt_Sts.Value
              OUT_VeSCPR_e_Sch2_ChrgSchType_Sts_Value: accessed-variable=VeSCPR_e_Sch2_ChrgSchType_Sts.Value
              OUT_VeSCPR_e_CoopChrgStatus_Value: accessed-variable=VeSCPR_e_CoopChrgStatus.Value
              OUT_VeSCPR_e_Next_ChrgSchType_Value: accessed-variable=VeSCPR_e_Next_ChrgSchType.Value
              OUT_VeSCPR_K_Ext_Next_StopTime_Day_Value: accessed-variable=VeSCPR_K_Ext_Next_StopTime_Day.Value
              OUT_VeSCPR_K_Ext_Next_StopTime_Hr_Value: accessed-variable=VeSCPR_K_Ext_Next_StopTime_Hr.Value
              OUT_VeSCPR_K_Ext_Next_StopTime_Min_Value: accessed-variable=VeSCPR_K_Ext_Next_StopTime_Min.Value
              OUT_VeSCPR_Pct_Ext_Next_ImmedSOC_Trgt_Value: accessed-variable=VeSCPR_Pct_Ext_Next_ImmedSOC_Trgt.Value
              OUT_VeSCPR_Pct_Ext_Next_ExtSOC_Trgt_Value: accessed-variable=VeSCPR_Pct_Ext_Next_ExtSOC_Trgt.Value
        SCPR_PwrOff: variation-point={short-label=vpSCPR_PwrOff, sw-syscond=1}
          data-send-points:
            87 x access:
              OUT_FeSCPR_y_Sch1CH_Day_FeSCPR_y_Sch1CH_Day: accessed-variable=FeSCPR_y_Sch1CH_Day.FeSCPR_y_Sch1CH_Day, variation-point={short-label=vpOUT_FeSCPR_y_Sch1CH_Day_FeSCPR_y_Sch1CH_Day, sw-syscond=1}
              OUT_FeSCPR_b_Sch1CP_DNR_FeSCPR_b_Sch1CP_DNR: accessed-variable=FeSCPR_b_Sch1CP_DNR.FeSCPR_b_Sch1CP_DNR, variation-point={short-label=vpOUT_FeSCPR_b_Sch1CP_DNR_FeSCPR_b_Sch1CP_DNR, sw-syscond=1}
              OUT_FeSCPR_y_Sch1CP_Day_FeSCPR_y_Sch1CP_Day: accessed-variable=FeSCPR_y_Sch1CP_Day.FeSCPR_y_Sch1CP_Day, variation-point={short-label=vpOUT_FeSCPR_y_Sch1CP_Day_FeSCPR_y_Sch1CP_Day, sw-syscond=1}
              OUT_FeSCPR_y_Sch2CH_Day_FeSCPR_y_Sch2CH_Day: accessed-variable=FeSCPR_y_Sch2CH_Day.FeSCPR_y_Sch2CH_Day, variation-point={short-label=vpOUT_FeSCPR_y_Sch2CH_Day_FeSCPR_y_Sch2CH_Day, sw-syscond=1}
              OUT_FeSCPR_b_Sch2CH_Enbl_FeSCPR_b_Sch2CH_Enbl: accessed-variable=FeSCPR_b_Sch2CH_Enbl.FeSCPR_b_Sch2CH_Enbl, variation-point={short-label=vpOUT_FeSCPR_b_Sch2CH_Enbl_FeSCPR_b_Sch2CH_Enbl, sw-syscond=1}
              OUT_FeSCPR_b_Sch2CH_ChrgUntFl_FeSCPR_b_Sch2CH_ChrgUntFl: accessed-variable=FeSCPR_b_Sch2CH_ChrgUntFl.FeSCPR_b_Sch2CH_ChrgUntFl, variation-point={short-label=vpOUT_FeSCPR_b_Sch2CH_ChrgUntFl_FeSCPR_b_Sch2CH_ChrgUntFl, sw-syscond=1}
              OUT_FeSCPR_b_Sch2CH_DNR_FeSCPR_b_Sch2CH_DNR: accessed-variable=FeSCPR_b_Sch2CH_DNR.FeSCPR_b_Sch2CH_DNR, variation-point={short-label=vpOUT_FeSCPR_b_Sch2CH_DNR_FeSCPR_b_Sch2CH_DNR, sw-syscond=1}
              OUT_FeSCPR_e_Sch2CH_StrtHr_FeSCPR_e_Sch2CH_StrtHr: accessed-variable=FeSCPR_e_Sch2CH_StrtHr.FeSCPR_e_Sch2CH_StrtHr, variation-point={short-label=vpOUT_FeSCPR_e_Sch2CH_StrtHr_FeSCPR_e_Sch2CH_StrtHr, sw-syscond=1}
              OUT_FeSCPR_e_Sch2CH_StrtMin_FeSCPR_e_Sch2CH_StrtMin: accessed-variable=FeSCPR_e_Sch2CH_StrtMin.FeSCPR_e_Sch2CH_StrtMin, variation-point={short-label=vpOUT_FeSCPR_e_Sch2CH_StrtMin_FeSCPR_e_Sch2CH_StrtMin, sw-syscond=1}
              OUT_FeSCPR_e_Sch2CH_EndHr_FeSCPR_e_Sch2CH_EndHr: accessed-variable=FeSCPR_e_Sch2CH_EndHr.FeSCPR_e_Sch2CH_EndHr, variation-point={short-label=vpOUT_FeSCPR_e_Sch2CH_EndHr_FeSCPR_e_Sch2CH_EndHr, sw-syscond=1}
              OUT_FeSCPR_e_Sch2CH_EndMin_FeSCPR_e_Sch2CH_EndMin: accessed-variable=FeSCPR_e_Sch2CH_EndMin.FeSCPR_e_Sch2CH_EndMin, variation-point={short-label=vpOUT_FeSCPR_e_Sch2CH_EndMin_FeSCPR_e_Sch2CH_EndMin, sw-syscond=1}
              OUT_FeSCPR_b_Sch1CH_Enbl_FeSCPR_b_Sch1CH_Enbl: accessed-variable=FeSCPR_b_Sch1CH_Enbl.FeSCPR_b_Sch1CH_Enbl, variation-point={short-label=vpOUT_FeSCPR_b_Sch1CH_Enbl_FeSCPR_b_Sch1CH_Enbl, sw-syscond=1}
              OUT_FeSCPR_b_Sch2CP_Enbl_FeSCPR_b_Sch2CP_Enbl: accessed-variable=FeSCPR_b_Sch2CP_Enbl.FeSCPR_b_Sch2CP_Enbl, variation-point={short-label=vpOUT_FeSCPR_b_Sch2CP_Enbl_FeSCPR_b_Sch2CP_Enbl, sw-syscond=1}
              OUT_FeSCPR_T_Sch2CP_DepTemp_FeSCPR_T_Sch2CP_DepTemp: accessed-variable=FeSCPR_T_Sch2CP_DepTemp.FeSCPR_T_Sch2CP_DepTemp, variation-point={short-label=vpOUT_FeSCPR_T_Sch2CP_DepTemp_FeSCPR_T_Sch2CP_DepTemp, sw-syscond=1}
              OUT_FeSCPR_e_Sch2CP_Allow_FeSCPR_e_Sch2CP_Allow: accessed-variable=FeSCPR_e_Sch2CP_Allow.FeSCPR_e_Sch2CP_Allow, variation-point={short-label=vpOUT_FeSCPR_e_Sch2CP_Allow_FeSCPR_e_Sch2CP_Allow, sw-syscond=1}
              OUT_FeSCPR_e_Sch2CP_DepHr_FeSCPR_e_Sch2CP_DepHr: accessed-variable=FeSCPR_e_Sch2CP_DepHr.FeSCPR_e_Sch2CP_DepHr, variation-point={short-label=vpOUT_FeSCPR_e_Sch2CP_DepHr_FeSCPR_e_Sch2CP_DepHr, sw-syscond=1}
              OUT_FeSCPR_e_Sch2CP_DepMin_FeSCPR_e_Sch2CP_DepMin: accessed-variable=FeSCPR_e_Sch2CP_DepMin.FeSCPR_e_Sch2CP_DepMin, variation-point={short-label=vpOUT_FeSCPR_e_Sch2CP_DepMin_FeSCPR_e_Sch2CP_DepMin, sw-syscond=1}
              OUT_FeSCPR_b_Sch2CP_DNR_FeSCPR_b_Sch2CP_DNR: accessed-variable=FeSCPR_b_Sch2CP_DNR.FeSCPR_b_Sch2CP_DNR, variation-point={short-label=vpOUT_FeSCPR_b_Sch2CP_DNR_FeSCPR_b_Sch2CP_DNR, sw-syscond=1}
              OUT_FeSCPR_y_Sch2CP_Day_FeSCPR_y_Sch2CP_Day: accessed-variable=FeSCPR_y_Sch2CP_Day.FeSCPR_y_Sch2CP_Day, variation-point={short-label=vpOUT_FeSCPR_y_Sch2CP_Day_FeSCPR_y_Sch2CP_Day, sw-syscond=1}
              OUT_FeSCPR_e_Sch1CH_StrtHr_FeSCPR_e_Sch1CH_StrtHr: accessed-variable=FeSCPR_e_Sch1CH_StrtHr.FeSCPR_e_Sch1CH_StrtHr, variation-point={short-label=vpOUT_FeSCPR_e_Sch1CH_StrtHr_FeSCPR_e_Sch1CH_StrtHr, sw-syscond=1}
              OUT_FeSCPR_e_Sch1CH_StrtMin_FeSCPR_e_Sch1CH_StrtMin: accessed-variable=FeSCPR_e_Sch1CH_StrtMin.FeSCPR_e_Sch1CH_StrtMin, variation-point={short-label=vpOUT_FeSCPR_e_Sch1CH_StrtMin_FeSCPR_e_Sch1CH_StrtMin, sw-syscond=1}
              OUT_FeSCPR_e_Sch1CH_EndHr_FeSCPR_e_Sch1CH_EndHr: accessed-variable=FeSCPR_e_Sch1CH_EndHr.FeSCPR_e_Sch1CH_EndHr, variation-point={short-label=vpOUT_FeSCPR_e_Sch1CH_EndHr_FeSCPR_e_Sch1CH_EndHr, sw-syscond=1}
              OUT_FeSCPR_b_Sch1CH_ChrgUntFl_FeSCPR_b_Sch1CH_ChrgUntFl: accessed-variable=FeSCPR_b_Sch1CH_ChrgUntFl.FeSCPR_b_Sch1CH_ChrgUntFl, variation-point={short-label=vpOUT_FeSCPR_b_Sch1CH_ChrgUntFl_FeSCPR_b_Sch1CH_ChrgUntFl, sw-syscond=1}
              OUT_FeSCPR_e_Sch1CH_EndMin_FeSCPR_e_Sch1CH_EndMin: accessed-variable=FeSCPR_e_Sch1CH_EndMin.FeSCPR_e_Sch1CH_EndMin, variation-point={short-label=vpOUT_FeSCPR_e_Sch1CH_EndMin_FeSCPR_e_Sch1CH_EndMin, sw-syscond=1}
              OUT_NeSCPR_e_NxtSchCP_StrtMin_NeSCPR_e_NxtSchCP_StrtMin: accessed-variable=NeSCPR_e_NxtSchCP_StrtMin.NeSCPR_e_NxtSchCP_StrtMin, variation-point={short-label=vpOUT_NeSCPR_e_NxtSchCP_StrtMin_NeSCPR_e_NxtSchCP_StrtMin, sw-syscond=1}
              OUT_NeSCPR_k_CabinTempSetPoint_NeSCPR_k_CabinTempSetPoint: accessed-variable=NeSCPR_k_CabinTempSetPoint.NeSCPR_k_CabinTempSetPoint, variation-point={short-label=vpOUT_NeSCPR_k_CabinTempSetPoint_NeSCPR_k_CabinTempSetPoint, sw-syscond=1}
              OUT_NeSCPR_e_NxtSchCP_Day_NeSCPR_e_NxtSchCP_Day: accessed-variable=NeSCPR_e_NxtSchCP_Day.NeSCPR_e_NxtSchCP_Day, variation-point={short-label=vpOUT_NeSCPR_e_NxtSchCP_Day_NeSCPR_e_NxtSchCP_Day, sw-syscond=1}
              OUT_NeSCPR_e_NxtSchCP_StrtHr_NeSCPR_e_NxtSchCP_StrtHr: accessed-variable=NeSCPR_e_NxtSchCP_StrtHr.NeSCPR_e_NxtSchCP_StrtHr, variation-point={short-label=vpOUT_NeSCPR_e_NxtSchCP_StrtHr_NeSCPR_e_NxtSchCP_StrtHr, sw-syscond=1}
              OUT_NeSCPR_e_NxtSchCH_StrtHr_NeSCPR_e_NxtSchCH_StrtHr: accessed-variable=NeSCPR_e_NxtSchCH_StrtHr.NeSCPR_e_NxtSchCH_StrtHr, variation-point={short-label=vpOUT_NeSCPR_e_NxtSchCH_StrtHr_NeSCPR_e_NxtSchCH_StrtHr, sw-syscond=1}
              OUT_NeSCPR_e_NxtSchCH_StrtMin_NeSCPR_e_NxtSchCH_StrtMin: accessed-variable=NeSCPR_e_NxtSchCH_StrtMin.NeSCPR_e_NxtSchCH_StrtMin, variation-point={short-label=vpOUT_NeSCPR_e_NxtSchCH_StrtMin_NeSCPR_e_NxtSchCH_StrtMin, sw-syscond=1}
              OUT_NeSCPR_e_NxtSchCH_StrtDay_NeSCPR_e_NxtSchCH_StrtDay: accessed-variable=NeSCPR_e_NxtSchCH_StrtDay.NeSCPR_e_NxtSchCH_StrtDay, variation-point={short-label=vpOUT_NeSCPR_e_NxtSchCH_StrtDay_NeSCPR_e_NxtSchCH_StrtDay, sw-syscond=1}
              OUT_NeSCPR_e_NxtSchCH_EndHr_NeSCPR_e_NxtSchCH_EndHr: accessed-variable=NeSCPR_e_NxtSchCH_EndHr.NeSCPR_e_NxtSchCH_EndHr, variation-point={short-label=vpOUT_NeSCPR_e_NxtSchCH_EndHr_NeSCPR_e_NxtSchCH_EndHr, sw-syscond=1}
              OUT_NeSCPR_e_NxtSchCH_EndMin_NeSCPR_e_NxtSchCH_EndMin: accessed-variable=NeSCPR_e_NxtSchCH_EndMin.NeSCPR_e_NxtSchCH_EndMin, variation-point={short-label=vpOUT_NeSCPR_e_NxtSchCH_EndMin_NeSCPR_e_NxtSchCH_EndMin, sw-syscond=1}
              OUT_FeSCPR_b_Sch1CH_DNR_FeSCPR_b_Sch1CH_DNR: accessed-variable=FeSCPR_b_Sch1CH_DNR.FeSCPR_b_Sch1CH_DNR, variation-point={short-label=vpOUT_FeSCPR_b_Sch1CH_DNR_FeSCPR_b_Sch1CH_DNR, sw-syscond=1}
              OUT_NeSCPR_e_NxtSchCH_EndDay_NeSCPR_e_NxtSchCH_EndDay: accessed-variable=NeSCPR_e_NxtSchCH_EndDay.NeSCPR_e_NxtSchCH_EndDay, variation-point={short-label=vpOUT_NeSCPR_e_NxtSchCH_EndDay_NeSCPR_e_NxtSchCH_EndDay, sw-syscond=1}
              OUT_FeSCPR_b_Sch1CP_Enbl_FeSCPR_b_Sch1CP_Enbl: accessed-variable=FeSCPR_b_Sch1CP_Enbl.FeSCPR_b_Sch1CP_Enbl, variation-point={short-label=vpOUT_FeSCPR_b_Sch1CP_Enbl_FeSCPR_b_Sch1CP_Enbl, sw-syscond=1}
              OUT_FeSCPR_T_Sch1CP_DepTemp_FeSCPR_T_Sch1CP_DepTemp: accessed-variable=FeSCPR_T_Sch1CP_DepTemp.FeSCPR_T_Sch1CP_DepTemp, variation-point={short-label=vpOUT_FeSCPR_T_Sch1CP_DepTemp_FeSCPR_T_Sch1CP_DepTemp, sw-syscond=1}
              OUT_FeSCPR_e_Sch1CP_Allow_FeSCPR_e_Sch1CP_Allow: accessed-variable=FeSCPR_e_Sch1CP_Allow.FeSCPR_e_Sch1CP_Allow, variation-point={short-label=vpOUT_FeSCPR_e_Sch1CP_Allow_FeSCPR_e_Sch1CP_Allow, sw-syscond=1}
              OUT_FeSCPR_e_Sch1CP_DepHr_FeSCPR_e_Sch1CP_DepHr: accessed-variable=FeSCPR_e_Sch1CP_DepHr.FeSCPR_e_Sch1CP_DepHr, variation-point={short-label=vpOUT_FeSCPR_e_Sch1CP_DepHr_FeSCPR_e_Sch1CP_DepHr, sw-syscond=1}
              OUT_FeSCPR_e_Sch1CP_DepMin_FeSCPR_e_Sch1CP_DepMin: accessed-variable=FeSCPR_e_Sch1CP_DepMin.FeSCPR_e_Sch1CP_DepMin, variation-point={short-label=vpOUT_FeSCPR_e_Sch1CP_DepMin_FeSCPR_e_Sch1CP_DepMin, sw-syscond=1}
              OUT_FeSCPR_b_CancelActFOTA_FeSCPR_b_CancelActFOTA: accessed-variable=FeSCPR_b_CancelActFOTA.FeSCPR_b_CancelActFOTA, variation-point={short-label=vpOUT_FeSCPR_b_CancelActFOTA_FeSCPR_b_CancelActFOTA, sw-syscond=1}
              OUT_FeSCPR_b_ChrgNowLatch_FeSCPR_b_ChrgNowLatch: accessed-variable=FeSCPR_b_ChrgNowLatch.FeSCPR_b_ChrgNowLatch, variation-point={short-label=vpOUT_FeSCPR_b_ChrgNowLatch_FeSCPR_b_ChrgNowLatch, sw-syscond=1}
              OUT_FeSCPR_b_FOTA_Conflict_FeSCPR_b_FOTA_Conflict: accessed-variable=FeSCPR_b_FOTA_Conflict.FeSCPR_b_FOTA_Conflict, variation-point={short-label=vpOUT_FeSCPR_b_FOTA_Conflict_FeSCPR_b_FOTA_Conflict, sw-syscond=1}
              OUT_FeSCPR_e_FOTA_Install_Type_FeSCPR_e_FOTA_Install_Type: accessed-variable=FeSCPR_e_FOTA_Install_Type.FeSCPR_e_FOTA_Install_Type, variation-point={short-label=vpOUT_FeSCPR_e_FOTA_Install_Type_FeSCPR_e_FOTA_Install_Type, sw-syscond=1}
              OUT_FeSCPR_g_ChrgNowMaxTimetoPlugin_FeSCPR_g_ChrgNowMaxTimetoPlugin: accessed-variable=FeSCPR_g_ChrgNowMaxTimetoPlugin.FeSCPR_g_ChrgNowMaxTimetoPlugin, variation-point={short-label=vpOUT_FeSCPR_g_ChrgNowMaxTimetoPlugin_FeSCPR_g_ChrgNowMaxTimetoPlugin, sw-syscond=1}
              OUT_NeSCPR_Pct_SOCArb_NeSCPR_Pct_SOCArb: accessed-variable=NeSCPR_Pct_SOCArb.NeSCPR_Pct_SOCArb, variation-point={short-label=vpOUT_NeSCPR_Pct_SOCArb_NeSCPR_Pct_SOCArb, sw-syscond=1}
              OUT_NeSCPR_b_AllowCancel_NeSCPR_b_AllowCancel: accessed-variable=NeSCPR_b_AllowCancel.NeSCPR_b_AllowCancel, variation-point={short-label=vpOUT_NeSCPR_b_AllowCancel_NeSCPR_b_AllowCancel, sw-syscond=1}
              OUT_NeSCPR_b_CancSchedIsUF_NeSCPR_b_CancSchedIsUF: accessed-variable=NeSCPR_b_CancSchedIsUF.NeSCPR_b_CancSchedIsUF, variation-point={short-label=vpOUT_NeSCPR_b_CancSchedIsUF_NeSCPR_b_CancSchedIsUF, sw-syscond=1}
              OUT_NeSCPR_b_CancWindow_NeSCPR_b_CancWindow: accessed-variable=NeSCPR_b_CancWindow.NeSCPR_b_CancWindow, variation-point={short-label=vpOUT_NeSCPR_b_CancWindow_NeSCPR_b_CancWindow, sw-syscond=1}
              OUT_NeSCPR_b_ChrgComplete_NeSCPR_b_ChrgComplete: accessed-variable=NeSCPR_b_ChrgComplete.NeSCPR_b_ChrgComplete, variation-point={short-label=vpOUT_NeSCPR_b_ChrgComplete_NeSCPR_b_ChrgComplete, sw-syscond=1}
              OUT_NeSCPR_b_PluginLatchOverride_NeSCPR_b_PluginLatchOverride: accessed-variable=NeSCPR_b_PluginLatchOverride.NeSCPR_b_PluginLatchOverride, variation-point={short-label=vpOUT_NeSCPR_b_PluginLatchOverride_NeSCPR_b_PluginLatchOverride, sw-syscond=1}
              OUT_NeSCPR_b_RadioRqLstVldStt_NeSCPR_b_RadioRqLstVldStt: accessed-variable=NeSCPR_b_RadioRqLstVldStt.NeSCPR_b_RadioRqLstVldStt, variation-point={short-label=vpOUT_NeSCPR_b_RadioRqLstVldStt_NeSCPR_b_RadioRqLstVldStt, sw-syscond=1}
              OUT_NeSCPR_b_StopChrg_NeSCPR_b_StopChrg: accessed-variable=NeSCPR_b_StopChrg.NeSCPR_b_StopChrg, variation-point={short-label=vpOUT_NeSCPR_b_StopChrg_NeSCPR_b_StopChrg, sw-syscond=1}
              OUT_NeSCPR_b_xMinUF_NeSCPR_b_xMinUF: accessed-variable=NeSCPR_b_xMinUF.NeSCPR_b_xMinUF, variation-point={short-label=vpOUT_NeSCPR_b_xMinUF_NeSCPR_b_xMinUF, sw-syscond=1}
              OUT_NeSCPR_b_xMinUFCancel_NeSCPR_b_xMinUFCancel: accessed-variable=NeSCPR_b_xMinUFCancel.NeSCPR_b_xMinUFCancel, variation-point={short-label=vpOUT_NeSCPR_b_xMinUFCancel_NeSCPR_b_xMinUFCancel, sw-syscond=1}
              OUT_NeSCPR_e_CancStartIdxHold_NeSCPR_e_CancStartIdxHold: accessed-variable=NeSCPR_e_CancStartIdxHold.NeSCPR_e_CancStartIdxHold, variation-point={short-label=vpOUT_NeSCPR_e_CancStartIdxHold_NeSCPR_e_CancStartIdxHold, sw-syscond=1}
              OUT_NeSCPR_e_CancelStartIndx_NeSCPR_e_CancelStartIndx: accessed-variable=NeSCPR_e_CancelStartIndx.NeSCPR_e_CancelStartIndx, variation-point={short-label=vpOUT_NeSCPR_e_CancelStartIndx_NeSCPR_e_CancelStartIndx, sw-syscond=1}
              OUT_NeSCPR_e_EndIndexCanc_NeSCPR_e_EndIndexCanc: accessed-variable=NeSCPR_e_EndIndexCanc.NeSCPR_e_EndIndexCanc, variation-point={short-label=vpOUT_NeSCPR_e_EndIndexCanc_NeSCPR_e_EndIndexCanc, sw-syscond=1}
              OUT_NeSCPR_e_LastNowIndex_NeSCPR_e_LastNowIndex: accessed-variable=NeSCPR_e_LastNowIndex.NeSCPR_e_LastNowIndex, variation-point={short-label=vpOUT_NeSCPR_e_LastNowIndex_NeSCPR_e_LastNowIndex, sw-syscond=1}
              OUT_NeSCPR_g_DoNotRepeatValSch1_NeSCPR_g_DoNotRepeatValSch1: accessed-variable=NeSCPR_g_DoNotRepeatValSch1.NeSCPR_g_DoNotRepeatValSch1, variation-point={short-label=vpOUT_NeSCPR_g_DoNotRepeatValSch1_NeSCPR_g_DoNotRepeatValSch1, sw-syscond=1}
              OUT_NeSCPR_g_DoNotRepeatValSch2_NeSCPR_g_DoNotRepeatValSch2: accessed-variable=NeSCPR_g_DoNotRepeatValSch2.NeSCPR_g_DoNotRepeatValSch2, variation-point={short-label=vpOUT_NeSCPR_g_DoNotRepeatValSch2_NeSCPR_g_DoNotRepeatValSch2, sw-syscond=1}
              OUT_NeSCPR_g_Sch1CP_DNRvalue_NeSCPR_g_Sch1CP_DNRvalue: accessed-variable=NeSCPR_g_Sch1CP_DNRvalue.NeSCPR_g_Sch1CP_DNRvalue, variation-point={short-label=vpOUT_NeSCPR_g_Sch1CP_DNRvalue_NeSCPR_g_Sch1CP_DNRvalue, sw-syscond=1}
              OUT_NeSCPR_g_Sch2CP_DNRvalue_NeSCPR_g_Sch2CP_DNRvalue: accessed-variable=NeSCPR_g_Sch2CP_DNRvalue.NeSCPR_g_Sch2CP_DNRvalue, variation-point={short-label=vpOUT_NeSCPR_g_Sch2CP_DNRvalue_NeSCPR_g_Sch2CP_DNRvalue, sw-syscond=1}
              OUT_NeSCPR_k_CancGlEndTrack_NeSCPR_k_CancGlEndTrack: accessed-variable=NeSCPR_k_CancGlEndTrack.NeSCPR_k_CancGlEndTrack, variation-point={short-label=vpOUT_NeSCPR_k_CancGlEndTrack_NeSCPR_k_CancGlEndTrack, sw-syscond=1}
              OUT_NeSCPR_k_CancGlStartTrack_NeSCPR_k_CancGlStartTrack: accessed-variable=NeSCPR_k_CancGlStartTrack.NeSCPR_k_CancGlStartTrack, variation-point={short-label=vpOUT_NeSCPR_k_CancGlStartTrack_NeSCPR_k_CancGlStartTrack, sw-syscond=1}
              OUT_NeSCPR_k_CancOverlapTrack_NeSCPR_k_CancOverlapTrack: accessed-variable=NeSCPR_k_CancOverlapTrack.NeSCPR_k_CancOverlapTrack, variation-point={short-label=vpOUT_NeSCPR_k_CancOverlapTrack_NeSCPR_k_CancOverlapTrack, sw-syscond=1}
              OUT_NeSCPR_k_LastRTC_NeSCPR_k_LastRTC: accessed-variable=NeSCPR_k_LastRTC.NeSCPR_k_LastRTC, variation-point={short-label=vpOUT_NeSCPR_k_LastRTC_NeSCPR_k_LastRTC, sw-syscond=1}
              OUT_NeSCPR_k_LastSecond_NeSCPR_k_LastSecond: accessed-variable=NeSCPR_k_LastSecond.NeSCPR_k_LastSecond, variation-point={short-label=vpOUT_NeSCPR_k_LastSecond_NeSCPR_k_LastSecond, sw-syscond=1}
              OUT_NeSCPR_e_Sch1CoCH_StopHr_NeSCPR_e_Sch1CoCH_StopHr: accessed-variable=NeSCPR_e_Sch1CoCH_StopHr.NeSCPR_e_Sch1CoCH_StopHr, variation-point={short-label=vpOUT_NeSCPR_e_Sch1CoCH_StopHr_NeSCPR_e_Sch1CoCH_StopHr, sw-syscond=1}
              OUT_NeSCPR_e_Sch1CoCH_StopMin_NeSCPR_e_Sch1CoCH_StopMin: accessed-variable=NeSCPR_e_Sch1CoCH_StopMin.NeSCPR_e_Sch1CoCH_StopMin, variation-point={short-label=vpOUT_NeSCPR_e_Sch1CoCH_StopMin_NeSCPR_e_Sch1CoCH_StopMin, sw-syscond=1}
              OUT_NeSCPR_y_Sch1CoCH_Day_NeSCPR_y_Sch1CoCH_Day: accessed-variable=NeSCPR_y_Sch1CoCH_Day.NeSCPR_y_Sch1CoCH_Day, variation-point={short-label=vpOUT_NeSCPR_y_Sch1CoCH_Day_NeSCPR_y_Sch1CoCH_Day, sw-syscond=1}
              OUT_NeSCPR_b_Sch1CoCH_Enbl_NeSCPR_b_Sch1CoCH_Enbl: accessed-variable=NeSCPR_b_Sch1CoCH_Enbl.NeSCPR_b_Sch1CoCH_Enbl, variation-point={short-label=vpOUT_NeSCPR_b_Sch1CoCH_Enbl_NeSCPR_b_Sch1CoCH_Enbl, sw-syscond=1}
              OUT_NeSCPR_Pct_Sch1CoCH_ImmSOCtrgt_NeSCPR_Pct_Sch1CoCH_ImmSOCtrgt: accessed-variable=NeSCPR_Pct_Sch1CoCH_ImmSOCtrgt.NeSCPR_Pct_Sch1CoCH_ImmSOCtrgt, variation-point={short-label=vpOUT_NeSCPR_Pct_Sch1CoCH_ImmSOCtrgt_NeSCPR_Pct_Sch1CoCH_ImmSOCtrgt, sw-syscond=1}
              OUT_NeSCPR_Pct_Sch1CoCH_ExtSOCtrgt_NeSCPR_Pct_Sch1CoCH_ExtSOCtrgt: accessed-variable=NeSCPR_Pct_Sch1CoCH_ExtSOCtrgt.NeSCPR_Pct_Sch1CoCH_ExtSOCtrgt, variation-point={short-label=vpOUT_NeSCPR_Pct_Sch1CoCH_ExtSOCtrgt_NeSCPR_Pct_Sch1CoCH_ExtSOCtrgt, sw-syscond=1}
              OUT_NeSCPR_e_Sch1CH_SchType_NeSCPR_e_Sch1CH_SchType: accessed-variable=NeSCPR_e_Sch1CH_SchType.NeSCPR_e_Sch1CH_SchType, variation-point={short-label=vpOUT_NeSCPR_e_Sch1CH_SchType_NeSCPR_e_Sch1CH_SchType, sw-syscond=1}
              OUT_NeSCPR_e_Sch2CoCH_StopHr_NeSCPR_e_Sch2CoCH_StopHr: accessed-variable=NeSCPR_e_Sch2CoCH_StopHr.NeSCPR_e_Sch2CoCH_StopHr, variation-point={short-label=vpOUT_NeSCPR_e_Sch2CoCH_StopHr_NeSCPR_e_Sch2CoCH_StopHr, sw-syscond=1}
              OUT_NeSCPR_e_Sch2CoCH_StopMin_NeSCPR_e_Sch2CoCH_StopMin: accessed-variable=NeSCPR_e_Sch2CoCH_StopMin.NeSCPR_e_Sch2CoCH_StopMin, variation-point={short-label=vpOUT_NeSCPR_e_Sch2CoCH_StopMin_NeSCPR_e_Sch2CoCH_StopMin, sw-syscond=1}
              OUT_NeSCPR_y_Sch2CoCH_Day_NeSCPR_y_Sch2CoCH_Day: accessed-variable=NeSCPR_y_Sch2CoCH_Day.NeSCPR_y_Sch2CoCH_Day, variation-point={short-label=vpOUT_NeSCPR_y_Sch2CoCH_Day_NeSCPR_y_Sch2CoCH_Day, sw-syscond=1}
              OUT_NeSCPR_b_Sch2CoCH_Enbl_NeSCPR_b_Sch2CoCH_Enbl: accessed-variable=NeSCPR_b_Sch2CoCH_Enbl.NeSCPR_b_Sch2CoCH_Enbl, variation-point={short-label=vpOUT_NeSCPR_b_Sch2CoCH_Enbl_NeSCPR_b_Sch2CoCH_Enbl, sw-syscond=1}
              OUT_NeSCPR_Pct_Sch2CoCH_ImmSOCtrgt_NeSCPR_Pct_Sch2CoCH_ImmSOCtrgt: accessed-variable=NeSCPR_Pct_Sch2CoCH_ImmSOCtrgt.NeSCPR_Pct_Sch2CoCH_ImmSOCtrgt, variation-point={short-label=vpOUT_NeSCPR_Pct_Sch2CoCH_ImmSOCtrgt_NeSCPR_Pct_Sch2CoCH_ImmSOCtrgt, sw-syscond=1}
              OUT_NeSCPR_Pct_Sch2CoCH_ExtSOCtrgt_NeSCPR_Pct_Sch2CoCH_ExtSOCtrgt: accessed-variable=NeSCPR_Pct_Sch2CoCH_ExtSOCtrgt.NeSCPR_Pct_Sch2CoCH_ExtSOCtrgt, variation-point={short-label=vpOUT_NeSCPR_Pct_Sch2CoCH_ExtSOCtrgt_NeSCPR_Pct_Sch2CoCH_ExtSOCtrgt, sw-syscond=1}
              OUT_NeSCPR_e_Sch2CH_SchType_NeSCPR_e_Sch2CH_SchType: accessed-variable=NeSCPR_e_Sch2CH_SchType.NeSCPR_e_Sch2CH_SchType, variation-point={short-label=vpOUT_NeSCPR_e_Sch2CH_SchType_NeSCPR_e_Sch2CH_SchType, sw-syscond=1}
              OUT_NeSCPR_b_CoCh_VehLocation_NeSCPR_b_CoCh_VehLocation: accessed-variable=NeSCPR_b_CoCh_VehLocation.NeSCPR_b_CoCh_VehLocation, variation-point={short-label=vpOUT_NeSCPR_b_CoCh_VehLocation_NeSCPR_b_CoCh_VehLocation, sw-syscond=1}
              OUT_NeSCPR_b_CoCH_Sch1_DNR_NeSCPR_b_CoCH_Sch1_DNR: accessed-variable=NeSCPR_b_CoCH_Sch1_DNR.NeSCPR_b_CoCH_Sch1_DNR, variation-point={short-label=vpOUT_NeSCPR_b_CoCH_Sch1_DNR_NeSCPR_b_CoCH_Sch1_DNR, sw-syscond=1}
              OUT_NeSCPR_b_CoCH_Sch2_DNR_NeSCPR_b_CoCH_Sch2_DNR: accessed-variable=NeSCPR_b_CoCH_Sch2_DNR.NeSCPR_b_CoCH_Sch2_DNR, variation-point={short-label=vpOUT_NeSCPR_b_CoCH_Sch2_DNR_NeSCPR_b_CoCH_Sch2_DNR, sw-syscond=1}
              OUT_NeSCPR_g_Sch1CoCH_DNRvalue_NeSCPR_g_Sch1CoCH_DNRvalue: accessed-variable=NeSCPR_g_Sch1CoCH_DNRvalue.NeSCPR_g_Sch1CoCH_DNRvalue, variation-point={short-label=vpOUT_NeSCPR_g_Sch1CoCH_DNRvalue_NeSCPR_g_Sch1CoCH_DNRvalue, sw-syscond=1}
              OUT_NeSCPR_g_Sch2CoCH_DNRvalue_NeSCPR_g_Sch2CoCH_DNRvalue: accessed-variable=NeSCPR_g_Sch2CoCH_DNRvalue.NeSCPR_g_Sch2CoCH_DNRvalue, variation-point={short-label=vpOUT_NeSCPR_g_Sch2CoCH_DNRvalue_NeSCPR_g_Sch2CoCH_DNRvalue, sw-syscond=1}
        SCPR_PwrOn
          data-receive-point-by-arguments:
            87 x access:
              IN_FeSCPR_T_Sch1CP_DepTemp_Rx_FeSCPR_T_Sch1CP_DepTemp: accessed-variable=FeSCPR_T_Sch1CP_DepTemp_Rx.FeSCPR_T_Sch1CP_DepTemp, variation-point={short-label=vpIN_FeSCPR_T_Sch1CP_DepTemp_Rx_FeSCPR_T_Sch1CP_DepTemp, sw-syscond=1}
              IN_FeSCPR_T_Sch2CP_DepTemp_Rx_FeSCPR_T_Sch2CP_DepTemp: accessed-variable=FeSCPR_T_Sch2CP_DepTemp_Rx.FeSCPR_T_Sch2CP_DepTemp, variation-point={short-label=vpIN_FeSCPR_T_Sch2CP_DepTemp_Rx_FeSCPR_T_Sch2CP_DepTemp, sw-syscond=1}
              IN_FeSCPR_b_CancelActFOTA_Rx_FeSCPR_b_CancelActFOTA: accessed-variable=FeSCPR_b_CancelActFOTA_Rx.FeSCPR_b_CancelActFOTA, variation-point={short-label=vpIN_FeSCPR_b_CancelActFOTA_Rx_FeSCPR_b_CancelActFOTA, sw-syscond=1}
              IN_FeSCPR_b_ChrgNowLatch_Rx_FeSCPR_b_ChrgNowLatch: accessed-variable=FeSCPR_b_ChrgNowLatch_Rx.FeSCPR_b_ChrgNowLatch, variation-point={short-label=vpIN_FeSCPR_b_ChrgNowLatch_Rx_FeSCPR_b_ChrgNowLatch, sw-syscond=1}
              IN_FeSCPR_b_FOTA_Conflict_Rx_FeSCPR_b_FOTA_Conflict: accessed-variable=FeSCPR_b_FOTA_Conflict_Rx.FeSCPR_b_FOTA_Conflict, variation-point={short-label=vpIN_FeSCPR_b_FOTA_Conflict_Rx_FeSCPR_b_FOTA_Conflict, sw-syscond=1}
              IN_FeSCPR_b_Sch1CH_ChrgUntFl_Rx_FeSCPR_b_Sch1CH_ChrgUntFl: accessed-variable=FeSCPR_b_Sch1CH_ChrgUntFl_Rx.FeSCPR_b_Sch1CH_ChrgUntFl, variation-point={short-label=vpIN_FeSCPR_b_Sch1CH_ChrgUntFl_Rx_FeSCPR_b_Sch1CH_ChrgUntFl, sw-syscond=1}
              IN_FeSCPR_b_Sch1CH_DNR_Rx_FeSCPR_b_Sch1CH_DNR: accessed-variable=FeSCPR_b_Sch1CH_DNR_Rx.FeSCPR_b_Sch1CH_DNR, variation-point={short-label=vpIN_FeSCPR_b_Sch1CH_DNR_Rx_FeSCPR_b_Sch1CH_DNR, sw-syscond=1}
              IN_FeSCPR_b_Sch1CH_Enbl_Rx_FeSCPR_b_Sch1CH_Enbl: accessed-variable=FeSCPR_b_Sch1CH_Enbl_Rx.FeSCPR_b_Sch1CH_Enbl, variation-point={short-label=vpIN_FeSCPR_b_Sch1CH_Enbl_Rx_FeSCPR_b_Sch1CH_Enbl, sw-syscond=1}
              IN_FeSCPR_b_Sch1CP_DNR_Rx_FeSCPR_b_Sch1CP_DNR: accessed-variable=FeSCPR_b_Sch1CP_DNR_Rx.FeSCPR_b_Sch1CP_DNR, variation-point={short-label=vpIN_FeSCPR_b_Sch1CP_DNR_Rx_FeSCPR_b_Sch1CP_DNR, sw-syscond=1}
              IN_FeSCPR_b_Sch1CP_Enbl_Rx_FeSCPR_b_Sch1CP_Enbl: accessed-variable=FeSCPR_b_Sch1CP_Enbl_Rx.FeSCPR_b_Sch1CP_Enbl, variation-point={short-label=vpIN_FeSCPR_b_Sch1CP_Enbl_Rx_FeSCPR_b_Sch1CP_Enbl, sw-syscond=1}
              IN_FeSCPR_b_Sch2CH_ChrgUntFl_Rx_FeSCPR_b_Sch2CH_ChrgUntFl: accessed-variable=FeSCPR_b_Sch2CH_ChrgUntFl_Rx.FeSCPR_b_Sch2CH_ChrgUntFl, variation-point={short-label=vpIN_FeSCPR_b_Sch2CH_ChrgUntFl_Rx_FeSCPR_b_Sch2CH_ChrgUntFl, sw-syscond=1}
              IN_FeSCPR_b_Sch2CH_DNR_Rx_FeSCPR_b_Sch2CH_DNR: accessed-variable=FeSCPR_b_Sch2CH_DNR_Rx.FeSCPR_b_Sch2CH_DNR, variation-point={short-label=vpIN_FeSCPR_b_Sch2CH_DNR_Rx_FeSCPR_b_Sch2CH_DNR, sw-syscond=1}
              IN_FeSCPR_b_Sch2CH_Enbl_Rx_FeSCPR_b_Sch2CH_Enbl: accessed-variable=FeSCPR_b_Sch2CH_Enbl_Rx.FeSCPR_b_Sch2CH_Enbl, variation-point={short-label=vpIN_FeSCPR_b_Sch2CH_Enbl_Rx_FeSCPR_b_Sch2CH_Enbl, sw-syscond=1}
              IN_FeSCPR_b_Sch2CP_DNR_Rx_FeSCPR_b_Sch2CP_DNR: accessed-variable=FeSCPR_b_Sch2CP_DNR_Rx.FeSCPR_b_Sch2CP_DNR, variation-point={short-label=vpIN_FeSCPR_b_Sch2CP_DNR_Rx_FeSCPR_b_Sch2CP_DNR, sw-syscond=1}
              IN_FeSCPR_b_Sch2CP_Enbl_Rx_FeSCPR_b_Sch2CP_Enbl: accessed-variable=FeSCPR_b_Sch2CP_Enbl_Rx.FeSCPR_b_Sch2CP_Enbl, variation-point={short-label=vpIN_FeSCPR_b_Sch2CP_Enbl_Rx_FeSCPR_b_Sch2CP_Enbl, sw-syscond=1}
              IN_FeSCPR_e_FOTA_Install_Type_Rx_FeSCPR_e_FOTA_Install_Type: accessed-variable=FeSCPR_e_FOTA_Install_Type_Rx.FeSCPR_e_FOTA_Install_Type, variation-point={short-label=vpIN_FeSCPR_e_FOTA_Install_Type_Rx_FeSCPR_e_FOTA_Install_Type, sw-syscond=1}
              IN_FeSCPR_e_Sch1CH_EndHr_Rx_FeSCPR_e_Sch1CH_EndHr: accessed-variable=FeSCPR_e_Sch1CH_EndHr_Rx.FeSCPR_e_Sch1CH_EndHr, variation-point={short-label=vpIN_FeSCPR_e_Sch1CH_EndHr_Rx_FeSCPR_e_Sch1CH_EndHr, sw-syscond=1}
              IN_FeSCPR_e_Sch1CH_EndMin_Rx_FeSCPR_e_Sch1CH_EndMin: accessed-variable=FeSCPR_e_Sch1CH_EndMin_Rx.FeSCPR_e_Sch1CH_EndMin, variation-point={short-label=vpIN_FeSCPR_e_Sch1CH_EndMin_Rx_FeSCPR_e_Sch1CH_EndMin, sw-syscond=1}
              IN_FeSCPR_e_Sch1CH_StrtHr_Rx_FeSCPR_e_Sch1CH_StrtHr: accessed-variable=FeSCPR_e_Sch1CH_StrtHr_Rx.FeSCPR_e_Sch1CH_StrtHr, variation-point={short-label=vpIN_FeSCPR_e_Sch1CH_StrtHr_Rx_FeSCPR_e_Sch1CH_StrtHr, sw-syscond=1}
              IN_FeSCPR_e_Sch1CH_StrtMin_Rx_FeSCPR_e_Sch1CH_StrtMin: accessed-variable=FeSCPR_e_Sch1CH_StrtMin_Rx.FeSCPR_e_Sch1CH_StrtMin, variation-point={short-label=vpIN_FeSCPR_e_Sch1CH_StrtMin_Rx_FeSCPR_e_Sch1CH_StrtMin, sw-syscond=1}
              IN_FeSCPR_e_Sch1CP_Allow_Rx_FeSCPR_e_Sch1CP_Allow: accessed-variable=FeSCPR_e_Sch1CP_Allow_Rx.FeSCPR_e_Sch1CP_Allow, variation-point={short-label=vpIN_FeSCPR_e_Sch1CP_Allow_Rx_FeSCPR_e_Sch1CP_Allow, sw-syscond=1}
              IN_FeSCPR_e_Sch1CP_DepHr_Rx_FeSCPR_e_Sch1CP_DepHr: accessed-variable=FeSCPR_e_Sch1CP_DepHr_Rx.FeSCPR_e_Sch1CP_DepHr, variation-point={short-label=vpIN_FeSCPR_e_Sch1CP_DepHr_Rx_FeSCPR_e_Sch1CP_DepHr, sw-syscond=1}
              IN_FeSCPR_e_Sch1CP_DepMin_Rx_FeSCPR_e_Sch1CP_DepMin: accessed-variable=FeSCPR_e_Sch1CP_DepMin_Rx.FeSCPR_e_Sch1CP_DepMin, variation-point={short-label=vpIN_FeSCPR_e_Sch1CP_DepMin_Rx_FeSCPR_e_Sch1CP_DepMin, sw-syscond=1}
              IN_FeSCPR_e_Sch2CH_EndHr_Rx_FeSCPR_e_Sch2CH_EndHr: accessed-variable=FeSCPR_e_Sch2CH_EndHr_Rx.FeSCPR_e_Sch2CH_EndHr, variation-point={short-label=vpIN_FeSCPR_e_Sch2CH_EndHr_Rx_FeSCPR_e_Sch2CH_EndHr, sw-syscond=1}
              IN_FeSCPR_e_Sch2CH_EndMin_Rx_FeSCPR_e_Sch2CH_EndMin: accessed-variable=FeSCPR_e_Sch2CH_EndMin_Rx.FeSCPR_e_Sch2CH_EndMin, variation-point={short-label=vpIN_FeSCPR_e_Sch2CH_EndMin_Rx_FeSCPR_e_Sch2CH_EndMin, sw-syscond=1}
              IN_FeSCPR_e_Sch2CH_StrtHr_Rx_FeSCPR_e_Sch2CH_StrtHr: accessed-variable=FeSCPR_e_Sch2CH_StrtHr_Rx.FeSCPR_e_Sch2CH_StrtHr, variation-point={short-label=vpIN_FeSCPR_e_Sch2CH_StrtHr_Rx_FeSCPR_e_Sch2CH_StrtHr, sw-syscond=1}
              IN_FeSCPR_e_Sch2CH_StrtMin_Rx_FeSCPR_e_Sch2CH_StrtMin: accessed-variable=FeSCPR_e_Sch2CH_StrtMin_Rx.FeSCPR_e_Sch2CH_StrtMin, variation-point={short-label=vpIN_FeSCPR_e_Sch2CH_StrtMin_Rx_FeSCPR_e_Sch2CH_StrtMin, sw-syscond=1}
              IN_FeSCPR_e_Sch2CP_Allow_Rx_FeSCPR_e_Sch2CP_Allow: accessed-variable=FeSCPR_e_Sch2CP_Allow_Rx.FeSCPR_e_Sch2CP_Allow, variation-point={short-label=vpIN_FeSCPR_e_Sch2CP_Allow_Rx_FeSCPR_e_Sch2CP_Allow, sw-syscond=1}
              IN_FeSCPR_e_Sch2CP_DepHr_Rx_FeSCPR_e_Sch2CP_DepHr: accessed-variable=FeSCPR_e_Sch2CP_DepHr_Rx.FeSCPR_e_Sch2CP_DepHr, variation-point={short-label=vpIN_FeSCPR_e_Sch2CP_DepHr_Rx_FeSCPR_e_Sch2CP_DepHr, sw-syscond=1}
              IN_FeSCPR_e_Sch2CP_DepMin_Rx_FeSCPR_e_Sch2CP_DepMin: accessed-variable=FeSCPR_e_Sch2CP_DepMin_Rx.FeSCPR_e_Sch2CP_DepMin, variation-point={short-label=vpIN_FeSCPR_e_Sch2CP_DepMin_Rx_FeSCPR_e_Sch2CP_DepMin, sw-syscond=1}
              IN_FeSCPR_g_ChrgNowMaxTimetoPlugin_Rx_FeSCPR_g_ChrgNowMaxTimetoPlugin: accessed-variable=FeSCPR_g_ChrgNowMaxTimetoPlugin_Rx.FeSCPR_g_ChrgNowMaxTimetoPlugin, variation-point={short-label=vpIN_FeSCPR_g_ChrgNowMaxTimetoPlugin_Rx_FeSCPR_g_ChrgNowMaxTimetoPlugin, sw-syscond=1}
              IN_FeSCPR_y_Sch1CH_Day_Rx_FeSCPR_y_Sch1CH_Day: accessed-variable=FeSCPR_y_Sch1CH_Day_Rx.FeSCPR_y_Sch1CH_Day, variation-point={short-label=vpIN_FeSCPR_y_Sch1CH_Day_Rx_FeSCPR_y_Sch1CH_Day, sw-syscond=1}
              IN_FeSCPR_y_Sch1CP_Day_Rx_FeSCPR_y_Sch1CP_Day: accessed-variable=FeSCPR_y_Sch1CP_Day_Rx.FeSCPR_y_Sch1CP_Day, variation-point={short-label=vpIN_FeSCPR_y_Sch1CP_Day_Rx_FeSCPR_y_Sch1CP_Day, sw-syscond=1}
              IN_FeSCPR_y_Sch2CH_Day_Rx_FeSCPR_y_Sch2CH_Day: accessed-variable=FeSCPR_y_Sch2CH_Day_Rx.FeSCPR_y_Sch2CH_Day, variation-point={short-label=vpIN_FeSCPR_y_Sch2CH_Day_Rx_FeSCPR_y_Sch2CH_Day, sw-syscond=1}
              IN_FeSCPR_y_Sch2CP_Day_Rx_FeSCPR_y_Sch2CP_Day: accessed-variable=FeSCPR_y_Sch2CP_Day_Rx.FeSCPR_y_Sch2CP_Day, variation-point={short-label=vpIN_FeSCPR_y_Sch2CP_Day_Rx_FeSCPR_y_Sch2CP_Day, sw-syscond=1}
              IN_NeSCPR_Pct_SOCArb_Rx_NeSCPR_Pct_SOCArb: accessed-variable=NeSCPR_Pct_SOCArb_Rx.NeSCPR_Pct_SOCArb, variation-point={short-label=vpIN_NeSCPR_Pct_SOCArb_Rx_NeSCPR_Pct_SOCArb, sw-syscond=1}
              IN_NeSCPR_Pct_Sch1CoCH_ExtSOCtrgt_Rx_NeSCPR_Pct_Sch1CoCH_ExtSOCtrgt: accessed-variable=NeSCPR_Pct_Sch1CoCH_ExtSOCtrgt_Rx.NeSCPR_Pct_Sch1CoCH_ExtSOCtrgt, variation-point={short-label=vpIN_NeSCPR_Pct_Sch1CoCH_ExtSOCtrgt_Rx_NeSCPR_Pct_Sch1CoCH_ExtSOCtrgt, sw-syscond=1}
              IN_NeSCPR_Pct_Sch1CoCH_ImmSOCtrgt_Rx_NeSCPR_Pct_Sch1CoCH_ImmSOCtrgt: accessed-variable=NeSCPR_Pct_Sch1CoCH_ImmSOCtrgt_Rx.NeSCPR_Pct_Sch1CoCH_ImmSOCtrgt, variation-point={short-label=vpIN_NeSCPR_Pct_Sch1CoCH_ImmSOCtrgt_Rx_NeSCPR_Pct_Sch1CoCH_ImmSOCtrgt, sw-syscond=1}
              IN_NeSCPR_Pct_Sch2CoCH_ExtSOCtrgt_Rx_NeSCPR_Pct_Sch2CoCH_ExtSOCtrgt: accessed-variable=NeSCPR_Pct_Sch2CoCH_ExtSOCtrgt_Rx.NeSCPR_Pct_Sch2CoCH_ExtSOCtrgt, variation-point={short-label=vpIN_NeSCPR_Pct_Sch2CoCH_ExtSOCtrgt_Rx_NeSCPR_Pct_Sch2CoCH_ExtSOCtrgt, sw-syscond=1}
              IN_NeSCPR_Pct_Sch2CoCH_ImmSOCtrgt_Rx_NeSCPR_Pct_Sch2CoCH_ImmSOCtrgt: accessed-variable=NeSCPR_Pct_Sch2CoCH_ImmSOCtrgt_Rx.NeSCPR_Pct_Sch2CoCH_ImmSOCtrgt, variation-point={short-label=vpIN_NeSCPR_Pct_Sch2CoCH_ImmSOCtrgt_Rx_NeSCPR_Pct_Sch2CoCH_ImmSOCtrgt, sw-syscond=1}
              IN_NeSCPR_b_AllowCancel_Rx_NeSCPR_b_AllowCancel: accessed-variable=NeSCPR_b_AllowCancel_Rx.NeSCPR_b_AllowCancel, variation-point={short-label=vpIN_NeSCPR_b_AllowCancel_Rx_NeSCPR_b_AllowCancel, sw-syscond=1}
              IN_NeSCPR_b_CancSchedIsUF_Rx_NeSCPR_b_CancSchedIsUF: accessed-variable=NeSCPR_b_CancSchedIsUF_Rx.NeSCPR_b_CancSchedIsUF, variation-point={short-label=vpIN_NeSCPR_b_CancSchedIsUF_Rx_NeSCPR_b_CancSchedIsUF, sw-syscond=1}
              IN_NeSCPR_b_CancWindow_Rx_NeSCPR_b_CancWindow: accessed-variable=NeSCPR_b_CancWindow_Rx.NeSCPR_b_CancWindow, variation-point={short-label=vpIN_NeSCPR_b_CancWindow_Rx_NeSCPR_b_CancWindow, sw-syscond=1}
              IN_NeSCPR_b_ChrgComplete_Rx_NeSCPR_b_ChrgComplete: accessed-variable=NeSCPR_b_ChrgComplete_Rx.NeSCPR_b_ChrgComplete, variation-point={short-label=vpIN_NeSCPR_b_ChrgComplete_Rx_NeSCPR_b_ChrgComplete, sw-syscond=1}
              IN_NeSCPR_b_CoCH_Sch1_DNR_Rx_NeSCPR_b_CoCH_Sch1_DNR: accessed-variable=NeSCPR_b_CoCH_Sch1_DNR_Rx.NeSCPR_b_CoCH_Sch1_DNR, variation-point={short-label=vpIN_NeSCPR_b_CoCH_Sch1_DNR_Rx_NeSCPR_b_CoCH_Sch1_DNR, sw-syscond=1}
              IN_NeSCPR_b_CoCH_Sch2_DNR_Rx_NeSCPR_b_CoCH_Sch2_DNR: accessed-variable=NeSCPR_b_CoCH_Sch2_DNR_Rx.NeSCPR_b_CoCH_Sch2_DNR, variation-point={short-label=vpIN_NeSCPR_b_CoCH_Sch2_DNR_Rx_NeSCPR_b_CoCH_Sch2_DNR, sw-syscond=1}
              IN_NeSCPR_b_CoCh_VehLocation_Rx_NeSCPR_b_CoCh_VehLocation: accessed-variable=NeSCPR_b_CoCh_VehLocation_Rx.NeSCPR_b_CoCh_VehLocation, variation-point={short-label=vpIN_NeSCPR_b_CoCh_VehLocation_Rx_NeSCPR_b_CoCh_VehLocation, sw-syscond=1}
              IN_NeSCPR_b_PluginLatchOverride_Rx_NeSCPR_b_PluginLatchOverride: accessed-variable=NeSCPR_b_PluginLatchOverride_Rx.NeSCPR_b_PluginLatchOverride, variation-point={short-label=vpIN_NeSCPR_b_PluginLatchOverride_Rx_NeSCPR_b_PluginLatchOverride, sw-syscond=1}
              IN_NeSCPR_b_RadioRqLstVldStt_Rx_NeSCPR_b_RadioRqLstVldStt: accessed-variable=NeSCPR_b_RadioRqLstVldStt_Rx.NeSCPR_b_RadioRqLstVldStt, variation-point={short-label=vpIN_NeSCPR_b_RadioRqLstVldStt_Rx_NeSCPR_b_RadioRqLstVldStt, sw-syscond=1}
              IN_NeSCPR_b_Sch1CoCH_Enbl_Rx_NeSCPR_b_Sch1CoCH_Enbl: accessed-variable=NeSCPR_b_Sch1CoCH_Enbl_Rx.NeSCPR_b_Sch1CoCH_Enbl, variation-point={short-label=vpIN_NeSCPR_b_Sch1CoCH_Enbl_Rx_NeSCPR_b_Sch1CoCH_Enbl, sw-syscond=1}
              IN_NeSCPR_b_Sch2CoCH_Enbl_Rx_NeSCPR_b_Sch2CoCH_Enbl: accessed-variable=NeSCPR_b_Sch2CoCH_Enbl_Rx.NeSCPR_b_Sch2CoCH_Enbl, variation-point={short-label=vpIN_NeSCPR_b_Sch2CoCH_Enbl_Rx_NeSCPR_b_Sch2CoCH_Enbl, sw-syscond=1}
              IN_NeSCPR_b_StopChrg_Rx_NeSCPR_b_StopChrg: accessed-variable=NeSCPR_b_StopChrg_Rx.NeSCPR_b_StopChrg, variation-point={short-label=vpIN_NeSCPR_b_StopChrg_Rx_NeSCPR_b_StopChrg, sw-syscond=1}
              IN_NeSCPR_b_xMinUFCancel_Rx_NeSCPR_b_xMinUFCancel: accessed-variable=NeSCPR_b_xMinUFCancel_Rx.NeSCPR_b_xMinUFCancel, variation-point={short-label=vpIN_NeSCPR_b_xMinUFCancel_Rx_NeSCPR_b_xMinUFCancel, sw-syscond=1}
              IN_NeSCPR_b_xMinUF_Rx_NeSCPR_b_xMinUF: accessed-variable=NeSCPR_b_xMinUF_Rx.NeSCPR_b_xMinUF, variation-point={short-label=vpIN_NeSCPR_b_xMinUF_Rx_NeSCPR_b_xMinUF, sw-syscond=1}
              IN_NeSCPR_e_CancStartIdxHold_Rx_NeSCPR_e_CancStartIdxHold: accessed-variable=NeSCPR_e_CancStartIdxHold_Rx.NeSCPR_e_CancStartIdxHold, variation-point={short-label=vpIN_NeSCPR_e_CancStartIdxHold_Rx_NeSCPR_e_CancStartIdxHold, sw-syscond=1}
              IN_NeSCPR_e_CancelStartIndx_Rx_NeSCPR_e_CancelStartIndx: accessed-variable=NeSCPR_e_CancelStartIndx_Rx.NeSCPR_e_CancelStartIndx, variation-point={short-label=vpIN_NeSCPR_e_CancelStartIndx_Rx_NeSCPR_e_CancelStartIndx, sw-syscond=1}
              IN_NeSCPR_e_EndIndexCanc_Rx_NeSCPR_e_EndIndexCanc: accessed-variable=NeSCPR_e_EndIndexCanc_Rx.NeSCPR_e_EndIndexCanc, variation-point={short-label=vpIN_NeSCPR_e_EndIndexCanc_Rx_NeSCPR_e_EndIndexCanc, sw-syscond=1}
              IN_NeSCPR_e_LastNowIndex_Rx_NeSCPR_e_LastNowIndex: accessed-variable=NeSCPR_e_LastNowIndex_Rx.NeSCPR_e_LastNowIndex, variation-point={short-label=vpIN_NeSCPR_e_LastNowIndex_Rx_NeSCPR_e_LastNowIndex, sw-syscond=1}
              IN_NeSCPR_e_NxtSchCH_EndDay_Rx_NeSCPR_e_NxtSchCH_EndDay: accessed-variable=NeSCPR_e_NxtSchCH_EndDay_Rx.NeSCPR_e_NxtSchCH_EndDay, variation-point={short-label=vpIN_NeSCPR_e_NxtSchCH_EndDay_Rx_NeSCPR_e_NxtSchCH_EndDay, sw-syscond=1}
              IN_NeSCPR_e_NxtSchCH_EndHr_Rx_NeSCPR_e_NxtSchCH_EndHr: accessed-variable=NeSCPR_e_NxtSchCH_EndHr_Rx.NeSCPR_e_NxtSchCH_EndHr, variation-point={short-label=vpIN_NeSCPR_e_NxtSchCH_EndHr_Rx_NeSCPR_e_NxtSchCH_EndHr, sw-syscond=1}
              IN_NeSCPR_e_NxtSchCH_EndMin_Rx_NeSCPR_e_NxtSchCH_EndMin: accessed-variable=NeSCPR_e_NxtSchCH_EndMin_Rx.NeSCPR_e_NxtSchCH_EndMin, variation-point={short-label=vpIN_NeSCPR_e_NxtSchCH_EndMin_Rx_NeSCPR_e_NxtSchCH_EndMin, sw-syscond=1}
              IN_NeSCPR_e_NxtSchCH_StrtDay_Rx_NeSCPR_e_NxtSchCH_StrtDay: accessed-variable=NeSCPR_e_NxtSchCH_StrtDay_Rx.NeSCPR_e_NxtSchCH_StrtDay, variation-point={short-label=vpIN_NeSCPR_e_NxtSchCH_StrtDay_Rx_NeSCPR_e_NxtSchCH_StrtDay, sw-syscond=1}
              IN_NeSCPR_e_NxtSchCH_StrtHr_Rx_NeSCPR_e_NxtSchCH_StrtHr: accessed-variable=NeSCPR_e_NxtSchCH_StrtHr_Rx.NeSCPR_e_NxtSchCH_StrtHr, variation-point={short-label=vpIN_NeSCPR_e_NxtSchCH_StrtHr_Rx_NeSCPR_e_NxtSchCH_StrtHr, sw-syscond=1}
              IN_NeSCPR_e_NxtSchCH_StrtMin_Rx_NeSCPR_e_NxtSchCH_StrtMin: accessed-variable=NeSCPR_e_NxtSchCH_StrtMin_Rx.NeSCPR_e_NxtSchCH_StrtMin, variation-point={short-label=vpIN_NeSCPR_e_NxtSchCH_StrtMin_Rx_NeSCPR_e_NxtSchCH_StrtMin, sw-syscond=1}
              IN_NeSCPR_e_NxtSchCP_Day_Rx_NeSCPR_e_NxtSchCP_Day: accessed-variable=NeSCPR_e_NxtSchCP_Day_Rx.NeSCPR_e_NxtSchCP_Day, variation-point={short-label=vpIN_NeSCPR_e_NxtSchCP_Day_Rx_NeSCPR_e_NxtSchCP_Day, sw-syscond=1}
              IN_NeSCPR_e_NxtSchCP_StrtHr_Rx_NeSCPR_e_NxtSchCP_StrtHr: accessed-variable=NeSCPR_e_NxtSchCP_StrtHr_Rx.NeSCPR_e_NxtSchCP_StrtHr, variation-point={short-label=vpIN_NeSCPR_e_NxtSchCP_StrtHr_Rx_NeSCPR_e_NxtSchCP_StrtHr, sw-syscond=1}
              IN_NeSCPR_e_NxtSchCP_StrtMin_Rx_NeSCPR_e_NxtSchCP_StrtMin: accessed-variable=NeSCPR_e_NxtSchCP_StrtMin_Rx.NeSCPR_e_NxtSchCP_StrtMin, variation-point={short-label=vpIN_NeSCPR_e_NxtSchCP_StrtMin_Rx_NeSCPR_e_NxtSchCP_StrtMin, sw-syscond=1}
              IN_NeSCPR_e_Sch1CH_SchType_Rx_NeSCPR_e_Sch1CH_SchType: accessed-variable=NeSCPR_e_Sch1CH_SchType_Rx.NeSCPR_e_Sch1CH_SchType, variation-point={short-label=vpIN_NeSCPR_e_Sch1CH_SchType_Rx_NeSCPR_e_Sch1CH_SchType, sw-syscond=1}
              IN_NeSCPR_e_Sch1CoCH_StopHr_Rx_NeSCPR_e_Sch1CoCH_StopHr: accessed-variable=NeSCPR_e_Sch1CoCH_StopHr_Rx.NeSCPR_e_Sch1CoCH_StopHr, variation-point={short-label=vpIN_NeSCPR_e_Sch1CoCH_StopHr_Rx_NeSCPR_e_Sch1CoCH_StopHr, sw-syscond=1}
              IN_NeSCPR_e_Sch1CoCH_StopMin_Rx_NeSCPR_e_Sch1CoCH_StopMin: accessed-variable=NeSCPR_e_Sch1CoCH_StopMin_Rx.NeSCPR_e_Sch1CoCH_StopMin, variation-point={short-label=vpIN_NeSCPR_e_Sch1CoCH_StopMin_Rx_NeSCPR_e_Sch1CoCH_StopMin, sw-syscond=1}
              IN_NeSCPR_e_Sch2CH_SchType_Rx_NeSCPR_e_Sch2CH_SchType: accessed-variable=NeSCPR_e_Sch2CH_SchType_Rx.NeSCPR_e_Sch2CH_SchType, variation-point={short-label=vpIN_NeSCPR_e_Sch2CH_SchType_Rx_NeSCPR_e_Sch2CH_SchType, sw-syscond=1}
              IN_NeSCPR_e_Sch2CoCH_StopHr_Rx_NeSCPR_e_Sch2CoCH_StopHr: accessed-variable=NeSCPR_e_Sch2CoCH_StopHr_Rx.NeSCPR_e_Sch2CoCH_StopHr, variation-point={short-label=vpIN_NeSCPR_e_Sch2CoCH_StopHr_Rx_NeSCPR_e_Sch2CoCH_StopHr, sw-syscond=1}
              IN_NeSCPR_e_Sch2CoCH_StopMin_Rx_NeSCPR_e_Sch2CoCH_StopMin: accessed-variable=NeSCPR_e_Sch2CoCH_StopMin_Rx.NeSCPR_e_Sch2CoCH_StopMin, variation-point={short-label=vpIN_NeSCPR_e_Sch2CoCH_StopMin_Rx_NeSCPR_e_Sch2CoCH_StopMin, sw-syscond=1}
              IN_NeSCPR_g_DoNotRepeatValSch1_Rx_NeSCPR_g_DoNotRepeatValSch1: accessed-variable=NeSCPR_g_DoNotRepeatValSch1_Rx.NeSCPR_g_DoNotRepeatValSch1, variation-point={short-label=vpIN_NeSCPR_g_DoNotRepeatValSch1_Rx_NeSCPR_g_DoNotRepeatValSch1, sw-syscond=1}
              IN_NeSCPR_g_DoNotRepeatValSch2_Rx_NeSCPR_g_DoNotRepeatValSch2: accessed-variable=NeSCPR_g_DoNotRepeatValSch2_Rx.NeSCPR_g_DoNotRepeatValSch2, variation-point={short-label=vpIN_NeSCPR_g_DoNotRepeatValSch2_Rx_NeSCPR_g_DoNotRepeatValSch2, sw-syscond=1}
              IN_NeSCPR_g_Sch1CP_DNRvalue_Rx_NeSCPR_g_Sch1CP_DNRvalue: accessed-variable=NeSCPR_g_Sch1CP_DNRvalue_Rx.NeSCPR_g_Sch1CP_DNRvalue, variation-point={short-label=vpIN_NeSCPR_g_Sch1CP_DNRvalue_Rx_NeSCPR_g_Sch1CP_DNRvalue, sw-syscond=1}
              IN_NeSCPR_g_Sch1CoCH_DNRvalue_Rx_NeSCPR_g_Sch1CoCH_DNRvalue: accessed-variable=NeSCPR_g_Sch1CoCH_DNRvalue_Rx.NeSCPR_g_Sch1CoCH_DNRvalue, variation-point={short-label=vpIN_NeSCPR_g_Sch1CoCH_DNRvalue_Rx_NeSCPR_g_Sch1CoCH_DNRvalue, sw-syscond=1}
              IN_NeSCPR_g_Sch2CP_DNRvalue_Rx_NeSCPR_g_Sch2CP_DNRvalue: accessed-variable=NeSCPR_g_Sch2CP_DNRvalue_Rx.NeSCPR_g_Sch2CP_DNRvalue, variation-point={short-label=vpIN_NeSCPR_g_Sch2CP_DNRvalue_Rx_NeSCPR_g_Sch2CP_DNRvalue, sw-syscond=1}
              IN_NeSCPR_g_Sch2CoCH_DNRvalue_Rx_NeSCPR_g_Sch2CoCH_DNRvalue: accessed-variable=NeSCPR_g_Sch2CoCH_DNRvalue_Rx.NeSCPR_g_Sch2CoCH_DNRvalue, variation-point={short-label=vpIN_NeSCPR_g_Sch2CoCH_DNRvalue_Rx_NeSCPR_g_Sch2CoCH_DNRvalue, sw-syscond=1}
              IN_NeSCPR_k_CabinTempSetPoint_Rx_NeSCPR_k_CabinTempSetPoint: accessed-variable=NeSCPR_k_CabinTempSetPoint_Rx.NeSCPR_k_CabinTempSetPoint, variation-point={short-label=vpIN_NeSCPR_k_CabinTempSetPoint_Rx_NeSCPR_k_CabinTempSetPoint, sw-syscond=1}
              IN_NeSCPR_k_CancGlEndTrack_Rx_NeSCPR_k_CancGlEndTrack: accessed-variable=NeSCPR_k_CancGlEndTrack_Rx.NeSCPR_k_CancGlEndTrack, variation-point={short-label=vpIN_NeSCPR_k_CancGlEndTrack_Rx_NeSCPR_k_CancGlEndTrack, sw-syscond=1}
              IN_NeSCPR_k_CancGlStartTrack_Rx_NeSCPR_k_CancGlStartTrack: accessed-variable=NeSCPR_k_CancGlStartTrack_Rx.NeSCPR_k_CancGlStartTrack, variation-point={short-label=vpIN_NeSCPR_k_CancGlStartTrack_Rx_NeSCPR_k_CancGlStartTrack, sw-syscond=1}
              IN_NeSCPR_k_CancOverlapTrack_Rx_NeSCPR_k_CancOverlapTrack: accessed-variable=NeSCPR_k_CancOverlapTrack_Rx.NeSCPR_k_CancOverlapTrack, variation-point={short-label=vpIN_NeSCPR_k_CancOverlapTrack_Rx_NeSCPR_k_CancOverlapTrack, sw-syscond=1}
              IN_NeSCPR_k_LastRTC_Rx_NeSCPR_k_LastRTC: accessed-variable=NeSCPR_k_LastRTC_Rx.NeSCPR_k_LastRTC, variation-point={short-label=vpIN_NeSCPR_k_LastRTC_Rx_NeSCPR_k_LastRTC, sw-syscond=1}
              IN_NeSCPR_k_LastSecond_Rx_NeSCPR_k_LastSecond: accessed-variable=NeSCPR_k_LastSecond_Rx.NeSCPR_k_LastSecond, variation-point={short-label=vpIN_NeSCPR_k_LastSecond_Rx_NeSCPR_k_LastSecond, sw-syscond=1}
              IN_NeSCPR_y_Sch1CoCH_Day_Rx_NeSCPR_y_Sch1CoCH_Day: accessed-variable=NeSCPR_y_Sch1CoCH_Day_Rx.NeSCPR_y_Sch1CoCH_Day, variation-point={short-label=vpIN_NeSCPR_y_Sch1CoCH_Day_Rx_NeSCPR_y_Sch1CoCH_Day, sw-syscond=1}
              IN_NeSCPR_y_Sch2CoCH_Day_Rx_NeSCPR_y_Sch2CoCH_Day: accessed-variable=NeSCPR_y_Sch2CoCH_Day_Rx.NeSCPR_y_Sch2CoCH_Day, variation-point={short-label=vpIN_NeSCPR_y_Sch2CoCH_Day_Rx_NeSCPR_y_Sch2CoCH_Day, sw-syscond=1}
          data-send-points:
            78 x access:
              OUT_VeSCPR_K_Sch1_Start_Time_Hr_Sts_Value: accessed-variable=VeSCPR_K_Sch1_Start_Time_Hr_Sts.Value
              OUT_VeSCPR_K_Sch1_Start_Time_Min_Sts_Value: accessed-variable=VeSCPR_K_Sch1_Start_Time_Min_Sts.Value
              OUT_VeSCPR_K_Sch1_End_Time_Hr_Sts_Value: accessed-variable=VeSCPR_K_Sch1_End_Time_Hr_Sts.Value
              OUT_VeSCPR_K_Sch1_End_Time_Min_Sts_Value: accessed-variable=VeSCPR_K_Sch1_End_Time_Min_Sts.Value
              OUT_VeSCPR_K_Sch1_Day_Sts_Value: accessed-variable=VeSCPR_K_Sch1_Day_Sts.Value
              OUT_VeSCPR_b_Sch1_Confirmed_Value: accessed-variable=VeSCPR_b_Sch1_Confirmed.Value
              OUT_VeSCPR_b_Sch1_ChargeUntilFull_Sts_Value: accessed-variable=VeSCPR_b_Sch1_ChargeUntilFull_Sts.Value
              OUT_VeSCPR_K_Sch2_Start_Time_Hr_Sts_Value: accessed-variable=VeSCPR_K_Sch2_Start_Time_Hr_Sts.Value
              OUT_VeSCPR_K_Sch2_Start_Time_Min_Sts_Value: accessed-variable=VeSCPR_K_Sch2_Start_Time_Min_Sts.Value
              OUT_VeSCPR_K_Sch2_End_Time_Hr_Sts_Value: accessed-variable=VeSCPR_K_Sch2_End_Time_Hr_Sts.Value
              OUT_VeSCPR_K_Sch2_End_Time_Min_Sts_Value: accessed-variable=VeSCPR_K_Sch2_End_Time_Min_Sts.Value
              OUT_VeSCPR_K_Sch2_Day_Sts_Value: accessed-variable=VeSCPR_K_Sch2_Day_Sts.Value
              OUT_VeSCPR_b_Sch2_Confirmed_Value: accessed-variable=VeSCPR_b_Sch2_Confirmed.Value
              OUT_VeSCPR_b_Sch2_ChargeUntilFull_Sts_Value: accessed-variable=VeSCPR_b_Sch2_ChargeUntilFull_Sts.Value
              OUT_VeSCPR_K_Sch3_DepHrSts_Value: accessed-variable=VeSCPR_K_Sch3_DepHrSts.Value
              OUT_VeSCPR_K_Sch3_DepMinSts_Value: accessed-variable=VeSCPR_K_Sch3_DepMinSts.Value
              OUT_VeSCPR_K_Sch3_DaySts_Value: accessed-variable=VeSCPR_K_Sch3_DaySts.Value
              OUT_VeSCPR_b_Sch3_EnblSts_Value: accessed-variable=VeSCPR_b_Sch3_EnblSts.Value
              OUT_VeSCPR_e_Sch3_AllowSts_Value: accessed-variable=VeSCPR_e_Sch3_AllowSts.Value
              OUT_VeSCPR_T_Sch3_DepTempSts_Value: accessed-variable=VeSCPR_T_Sch3_DepTempSts.Value
              OUT_VeSCPR_K_Sch4_DepHrSts_Value: accessed-variable=VeSCPR_K_Sch4_DepHrSts.Value
              OUT_VeSCPR_K_Sch4_DepMinSts_Value: accessed-variable=VeSCPR_K_Sch4_DepMinSts.Value
              OUT_VeSCPR_K_Sch4_DaySts_Value: accessed-variable=VeSCPR_K_Sch4_DaySts.Value
              OUT_VeSCPR_b_Sch4_EnblSts_Value: accessed-variable=VeSCPR_b_Sch4_EnblSts.Value
              OUT_VeSCPR_e_Sch4_AllowSts_Value: accessed-variable=VeSCPR_e_Sch4_AllowSts.Value
              OUT_VeSCPR_T_Sch4_DepTempSts_Value: accessed-variable=VeSCPR_T_Sch4_DepTempSts.Value
              OUT_VeSCPR_T_CabinTempSetPt_Value: accessed-variable=VeSCPR_T_CabinTempSetPt.Value
              OUT_VeSCPR_K_Next_Climate_Time_Hr_Value: accessed-variable=VeSCPR_K_Next_Climate_Time_Hr.Value
              OUT_VeSCPR_K_Next_Climate_Time_Min_Value: accessed-variable=VeSCPR_K_Next_Climate_Time_Min.Value
              OUT_VeSCPR_K_Next_Climate_Day_Value: accessed-variable=VeSCPR_K_Next_Climate_Day.Value
              OUT_VeSCPR_K_Next_SchStart_Time_Hr_Value: accessed-variable=VeSCPR_K_Next_SchStart_Time_Hr.Value
              OUT_VeSCPR_K_Next_SchStart_Time_Min_Value: accessed-variable=VeSCPR_K_Next_SchStart_Time_Min.Value
              OUT_VeSCPR_K_Next_SchEnd_Time_Hr_Value: accessed-variable=VeSCPR_K_Next_SchEnd_Time_Hr.Value
              OUT_VeSCPR_K_Next_SchEnd_Time_Min_Value: accessed-variable=VeSCPR_K_Next_SchEnd_Time_Min.Value
              OUT_VeSCPR_K_Next_Schedule_StartDay_Value: accessed-variable=VeSCPR_K_Next_Schedule_StartDay.Value
              OUT_VeSCPR_K_Next_Schedule_EndDay_Value: accessed-variable=VeSCPR_K_Next_Schedule_EndDay.Value
              OUT_VeSCPR_K_Ext_Next_StopTime_Day_Value: accessed-variable=VeSCPR_K_Ext_Next_StopTime_Day.Value
              OUT_VeSCPR_K_Ext_Next_StopTime_Hr_Value: accessed-variable=VeSCPR_K_Ext_Next_StopTime_Hr.Value
              OUT_VeSCPR_K_Ext_Next_StopTime_Min_Value: accessed-variable=VeSCPR_K_Ext_Next_StopTime_Min.Value
              OUT_VeSCPR_Pct_Ext_Next_ImmedSOC_Trgt_Value: accessed-variable=VeSCPR_Pct_Ext_Next_ImmedSOC_Trgt.Value
              OUT_VeSCPR_Pct_Ext_Next_ExtSOC_Trgt_Value: accessed-variable=VeSCPR_Pct_Ext_Next_ExtSOC_Trgt.Value
              OUT_VeSCPR_Pct_Sch1_ImmedSOC_Trgt_Sts_Value: accessed-variable=VeSCPR_Pct_Sch1_ImmedSOC_Trgt_Sts.Value
              OUT_VeSCPR_Pct_Sch1_ExtSOC_Trgt_Sts_Value: accessed-variable=VeSCPR_Pct_Sch1_ExtSOC_Trgt_Sts.Value
              OUT_VeSCPR_e_Sch1_ChrgSchType_Sts_Value: accessed-variable=VeSCPR_e_Sch1_ChrgSchType_Sts.Value
              OUT_VeSCPR_Pct_Sch2_ImmedSOC_Trgt_Sts_Value: accessed-variable=VeSCPR_Pct_Sch2_ImmedSOC_Trgt_Sts.Value
              OUT_VeSCPR_Pct_Sch2_ExtSOC_Trgt_Sts_Value: accessed-variable=VeSCPR_Pct_Sch2_ExtSOC_Trgt_Sts.Value
              OUT_VeSCPR_e_Sch2_ChrgSchType_Sts_Value: accessed-variable=VeSCPR_e_Sch2_ChrgSchType_Sts.Value
              OUT_VeSCPR_e_CoopChrgStatus_Value: accessed-variable=VeSCPR_e_CoopChrgStatus.Value
              OUT_VeSCPR_e_Next_ChrgSchType_Value: accessed-variable=VeSCPR_e_Next_ChrgSchType.Value
              OUT_VeSCPR_t_TimeToDeparture_Value: accessed-variable=VeSCPR_t_TimeToDeparture.Value
              OUT_VeSCPR_e_SchCP_Allow_Value: accessed-variable=VeSCPR_e_SchCP_Allow.Value
              OUT_VeSCPR_t_SchChrg_WUTime_Value: accessed-variable=VeSCPR_t_SchChrg_WUTime.Value
              OUT_VeSCPR_b_ChargeReq_Value: accessed-variable=VeSCPR_b_ChargeReq.Value
              OUT_VeSCPR_e_CPIM_Icon1_Cmd_Value: accessed-variable=VeSCPR_e_CPIM_Icon1_Cmd.Value
              OUT_VeSCPR_e_CPIM_Icon2_Cmd_Value: accessed-variable=VeSCPR_e_CPIM_Icon2_Cmd.Value
              OUT_VeSCPR_Pct_Est_SOC_Value: accessed-variable=VeSCPR_Pct_Est_SOC.Value
              OUT_VeSCPR_b_NoChrgSchEnbl_Value: accessed-variable=VeSCPR_b_NoChrgSchEnbl.Value
              OUT_VeSCPR_b_ButtonActive_Door_Value: accessed-variable=VeSCPR_b_ButtonActive_Door.Value
              OUT_VeSCPR_b_Sch1_Batt_CabinPriority_Sts_Value: accessed-variable=VeSCPR_b_Sch1_Batt_CabinPriority_Sts.Value
              OUT_VeSCPR_b_Sch1_Do_Not_Repeat_Sts_Value: accessed-variable=VeSCPR_b_Sch1_Do_Not_Repeat_Sts.Value
              OUT_VeSCPR_e_Sch1_Type_Sts_Value: accessed-variable=VeSCPR_e_Sch1_Type_Sts.Value
              OUT_VeSCPR_b_Sch2_Batt_CabinPriority_Sts_Value: accessed-variable=VeSCPR_b_Sch2_Batt_CabinPriority_Sts.Value
              OUT_VeSCPR_b_Sch2_Do_Not_Repeat_Sts_Value: accessed-variable=VeSCPR_b_Sch2_Do_Not_Repeat_Sts.Value
              OUT_VeSCPR_e_Sch2_Type_Sts_Value: accessed-variable=VeSCPR_e_Sch2_Type_Sts.Value
              OUT_VeSCPR_b_Sch3_Batt_CabinPriority_Sts_Value: accessed-variable=VeSCPR_b_Sch3_Batt_CabinPriority_Sts.Value
              OUT_VeSCPR_b_Sch3_ChargeUntilFull_Sts_Value: accessed-variable=VeSCPR_b_Sch3_ChargeUntilFull_Sts.Value
              OUT_VeSCPR_b_Sch3_Do_Not_Repeat_Sts_Value: accessed-variable=VeSCPR_b_Sch3_Do_Not_Repeat_Sts.Value
              OUT_VeSCPR_K_Sch3_End_Time_Hr_Sts_Value: accessed-variable=VeSCPR_K_Sch3_End_Time_Hr_Sts.Value
              OUT_VeSCPR_K_Sch3_End_Time_Min_Sts_Value: accessed-variable=VeSCPR_K_Sch3_End_Time_Min_Sts.Value
              OUT_VeSCPR_b_Sch3_Confirmed_Value: accessed-variable=VeSCPR_b_Sch3_Confirmed.Value
              OUT_VeSCPR_K_Sch3_Day_Sts_Value: accessed-variable=VeSCPR_K_Sch3_Day_Sts.Value
              OUT_VeSCPR_e_Sch3_Type_Sts_Value: accessed-variable=VeSCPR_e_Sch3_Type_Sts.Value
              OUT_VeSCPR_K_Sch3_Start_Time_Hr_Sts_Value: accessed-variable=VeSCPR_K_Sch3_Start_Time_Hr_Sts.Value
              OUT_VeSCPR_K_Sch3_Start_Time_Min_Sts_Value: accessed-variable=VeSCPR_K_Sch3_Start_Time_Min_Sts.Value
              OUT_VeSCPR_b_BattCabinPriority_Value: accessed-variable=VeSCPR_b_BattCabinPriority.Value
              OUT_VeSCPR_b_SchChrg_OktoCharge_Value: accessed-variable=VeSCPR_b_SchChrg_OktoCharge.Value
              OUT_VeSCPR_e_InitStatus_Value: accessed-variable=VeSCPR_e_InitStatus.Value
              OUT_VeSCPR_b_FOTASchCnflct_Value: accessed-variable=VeSCPR_b_FOTASchCnflct.Value
      variation point proxy Variant_SCPR_1: category=CONDITION, condition-access=1
